VERSION "DNNBNNNYNNNNNNNNNNNNNNNNNNNNNNNNNNNNNNNNNN/4/%%%/4/'%**4NNN///"

NS_ :

BS_:

BU_: Vector__XXX xSolarWave xSolarSurveyor xSolarStorm xNova xMiata_SCP xMiata_AGS UI INV_CHG INV GATEWAY EMS DIAG CHG BMS BATTMON AGS

BO_ 2147573248 EmsCfg: 25 DIAG
 SG_ ShoreBreakerRatingMin : 40|16@1+ (0.01,0) [0|655.32] "A" DIAG,EMS,UI
 SG_ ShoreBreakerRatingMax : 56|16@1+ (0.01,0) [0|655.32] "A" DIAG,EMS,UI
 SG_ ShoreBreakerRating : 24|16@1+ (0.01,0) [0|655.32] "A" DIAG,EMS,UI
 SG_ ShoreBreakerMode : 16|2@1+ (1,0) [0|0] "" DIAG,EMS,UI
 SG_ RsvBits : 22|2@1+ (1,0) [0|0] "" DIAG,EMS,UI
 SG_ MsgCount : 2|6@1+ (1,0) [0|0] "" DIAG,EMS,UI
 SG_ GenWarmDelayMin : 160|16@1+ (0.01,0) [0|655.32] "seconds" DIAG,EMS,UI
 SG_ GenWarmDelayMax : 176|16@1+ (0.01,0) [0|655.32] "seconds" DIAG,EMS,UI
 SG_ GenWarmDelay : 144|16@1+ (0.01,0) [0|655.32] "seconds" DIAG,EMS,UI
 SG_ GenBreakerRatingMin : 88|16@1+ (0.01,0) [0|655.32] "A" DIAG,EMS,UI
 SG_ GenBreakerRatingMax : 104|16@1+ (0.01,0) [0|655.32] "A" DIAG,EMS,UI
 SG_ GenBreakerRating : 72|16@1+ (0.01,0) [0|655.32] "A" DIAG,EMS,UI
 SG_ GenBreakerMode : 18|2@1+ (1,0) [0|0] "" DIAG,EMS,UI
 SG_ ConSeqDelayMin : 128|8@1+ (1,0) [0|252] "seconds" DIAG,EMS,UI
 SG_ ConSeqDelayMax : 136|8@1+ (1,0) [0|252] "seconds" DIAG,EMS,UI
 SG_ ConSeqDelay : 120|8@1+ (1,0) [0|252] "seconds" DIAG,EMS,UI
 SG_ ConcurAccCtr : 8|8@1+ (1,0) [0|252] "" DIAG,EMS,UI
 SG_ CfgType : 0|2@1+ (1,0) [0|0] "" DIAG,EMS,UI
 SG_ BreakerDeratingEnDis : 20|2@1+ (1,0) [0|0] "" DIAG,EMS,UI
 SG_ AcDisqualifyPriority : 192|8@1+ (1,0) [0|252] "" DIAG,EMS,UI

BO_ 2147569664 DiagMfgCfg: 9 AGS
 SG_ RsvBits : 0|2@1+ (1,0) [0|0] "" AGS,BATTMON,CHG,DIAG,GATEWAY,INV,INV_CHG,UI,xMiata_AGS,xNova,xSolarSurveyor,xSolarWave
 SG_ MsgCount : 2|6@1+ (1,0) [0|0] "" AGS,BATTMON,CHG,DIAG,GATEWAY,INV,INV_CHG,UI,xMiata_AGS,xNova,xSolarSurveyor,xSolarWave
 SG_ MfgTime : 24|32@1+ (1,0) [0|4.29497E+09] "seconds" AGS,BATTMON,CHG,DIAG,GATEWAY,INV,INV_CHG,UI,xMiata_AGS,xNova,xSolarSurveyor,xSolarWave
 SG_ MfgStep : 16|8@1+ (1,0) [0|252] "" AGS,BATTMON,CHG,DIAG,GATEWAY,INV,INV_CHG,UI,xMiata_AGS,xNova,xSolarSurveyor,xSolarWave
 SG_ LocalOffsetMins : 56|16@1- (1,0) [-32768|32764] "minutes" AGS,BATTMON,CHG,DIAG,GATEWAY,INV,INV_CHG,UI,xMiata_AGS,xNova,xSolarSurveyor,xSolarWave
 SG_ ConcurAccCtr : 8|8@1+ (1,0) [0|252] "" AGS,BATTMON,CHG,DIAG,GATEWAY,INV,INV_CHG,UI,xMiata_AGS,xNova,xSolarSurveyor,xSolarWave

BO_ 2147568128 DiagIndicCmd: 223 DIAG
 SG_ IndicState : 6|2@1+ (1,0) [0|0] "" AGS,BATTMON,CHG,GATEWAY,INV,INV_CHG,UI,xMiata_AGS,xNova,xSolarWave
 SG_ IndicId : 0|6@1+ (1,0) [0|0] "" AGS,BATTMON,CHG,GATEWAY,INV,INV_CHG,UI,xMiata_AGS,xNova,xSolarWave

BO_ 2147568896 DiagFanCmd: 223 DIAG
 SG_ FanSpd : 8|8@1+ (1,0) [0|252] "%" AGS,BATTMON,CHG,DIAG,GATEWAY,INV,INV_CHG,UI,xSolarWave
 SG_ FanId : 0|8@1+ (1,0) [0|252] "" AGS,BATTMON,CHG,DIAG,GATEWAY,INV,INV_CHG,UI,xSolarWave

BO_ 2147568640 DiagCntctSts: 223 AGS
 SG_ RsvBits : 0|2@1+ (1,0) [0|0] "" DIAG
 SG_ MsgCount : 2|6@1+ (1,0) [0|0] "" DIAG
 SG_ CntctState : 14|2@1+ (1,0) [0|0] "" DIAG
 SG_ CntctId : 8|6@1+ (1,0) [0|0] "" DIAG

BO_ 2147568384 DiagCntctCmd: 223 DIAG
 SG_ CntctState : 6|2@1+ (1,0) [0|0] "" AGS,BATTMON,CHG,GATEWAY,INV,INV_CHG,UI,xMiata_AGS,xNova,xSolarWave
 SG_ CntctId : 0|6@1+ (1,0) [0|0] "" AGS,BATTMON,CHG,GATEWAY,INV,INV_CHG,UI,xMiata_AGS,xNova,xSolarWave

BO_ 2147561472 DevPokeAddr: 1785 DIAG
 SG_ StartMemAddr : 8|32@1+ (1,0) [0|4.29497E+09] "" AGS,BATTMON,CHG,GATEWAY,INV,INV_CHG,UI,xMiata_AGS,xSolarSurveyor
 SG_ RsvBits : 4|4@1+ (1,0) [0|0] "" AGS,BATTMON,CHG,GATEWAY,INV,INV_CHG,UI,xMiata_AGS,xSolarSurveyor
 SG_ ProcessorInst : 0|4@1+ (1,0) [0|0] "" AGS,BATTMON,CHG,GATEWAY,INV,INV_CHG,UI,xMiata_AGS,xSolarSurveyor
 SG_ NumBytesSet : 40|16@1+ (1,0) [0|65532] "" AGS,BATTMON,CHG,GATEWAY,INV,INV_CHG,UI,xMiata_AGS,xSolarSurveyor
 SG_ BytesSet : 56|8@1+ (1,0) [0|1785] "8-Bit Bytes" AGS,BATTMON,CHG,GATEWAY,INV,INV_CHG,UI,xMiata_AGS,xSolarSurveyor

BO_ 2147561216 DevPeekAddrRsp: 1785 AGS
 SG_ StartMemAddr : 8|32@1+ (1,0) [0|4.29497E+09] "" DIAG
 SG_ RsvBits : 4|4@1+ (1,0) [0|0] "" DIAG
 SG_ ProcessorInst : 0|4@1+ (1,0) [0|0] "" DIAG
 SG_ NumBytesGot : 40|16@1+ (1,0) [0|65532] "" DIAG
 SG_ BytesGot : 56|8@1+ (1,0) [0|1785] "8-Bit Bytes" DIAG

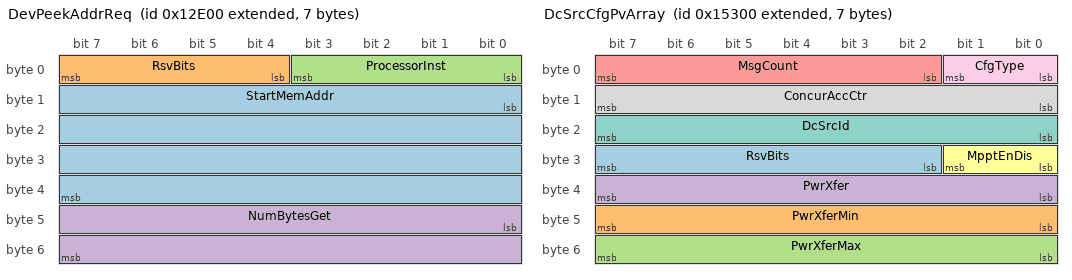
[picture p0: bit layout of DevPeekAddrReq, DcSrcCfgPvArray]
BO_ 2147560960 DevPeekAddrReq: 7 DIAG
 SG_ StartMemAddr : 8|32@1+ (1,0) [0|4.29497E+09] "" AGS,BATTMON,CHG,GATEWAY,INV,INV_CHG,UI,xMiata_AGS,xNova,xSolarSurveyor
 SG_ RsvBits : 4|4@1+ (1,0) [0|0] "" AGS,BATTMON,CHG,GATEWAY,INV,INV_CHG,UI,xMiata_AGS,xNova,xSolarSurveyor
 SG_ ProcessorInst : 0|4@1+ (1,0) [0|0] "" AGS,BATTMON,CHG,GATEWAY,INV,INV_CHG,UI,xMiata_AGS,xNova,xSolarSurveyor
 SG_ NumBytesGet : 40|16@1+ (1,0) [0|65532] "" AGS,BATTMON,CHG,GATEWAY,INV,INV_CHG,UI,xMiata_AGS,xNova,xSolarSurveyor

BO_ 2147563776 DebugFP: 223 AGS
 SG_ Data : 0|8@1+ (1,0) [0|1785] "8-Bit Bytes" AGS,BATTMON,CHG,DIAG,EMS,GATEWAY,INV,INV_CHG,UI,xSolarSurveyor,xSolarWave

BO_ 2147610821 DcSrcSts2: 21 BATTMON
 SG_ Voltage : 16|32@1- (0.001,0) [-2.14748E+06|2.14748E+06] "V" AGS,BATTMON,CHG,DIAG,EMS,GATEWAY,INV,INV_CHG,UI,xSolarSurveyor,xSolarWave
 SG_ RsvBits : 146|6@1+ (1,0) [0|0] "" AGS,BATTMON,CHG,DIAG,EMS,GATEWAY,INV,INV_CHG,UI,xSolarSurveyor,xSolarWave
 SG_ RsvBits : 0|2@1+ (1,0) [0|0] "" AGS,BATTMON,CHG,DIAG,EMS,GATEWAY,INV,INV_CHG,UI,xSolarSurveyor,xSolarWave
 SG_ RippleVoltage : 112|32@1+ (0.001,0) [0|4.29497E+06] "V" AGS,BATTMON,CHG,DIAG,EMS,GATEWAY,INV,INV_CHG,UI,xSolarSurveyor,xSolarWave
 SG_ Pwr : 80|32@1+ (1,0) [0|4.29497E+09] "W" AGS,BATTMON,CHG,DIAG,EMS,GATEWAY,INV,INV_CHG,UI,xSolarSurveyor,xSolarWave
 SG_ MsgCount : 2|6@1+ (1,0) [0|0] "" AGS,BATTMON,CHG,DIAG,EMS,GATEWAY,INV,INV_CHG,UI,xSolarSurveyor,xSolarWave
 SG_ DeratingSts : 144|2@1+ (1,0) [0|0] "" AGS,BATTMON,CHG,DIAG,EMS,GATEWAY,INV,INV_CHG,UI,xSolarSurveyor,xSolarWave
 SG_ DeratingReason : 152|16@1+ (1,0) [0|65532] "" AGS,BATTMON,CHG,DIAG,EMS,GATEWAY,INV,INV_CHG,UI,xSolarSurveyor,xSolarWave
 SG_ DcSrcId : 8|8@1+ (1,0) [0|252] "" AGS,BATTMON,CHG,DIAG,EMS,GATEWAY,INV,INV_CHG,UI,xSolarSurveyor,xSolarWave
 SG_ Current : 48|32@1- (0.001,0) [-2.14748E+06|2.14748E+06] "Amps" AGS,BATTMON,CHG,DIAG,EMS,GATEWAY,INV,INV_CHG,UI,xSolarSurveyor,xSolarWave

BO_ 2147610625 DcSrcSts: 24 BATTMON
 SG_ Voltage : 16|32@1- (0.001,0) [-2.14748E+06|2.14748E+06] "V" AGS,BATTMON,CHG,DIAG,GATEWAY,INV,INV_CHG,UI,xMiata_AGS
 SG_ TimeRemain : 112|16@1+ (1,0) [0|65532] "minutes" AGS,BATTMON,CHG,DIAG,GATEWAY,INV,INV_CHG,UI,xMiata_AGS
 SG_ TempSensId : 80|8@1+ (1,0) [0|252] "" AGS,BATTMON,CHG,DIAG,GATEWAY,INV,INV_CHG,UI,xMiata_AGS
 SG_ Temp : 88|16@1+ (0.01,0) [0|655.32] "°K" AGS,BATTMON,CHG,DIAG,GATEWAY,INV,INV_CHG,UI,xMiata_AGS
 SG_ Soh : 128|8@1+ (1,0) [0|252] "%" AGS,BATTMON,CHG,DIAG,GATEWAY,INV,INV_CHG,UI,xMiata_AGS
 SG_ Soc : 104|8@1+ (1,0) [0|252] "%" AGS,BATTMON,CHG,DIAG,GATEWAY,INV,INV_CHG,UI,xMiata_AGS
 SG_ RsvBits : 0|2@1+ (1,0) [0|0] "" AGS,BATTMON,CHG,DIAG,GATEWAY,INV,INV_CHG,UI,xMiata_AGS
 SG_ Pwr : 160|32@1+ (1,0) [0|4.29497E+09] "W" AGS,BATTMON,CHG,DIAG,GATEWAY,INV,INV_CHG,UI,xMiata_AGS
 SG_ MsgCount : 2|6@1+ (1,0) [0|0] "" AGS,BATTMON,CHG,DIAG,GATEWAY,INV,INV_CHG,UI,xMiata_AGS
 SG_ DcSrcId : 8|8@1+ (1,0) [0|252] "" AGS,BATTMON,CHG,DIAG,GATEWAY,INV,INV_CHG,UI,xMiata_AGS
 SG_ Current : 48|32@1- (0.001,0) [-2.14748E+06|2.14748E+06] "Amps" AGS,BATTMON,CHG,DIAG,GATEWAY,INV,INV_CHG,UI,xMiata_AGS
 SG_ BattCapRemain : 136|16@1+ (1,0) [0|65532] "Ah" AGS,BATTMON,CHG,DIAG,GATEWAY,INV,INV_CHG,UI,xMiata_AGS
 SG_ BattCapPer : 152|8@1+ (1,0) [0|252] "%" AGS,BATTMON,CHG,DIAG,GATEWAY,INV,INV_CHG,UI,xMiata_AGS

BO_ 2147549440 DcSrcCfgUv: 223 BMS
 SG_ UvLvlMin : 88|32@1- (0.001,0) [-2.14748E+06|2.14748E+06] "V" BMS,CHG,DIAG,INV,INV_CHG,UI,xNova,xSolarSurveyor,xSolarWave
 SG_ UvLvlMax : 120|32@1- (0.001,0) [-2.14748E+06|2.14748E+06] "V" BMS,CHG,DIAG,INV,INV_CHG,UI,xNova,xSolarSurveyor,xSolarWave
 SG_ UvLvl : 56|32@1- (0.001,0) [-2.14748E+06|2.14748E+06] "V" BMS,CHG,DIAG,INV,INV_CHG,UI,xNova,xSolarSurveyor,xSolarWave
 SG_ UvIntvlMin : 168|16@1+ (0.01,0) [0|655.32] "seconds" BMS,CHG,DIAG,INV,INV_CHG,UI,xNova,xSolarSurveyor,xSolarWave
 SG_ UvIntvlMax : 184|16@1+ (0.01,0) [0|655.32] "seconds" BMS,CHG,DIAG,INV,INV_CHG,UI,xNova,xSolarSurveyor,xSolarWave
 SG_ UvIntvl : 152|16@1+ (0.01,0) [0|655.32] "seconds" BMS,CHG,DIAG,INV,INV_CHG,UI,xNova,xSolarSurveyor,xSolarWave
 SG_ RefEvtId : 40|16@1+ (1,0) [0|65532] "" BMS,CHG,DIAG,INV,INV_CHG,UI,xNova,xSolarSurveyor,xSolarWave
 SG_ MsgCount : 2|6@1+ (1,0) [0|0] "" BMS,CHG,DIAG,INV,INV_CHG,UI,xNova,xSolarSurveyor,xSolarWave
 SG_ EvtId : 24|16@1+ (1,0) [0|65532] "" BMS,CHG,DIAG,INV,INV_CHG,UI,xNova,xSolarSurveyor,xSolarWave
 SG_ DcSrcId : 16|8@1+ (1,0) [0|252] "" BMS,CHG,DIAG,INV,INV_CHG,UI,xNova,xSolarSurveyor,xSolarWave
 SG_ ConcurAccCtr : 8|8@1+ (1,0) [0|252] "" BMS,CHG,DIAG,INV,INV_CHG,UI,xNova,xSolarSurveyor,xSolarWave
 SG_ CfgType : 0|2@1+ (1,0) [0|0] "" BMS,CHG,DIAG,INV,INV_CHG,UI,xNova,xSolarSurveyor,xSolarWave

BO_ 2147549952 DcSrcCfgUi: 223 CHG
 SG_ UiLvlMin : 88|32@1- (0.001,0) [-2.14748E+06|2.14748E+06] "Amps" CHG,DIAG,INV,INV_CHG,UI
 SG_ UiLvlMax : 120|32@1- (0.001,0) [-2.14748E+06|2.14748E+06] "Amps" CHG,DIAG,INV,INV_CHG,UI
 SG_ UiLvl : 56|32@1- (0.001,0) [-2.14748E+06|2.14748E+06] "Amps" CHG,DIAG,INV,INV_CHG,UI
 SG_ UiIntvlMin : 168|16@1+ (0.01,0) [0|655.32] "seconds" CHG,DIAG,INV,INV_CHG,UI
 SG_ UiIntvlMax : 184|16@1+ (0.01,0) [0|655.32] "seconds" CHG,DIAG,INV,INV_CHG,UI
 SG_ UiIntvl : 152|16@1+ (0.01,0) [0|655.32] "seconds" CHG,DIAG,INV,INV_CHG,UI
 SG_ RefEvtId : 40|16@1+ (1,0) [0|65532] "" CHG,DIAG,INV,INV_CHG,UI
 SG_ MsgCount : 2|6@1+ (1,0) [0|0] "" CHG,DIAG,INV,INV_CHG,UI
 SG_ EvtId : 24|16@1+ (1,0) [0|65532] "" CHG,DIAG,INV,INV_CHG,UI
 SG_ DcSrcId : 16|8@1+ (1,0) [0|252] "" CHG,DIAG,INV,INV_CHG,UI
 SG_ ConcurAccCtr : 8|8@1+ (1,0) [0|252] "" CHG,DIAG,INV,INV_CHG,UI
 SG_ CfgType : 0|2@1+ (1,0) [0|0] "" CHG,DIAG,INV,INV_CHG,UI

BO_ 2147550464 DcSrcCfgRipOvPeak: 223 CHG
 SG_ RefEvtId : 40|16@1+ (1,0) [0|65532] "" CHG,DIAG,INV,INV_CHG,UI
 SG_ PeakRipOvLvlMin : 88|32@1- (0.001,0) [-2.14748E+06|2.14748E+06] "V" CHG,DIAG,INV,INV_CHG,UI
 SG_ PeakRipOvLvlMax : 120|32@1- (0.001,0) [-2.14748E+06|2.14748E+06] "V" CHG,DIAG,INV,INV_CHG,UI
 SG_ PeakRipOvLvl : 56|32@1- (0.001,0) [-2.14748E+06|2.14748E+06] "V" CHG,DIAG,INV,INV_CHG,UI
 SG_ PeakRipOvIntvlMin : 168|16@1+ (0.01,0) [0|655.32] "seconds" CHG,DIAG,INV,INV_CHG,UI
 SG_ PeakRipOvIntvlMax : 184|16@1+ (0.01,0) [0|655.32] "seconds" CHG,DIAG,INV,INV_CHG,UI
 SG_ PeakRipOvIntvl : 152|16@1+ (0.01,0) [0|655.32] "seconds" CHG,DIAG,INV,INV_CHG,UI
 SG_ MsgCount : 2|6@1+ (1,0) [0|0] "" CHG,DIAG,INV,INV_CHG,UI
 SG_ EvtId : 24|16@1+ (1,0) [0|65532] "" CHG,DIAG,INV,INV_CHG,UI
 SG_ DcSrcId : 16|8@1+ (1,0) [0|252] "" CHG,DIAG,INV,INV_CHG,UI
 SG_ ConcurAccCtr : 8|8@1+ (1,0) [0|252] "" CHG,DIAG,INV,INV_CHG,UI
 SG_ CfgType : 0|2@1+ (1,0) [0|0] "" CHG,DIAG,INV,INV_CHG,UI

BO_ 2147599104 DcSrcCfgPvArray2: 19 CHG
 SG_ VMaxPwrMin : 88|32@1- (0.001,0) [-2.14748E+06|2.14748E+06] "V" CHG,DIAG,INV,INV_CHG,UI,xSolarSurveyor
 SG_ VMaxPwrMax : 120|32@1- (0.001,0) [-2.14748E+06|2.14748E+06] "V" CHG,DIAG,INV,INV_CHG,UI,xSolarSurveyor
 SG_ VMaxPwr : 56|32@1- (0.001,0) [-2.14748E+06|2.14748E+06] "V" CHG,DIAG,INV,INV_CHG,UI,xSolarSurveyor
 SG_ RsvBits : 26|6@1+ (1,0) [0|0] "" CHG,DIAG,INV,INV_CHG,UI,xSolarSurveyor
 SG_ PwrXferMin : 40|8@1+ (1,0) [0|252] "%" CHG,DIAG,INV,INV_CHG,UI,xSolarSurveyor
 SG_ PwrXferMax : 48|8@1+ (1,0) [0|252] "%" CHG,DIAG,INV,INV_CHG,UI,xSolarSurveyor
 SG_ PwrXfer : 32|8@1+ (1,0) [0|252] "%" CHG,DIAG,INV,INV_CHG,UI,xSolarSurveyor
 SG_ MsgCount : 2|6@1+ (1,0) [0|0] "" CHG,DIAG,INV,INV_CHG,UI,xSolarSurveyor
 SG_ MpptEnDis : 24|2@1+ (1,0) [0|0] "" CHG,DIAG,INV,INV_CHG,UI,xSolarSurveyor
 SG_ DcSrcId : 16|8@1+ (1,0) [0|252] "" CHG,DIAG,INV,INV_CHG,UI,xSolarSurveyor
 SG_ ConcurAccCtr : 8|8@1+ (1,0) [0|252] "" CHG,DIAG,INV,INV_CHG,UI,xSolarSurveyor
 SG_ CfgType : 0|2@1+ (1,0) [0|0] "" CHG,DIAG,INV,INV_CHG,UI,xSolarSurveyor

BO_ 2147570432 DcSrcCfgPvArray: 7 CHG
 SG_ RsvBits : 26|6@1+ (1,0) [0|0] "" CHG,DIAG,INV,INV_CHG,UI
 SG_ PwrXferMin : 40|8@1+ (1,0) [0|252] "%" CHG,DIAG,INV,INV_CHG,UI
 SG_ PwrXferMax : 48|8@1+ (1,0) [0|252] "%" CHG,DIAG,INV,INV_CHG,UI
 SG_ PwrXfer : 32|8@1+ (1,0) [0|252] "%" CHG,DIAG,INV,INV_CHG,UI
 SG_ MsgCount : 2|6@1+ (1,0) [0|0] "" CHG,DIAG,INV,INV_CHG,UI
 SG_ MpptEnDis : 24|2@1+ (1,0) [0|0] "" CHG,DIAG,INV,INV_CHG,UI
 SG_ DcSrcId : 16|8@1+ (1,0) [0|252] "" CHG,DIAG,INV,INV_CHG,UI
 SG_ ConcurAccCtr : 8|8@1+ (1,0) [0|252] "" CHG,DIAG,INV,INV_CHG,UI
 SG_ CfgType : 0|2@1+ (1,0) [0|0] "" CHG,DIAG,INV,INV_CHG,UI

BO_ 2147549696 DcSrcCfgOv: 223 BMS
 SG_ RefEvtId : 40|16@1+ (1,0) [0|65532] "" BMS,CHG,DIAG,INV,INV_CHG,UI,xNova,xSolarSurveyor,xSolarWave
 SG_ OvLvlMin : 88|32@1- (0.001,0) [-2.14748E+06|2.14748E+06] "V" BMS,CHG,DIAG,INV,INV_CHG,UI,xNova,xSolarSurveyor,xSolarWave
 SG_ OvLvlMax : 120|32@1- (0.001,0) [-2.14748E+06|2.14748E+06] "V" BMS,CHG,DIAG,INV,INV_CHG,UI,xNova,xSolarSurveyor,xSolarWave
 SG_ OvLvl : 56|32@1- (0.001,0) [-2.14748E+06|2.14748E+06] "V" BMS,CHG,DIAG,INV,INV_CHG,UI,xNova,xSolarSurveyor,xSolarWave
 SG_ OvIntvlMin : 168|16@1+ (0.01,0) [0|655.32] "seconds" BMS,CHG,DIAG,INV,INV_CHG,UI,xNova,xSolarSurveyor,xSolarWave
 SG_ OvIntvlMax : 184|16@1+ (0.01,0) [0|655.32] "seconds" BMS,CHG,DIAG,INV,INV_CHG,UI,xNova,xSolarSurveyor,xSolarWave
 SG_ OvIntvl : 152|16@1+ (0.01,0) [0|655.32] "seconds" BMS,CHG,DIAG,INV,INV_CHG,UI,xNova,xSolarSurveyor,xSolarWave
 SG_ MsgCount : 2|6@1+ (1,0) [0|0] "" BMS,CHG,DIAG,INV,INV_CHG,UI,xNova,xSolarSurveyor,xSolarWave
 SG_ EvtId : 24|16@1+ (1,0) [0|65532] "" BMS,CHG,DIAG,INV,INV_CHG,UI,xNova,xSolarSurveyor,xSolarWave
 SG_ DcSrcId : 16|8@1+ (1,0) [0|252] "" BMS,CHG,DIAG,INV,INV_CHG,UI,xNova,xSolarSurveyor,xSolarWave
 SG_ ConcurAccCtr : 8|8@1+ (1,0) [0|252] "" BMS,CHG,DIAG,INV,INV_CHG,UI,xNova,xSolarSurveyor,xSolarWave
 SG_ CfgType : 0|2@1+ (1,0) [0|0] "" BMS,CHG,DIAG,INV,INV_CHG,UI,xNova,xSolarSurveyor,xSolarWave

BO_ 2147550208 DcSrcCfgOi: 223 CHG
 SG_ RefEvtId : 40|16@1+ (1,0) [0|65532] "" CHG,DIAG,INV,INV_CHG,UI
 SG_ OiLvlMin : 88|32@1- (0.001,0) [-2.14748E+06|2.14748E+06] "Amps" CHG,DIAG,INV,INV_CHG,UI
 SG_ OiLvlMax : 120|32@1- (0.001,0) [-2.14748E+06|2.14748E+06] "Amps" CHG,DIAG,INV,INV_CHG,UI
 SG_ OiLvl : 56|32@1- (0.001,0) [-2.14748E+06|2.14748E+06] "Amps" CHG,DIAG,INV,INV_CHG,UI
 SG_ OiIntvlMin : 168|16@1+ (0.01,0) [0|655.32] "seconds" CHG,DIAG,INV,INV_CHG,UI
 SG_ OiIntvlMax : 184|16@1+ (0.01,0) [0|655.32] "seconds" CHG,DIAG,INV,INV_CHG,UI
 SG_ OiIntvl : 152|16@1+ (0.01,0) [0|655.32] "seconds" CHG,DIAG,INV,INV_CHG,UI
 SG_ MsgCount : 2|6@1+ (1,0) [0|0] "" CHG,DIAG,INV,INV_CHG,UI
 SG_ EvtId : 24|16@1+ (1,0) [0|65532] "" CHG,DIAG,INV,INV_CHG,UI
 SG_ DcSrcId : 16|8@1+ (1,0) [0|252] "" CHG,DIAG,INV,INV_CHG,UI
 SG_ ConcurAccCtr : 8|8@1+ (1,0) [0|252] "" CHG,DIAG,INV,INV_CHG,UI
 SG_ CfgType : 0|2@1+ (1,0) [0|0] "" CHG,DIAG,INV,INV_CHG,UI

BO_ 2147556608 DcSrcCfgBatt: 24 BATTMON
 SG_ PeukertExponentMin : 152|8@1+ (0.002,1) [1|1.5] "" BATTMON,BMS,CHG,DIAG,EMS,INV,INV_CHG,UI,xNova,xSolarSurveyor,xSolarWave
 SG_ PeukertExponentMax : 160|8@1+ (0.002,1) [1|1.5] "" BATTMON,BMS,CHG,DIAG,EMS,INV,INV_CHG,UI,xNova,xSolarSurveyor,xSolarWave
 SG_ PeukertExponent : 144|8@1+ (0.002,1) [1|1.5] "" BATTMON,BMS,CHG,DIAG,EMS,INV,INV_CHG,UI,xNova,xSolarSurveyor,xSolarWave
 SG_ NomV : 32|32@1- (0.001,0) [-2.14748E+06|2.14748E+06] "V" BATTMON,BMS,CHG,DIAG,EMS,INV,INV_CHG,UI,xNova,xSolarSurveyor,xSolarWave
 SG_ MsgCount : 2|6@1+ (1,0) [0|0] "" BATTMON,BMS,CHG,DIAG,EMS,INV,INV_CHG,UI,xNova,xSolarSurveyor,xSolarWave
 SG_ DcSrcId : 16|8@1+ (1,0) [0|252] "" BATTMON,BMS,CHG,DIAG,EMS,INV,INV_CHG,UI,xNova,xSolarSurveyor,xSolarWave
 SG_ ConcurAccCtr : 8|8@1+ (1,0) [0|252] "" BATTMON,BMS,CHG,DIAG,EMS,INV,INV_CHG,UI,xNova,xSolarSurveyor,xSolarWave
 SG_ ChgEfficFactorMin : 176|8@1- (1,0) [-124|124] "%" BATTMON,BMS,CHG,DIAG,EMS,INV,INV_CHG,UI,xNova,xSolarSurveyor,xSolarWave
 SG_ ChgEfficFactorMax : 184|8@1- (1,0) [-124|124] "%" BATTMON,BMS,CHG,DIAG,EMS,INV,INV_CHG,UI,xNova,xSolarSurveyor,xSolarWave
 SG_ ChgEfficFactor : 168|8@1- (1,0) [-124|124] "%" BATTMON,BMS,CHG,DIAG,EMS,INV,INV_CHG,UI,xNova,xSolarSurveyor,xSolarWave
 SG_ CfgType : 0|2@1+ (1,0) [0|0] "" BATTMON,BMS,CHG,DIAG,EMS,INV,INV_CHG,UI,xNova,xSolarSurveyor,xSolarWave
 SG_ BattType : 24|8@1+ (1,0) [0|252] "" BATTMON,BMS,CHG,DIAG,EMS,INV,INV_CHG,UI,xNova,xSolarSurveyor,xSolarWave
 SG_ BattTempCoeffMin : 120|8@1+ (0.001,0) [0|0.252] "V/K" BATTMON,BMS,CHG,DIAG,EMS,INV,INV_CHG,UI,xNova,xSolarSurveyor,xSolarWave
 SG_ BattTempCoeffMax : 128|8@1+ (0.001,0) [0|0.252] "V/K" BATTMON,BMS,CHG,DIAG,EMS,INV,INV_CHG,UI,xNova,xSolarSurveyor,xSolarWave
 SG_ BattTempCoeff : 112|8@1+ (0.001,0) [0|0.252] "V/K" BATTMON,BMS,CHG,DIAG,EMS,INV,INV_CHG,UI,xNova,xSolarSurveyor,xSolarWave
 SG_ BattChem : 136|8@1+ (1,0) [0|252] "" BATTMON,BMS,CHG,DIAG,EMS,INV,INV_CHG,UI,xNova,xSolarSurveyor,xSolarWave
 SG_ BattAmpHrRatingMin : 80|16@1+ (1,0) [0|65532] "Ah" BATTMON,BMS,CHG,DIAG,EMS,INV,INV_CHG,UI,xNova,xSolarSurveyor,xSolarWave
 SG_ BattAmpHrRatingMax : 96|16@1+ (1,0) [0|65532] "Ah" BATTMON,BMS,CHG,DIAG,EMS,INV,INV_CHG,UI,xNova,xSolarSurveyor,xSolarWave
 SG_ BattAmpHrRating : 64|16@1+ (1,0) [0|65532] "Ah" BATTMON,BMS,CHG,DIAG,EMS,INV,INV_CHG,UI,xNova,xSolarSurveyor,xSolarWave

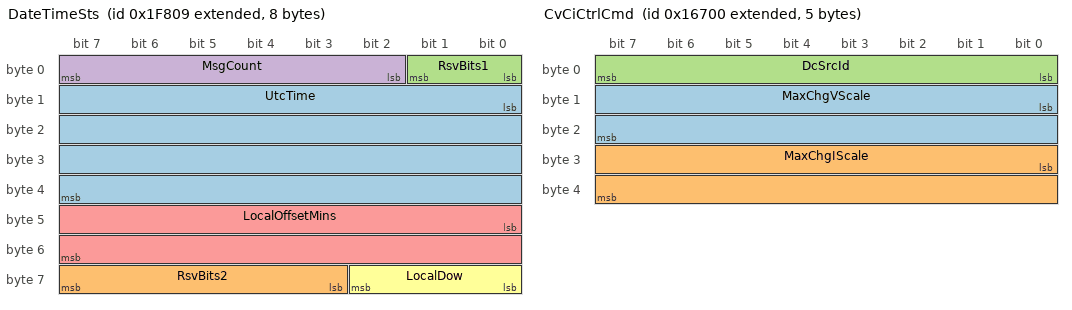
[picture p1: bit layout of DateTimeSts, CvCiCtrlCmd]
BO_ 2147612681 DateTimeSts: 8 DIAG
 SG_ UtcTime : 8|32@1+ (1,0) [0|4.29497E+09] "seconds" AGS,BATTMON,BMS,CHG,DIAG,EMS,GATEWAY,INV,INV_CHG,UI,xMiata_AGS,xNova,xSolarSurveyor,xSolarWave
 SG_ RsvBits2 : 59|5@1+ (1,0) [0|0] "" AGS,BATTMON,BMS,CHG,DIAG,EMS,GATEWAY,INV,INV_CHG,UI,xMiata_AGS,xNova,xSolarSurveyor,xSolarWave
 SG_ RsvBits1 : 0|2@1+ (1,0) [0|0] "" AGS,BATTMON,BMS,CHG,DIAG,EMS,GATEWAY,INV,INV_CHG,UI,xMiata_AGS,xNova,xSolarSurveyor,xSolarWave
 SG_ MsgCount : 2|6@1+ (1,0) [0|0] "" AGS,BATTMON,BMS,CHG,DIAG,EMS,GATEWAY,INV,INV_CHG,UI,xMiata_AGS,xNova,xSolarSurveyor,xSolarWave
 SG_ LocalOffsetMins : 40|16@1- (1,0) [-32768|32764] "minutes" AGS,BATTMON,BMS,CHG,DIAG,EMS,GATEWAY,INV,INV_CHG,UI,xMiata_AGS,xNova,xSolarSurveyor,xSolarWave
 SG_ LocalDow : 56|3@1+ (1,0) [0|0] "" AGS,BATTMON,BMS,CHG,DIAG,EMS,GATEWAY,INV,INV_CHG,UI,xMiata_AGS,xNova,xSolarSurveyor,xSolarWave

BO_ 2147567616 DateTimeCfg: 9 DIAG
 SG_ UtcTime : 16|32@1+ (1,0) [0|4.29497E+09] "seconds" DIAG,UI,xSolarWave
 SG_ RsvBits : 67|5@1+ (1,0) [0|0] "" DIAG,UI,xSolarWave
 SG_ MsgCount : 2|6@1+ (1,0) [0|0] "" DIAG,UI,xSolarWave
 SG_ LocalOffsetMins : 48|16@1- (1,0) [-32768|32764] "minutes" DIAG,UI,xSolarWave
 SG_ LocalDow : 64|3@1+ (1,0) [0|0] "" DIAG,UI,xSolarWave
 SG_ ConcurAccCtr : 8|8@1+ (1,0) [0|252] "" DIAG,UI,xSolarWave
 SG_ CfgType : 0|2@1+ (1,0) [0|0] "" DIAG,UI,xSolarWave

BO_ 2147575552 CvCiCtrlCmd: 5 DIAG
 SG_ MaxChgVScale : 8|16@1+ (0.01,0) [0|655.32] "%" CHG,INV_CHG,xSolarSurveyor,xSolarWave
 SG_ MaxChgIScale : 24|16@1+ (0.01,0) [0|655.32] "%" CHG,INV_CHG,xSolarSurveyor,xSolarWave
 SG_ DcSrcId : 0|8@1+ (1,0) [0|252] "" CHG,INV_CHG,xSolarSurveyor,xSolarWave

BO_ 2147565568 CtrlCmd: 1 BMS
 SG_ DesiredMode : 0|8@1+ (1,0) [0|252] "" AGS,BATTMON,BMS,CHG,EMS,GATEWAY,INV,INV_CHG,UI,xMiata_AGS,xNova,xSolarSurveyor,xSolarWave

BO_ 2147606016 ComplexReq: 1785 DIAG
 SG_ ParamGrpNum : 0|24@1+ (1,0) [0|0] "" AGS,BATTMON,CHG,DIAG,EMS,GATEWAY,INV,INV_CHG,UI,xSolarSurveyor,xSolarWave
 SG_ FieldValue : 32|32@1+ (1,0) [0|4.29497E+09] "" AGS,BATTMON,CHG,DIAG,EMS,GATEWAY,INV,INV_CHG,UI,xSolarSurveyor,xSolarWave
 SG_ Field : 24|8@1+ (1,0) [0|252] "" AGS,BATTMON,CHG,DIAG,EMS,GATEWAY,INV,INV_CHG,UI,xSolarSurveyor,xSolarWave

BO_ 2147610626 CommStats: 25 AGS
 SG_ TxFrameDropCnt : 136|16@1+ (1,0) [0|65532] "" DIAG,UI
 SG_ TxExtFrameCnt : 8|32@1+ (1,0) [0|4.29497E+09] "" DIAG,UI
 SG_ TxErrCnt : 88|16@1+ (1,0) [0|65532] "" DIAG,UI
 SG_ RxFrameDropCnt : 120|16@1+ (1,0) [0|65532] "" DIAG,UI
 SG_ RxExtFrameCnt : 40|32@1+ (1,0) [0|4.29497E+09] "" DIAG,UI
 SG_ RxErrCnt : 72|16@1+ (1,0) [0|65532] "" DIAG,UI
 SG_ RsvBits : 0|2@1+ (1,0) [0|0] "" DIAG,UI
 SG_ MsgCount : 2|6@1+ (1,0) [0|0] "" DIAG,UI
 SG_ MpToCnt : 168|8@1+ (1,0) [0|252] "" DIAG,UI
 SG_ MpLateFrameCnt : 176|8@1+ (1,0) [0|252] "" DIAG,UI
 SG_ MemAllocFailCnt : 152|16@1+ (1,0) [0|65532] "" DIAG,UI
 SG_ HeapFreeMin : 184|16@1+ (1,0) [0|65532] "" DIAG,UI
 SG_ BusOffCnt : 104|16@1+ (1,0) [0|65532] "" DIAG,UI

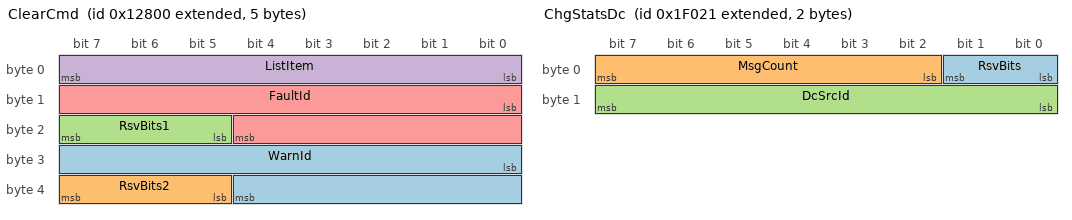
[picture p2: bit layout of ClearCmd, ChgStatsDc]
BO_ 2147559424 ClearCmd: 5 DIAG
 SG_ WarnId : 24|13@1+ (1,0) [0|0] "" AGS,BATTMON,BMS,CHG,DIAG,EMS,GATEWAY,INV,INV_CHG,UI,xMiata_AGS,xNova,xSolarSurveyor,xSolarWave
 SG_ RsvBits2 : 37|3@1+ (1,0) [0|0] "" AGS,BATTMON,BMS,CHG,DIAG,EMS,GATEWAY,INV,INV_CHG,UI,xMiata_AGS,xNova,xSolarSurveyor,xSolarWave
 SG_ RsvBits1 : 21|3@1+ (1,0) [0|0] "" AGS,BATTMON,BMS,CHG,DIAG,EMS,GATEWAY,INV,INV_CHG,UI,xMiata_AGS,xNova,xSolarSurveyor,xSolarWave
 SG_ ListItem : 0|8@1+ (1,0) [0|252] "" AGS,BATTMON,BMS,CHG,DIAG,EMS,GATEWAY,INV,INV_CHG,UI,xMiata_AGS,xNova,xSolarSurveyor,xSolarWave
 SG_ FaultId : 8|13@1+ (1,0) [0|0] "" AGS,BATTMON,BMS,CHG,DIAG,EMS,GATEWAY,INV,INV_CHG,UI,xMiata_AGS,xNova,xSolarSurveyor,xSolarWave

BO_ 2147610638 ChgSts: 17 CHG
 SG_ RsvBits2 : 126|2@1+ (1,0) [0|0] "" AGS,BATTMON,BMS,CHG,DIAG,GATEWAY,INV,INV_CHG,UI,xMiata_AGS,xSolarSurveyor,xSolarWave
 SG_ RsvBits1 : 0|2@1+ (1,0) [0|0] "" AGS,BATTMON,BMS,CHG,DIAG,GATEWAY,INV,INV_CHG,UI,xMiata_AGS,xSolarSurveyor,xSolarWave
 SG_ OpState : 96|16@1+ (1,0) [0|65532] "" AGS,BATTMON,BMS,CHG,DIAG,GATEWAY,INV,INV_CHG,UI,xMiata_AGS,xSolarSurveyor,xSolarWave
 SG_ MsgCount : 2|6@1+ (1,0) [0|0] "" AGS,BATTMON,BMS,CHG,DIAG,GATEWAY,INV,INV_CHG,UI,xMiata_AGS,xSolarSurveyor,xSolarWave
 SG_ EqlzTimeRemain : 128|8@1+ (1,0) [0|252] "minutes" AGS,BATTMON,BMS,CHG,DIAG,GATEWAY,INV,INV_CHG,UI,xMiata_AGS,xSolarSurveyor,xSolarWave
 SG_ EqlzPending : 124|2@1+ (1,0) [0|0] "" AGS,BATTMON,BMS,CHG,DIAG,GATEWAY,INV,INV_CHG,UI,xMiata_AGS,xSolarSurveyor,xSolarWave
 SG_ DcSrcId : 8|8@1+ (1,0) [0|252] "" AGS,BATTMON,BMS,CHG,DIAG,GATEWAY,INV,INV_CHG,UI,xMiata_AGS,xSolarSurveyor,xSolarWave
 SG_ CtrlV : 16|32@1- (0.001,0) [-2.14748E+06|2.14748E+06] "V" AGS,BATTMON,BMS,CHG,DIAG,GATEWAY,INV,INV_CHG,UI,xMiata_AGS,xSolarSurveyor,xSolarWave
 SG_ CtrlIPer : 80|8@1+ (1,0) [0|252] "%" AGS,BATTMON,BMS,CHG,DIAG,GATEWAY,INV,INV_CHG,UI,xMiata_AGS,xSolarSurveyor,xSolarWave
 SG_ CtrlI : 48|32@1- (0.001,0) [-2.14748E+06|2.14748E+06] "Amps" AGS,BATTMON,BMS,CHG,DIAG,GATEWAY,INV,INV_CHG,UI,xMiata_AGS,xSolarSurveyor,xSolarWave
 SG_ ChgMode : 112|8@1+ (1,0) [0|252] "" AGS,BATTMON,BMS,CHG,DIAG,GATEWAY,INV,INV_CHG,UI,xMiata_AGS,xSolarSurveyor,xSolarWave
 SG_ ChgEnDis : 120|2@1+ (1,0) [0|0] "" AGS,BATTMON,BMS,CHG,DIAG,GATEWAY,INV,INV_CHG,UI,xMiata_AGS,xSolarSurveyor,xSolarWave
 SG_ ChgAlgorithm : 88|8@1+ (1,0) [0|252] "" AGS,BATTMON,BMS,CHG,DIAG,GATEWAY,INV,INV_CHG,UI,xMiata_AGS,xSolarSurveyor,xSolarWave
 SG_ BattTempSensorPresent : 122|2@1+ (1,0) [0|0] "" AGS,BATTMON,BMS,CHG,DIAG,GATEWAY,INV,INV_CHG,UI,xMiata_AGS,xSolarSurveyor,xSolarWave

BO_ 2147610658 ChgStatsIntTemp: 223 CHG
 SG_ TempSensId : 8|8@1+ (1,0) [0|252] "" DIAG,UI
 SG_ TempMax : 16|16@1+ (0.01,0) [0|655.32] "°K" DIAG,UI
 SG_ RsvBits : 0|2@1+ (1,0) [0|0] "" DIAG,UI
 SG_ MsgCount : 2|6@1+ (1,0) [0|0] "" DIAG,UI

BO_ 2147610659 ChgStatsExtTemp: 223 CHG
 SG_ TempSensId : 8|8@1+ (1,0) [0|252] "" DIAG,UI
 SG_ TempMin : 16|16@1+ (0.01,0) [0|655.32] "°K" DIAG,UI
 SG_ TempMax : 32|16@1+ (0.01,0) [0|655.32] "°K" DIAG,UI
 SG_ RsvBits : 0|2@1+ (1,0) [0|0] "" DIAG,UI
 SG_ MsgCount : 2|6@1+ (1,0) [0|0] "" DIAG,UI

BO_ 2147610817 ChgStatsDc2: 223 CHG
 SG_ VoltageMin : 56|32@1- (0.001,0) [-2.14748E+06|2.14748E+06] "V" DIAG,UI
 SG_ VoltageMax : 88|32@1- (0.001,0) [-2.14748E+06|2.14748E+06] "V" DIAG,UI
 SG_ RsvBits : 0|2@1+ (1,0) [0|0] "" DIAG,UI
 SG_ PreviousPeriodCount : 19|5@1+ (1,0) [0|0] "" DIAG,UI
 SG_ PreviousPeriod : 16|3@1+ (1,0) [0|0] "" DIAG,UI
 SG_ PeakPower : 152|16@1+ (1,0) [0|65532] "W" DIAG,UI
 SG_ MsgCount : 2|6@1+ (1,0) [0|0] "" DIAG,UI
 SG_ Energy : 120|32@1+ (1,0) [0|4.29497E+09] "W h" DIAG,UI
 SG_ DcSrcId : 8|8@1+ (1,0) [0|252] "" DIAG,UI
 SG_ CurrentMax : 24|32@1- (0.001,0) [-2.14748E+06|2.14748E+06] "Amps" DIAG,UI

BO_ 2147610657 ChgStatsDc: 2 CHG
 SG_ RsvBits : 0|2@1+ (1,0) [0|0] "" DIAG,UI
 SG_ MsgCount : 2|6@1+ (1,0) [0|0] "" DIAG,UI
 SG_ DcSrcId : 8|8@1+ (1,0) [0|252] "" DIAG,UI

BO_ 2147610814 ChgStatsBatt2: 223 CHG
 SG_ VoltageMin : 88|32@1- (0.001,0) [-2.14748E+06|2.14748E+06] "V" DIAG,UI,xSolarSurveyor,xSolarWave
 SG_ VoltageMax : 120|32@1- (0.001,0) [-2.14748E+06|2.14748E+06] "V" DIAG,UI,xSolarSurveyor,xSolarWave
 SG_ RsvBits : 0|2@1+ (1,0) [0|0] "" DIAG,UI,xSolarSurveyor,xSolarWave
 SG_ PreviousPeriodCount : 51|5@1+ (1,0) [0|0] "" DIAG,UI,xSolarSurveyor,xSolarWave
 SG_ PreviousPeriod : 48|3@1+ (1,0) [0|0] "" DIAG,UI,xSolarSurveyor,xSolarWave
 SG_ PeakPower : 248|16@1+ (1,0) [0|65532] "W" DIAG,UI,xSolarSurveyor,xSolarWave
 SG_ MsgCount : 2|6@1+ (1,0) [0|0] "" DIAG,UI,xSolarSurveyor,xSolarWave
 SG_ LastEqualized : 16|32@1+ (1,0) [0|4.29497E+09] "seconds" DIAG,UI,xSolarSurveyor,xSolarWave
 SG_ FloatTime : 216|32@1+ (1,0) [0|4.29497E+09] "seconds" DIAG,UI,xSolarSurveyor,xSolarWave
 SG_ Energy : 184|32@1+ (1,0) [0|4.29497E+09] "W h" DIAG,UI,xSolarSurveyor,xSolarWave
 SG_ DcSrcId : 8|8@1+ (1,0) [0|252] "" DIAG,UI,xSolarSurveyor,xSolarWave
 SG_ CurrentMax : 56|32@1- (0.001,0) [-2.14748E+06|2.14748E+06] "Amps" DIAG,UI,xSolarSurveyor,xSolarWave
 SG_ CapacityReturned : 152|32@1- (1,0) [-2.14748E+09|2.14748E+09] "Ah" DIAG,UI,xSolarSurveyor,xSolarWave

BO_ 2147610816 ChgStatsAc2: 223 CHG
 SG_ VoltageMin : 96|32@1+ (0.001,0) [0|4.29497E+06] "V" DIAG,UI
 SG_ VoltageMax : 128|32@1+ (0.001,0) [0|4.29497E+06] "V" DIAG,UI
 SG_ RsvBits : 0|2@1+ (1,0) [0|0] "" DIAG,UI
 SG_ PreviousPeriodCount : 19|5@1+ (1,0) [0|0] "" DIAG,UI
 SG_ PreviousPeriod : 16|3@1+ (1,0) [0|0] "" DIAG,UI
 SG_ MsgCount : 2|6@1+ (1,0) [0|0] "" DIAG,UI
 SG_ Line : 24|8@1+ (1,0) [0|252] "" DIAG,UI
 SG_ FreqMin : 32|16@1+ (0.01,0) [0|655.32] "Hz" DIAG,UI
 SG_ FreqMax : 48|16@1+ (0.01,0) [0|655.32] "Hz" DIAG,UI
 SG_ CurrentMax : 64|32@1+ (0.001,0) [0|4.29497E+06] "Amps" DIAG,UI
 SG_ AcSrcId : 8|8@1+ (1,0) [0|252] "" DIAG,UI

BO_ 2147610650 ChgStatsAc: 223 CHG
 SG_ VoltageMin : 88|32@1+ (0.001,0) [0|4.29497E+06] "V" DIAG,UI
 SG_ VoltageMax : 120|32@1+ (0.001,0) [0|4.29497E+06] "V" DIAG,UI
 SG_ RsvBits : 0|2@1+ (1,0) [0|0] "" DIAG,UI
 SG_ MsgCount : 2|6@1+ (1,0) [0|0] "" DIAG,UI
 SG_ Line : 16|8@1+ (1,0) [0|252] "" DIAG,UI
 SG_ FreqMin : 24|16@1+ (0.01,0) [0|655.32] "Hz" DIAG,UI
 SG_ FreqMax : 40|16@1+ (0.01,0) [0|655.32] "Hz" DIAG,UI
 SG_ CurrentMax : 56|32@1+ (0.001,0) [0|4.29497E+06] "Amps" DIAG,UI
 SG_ AcSrcId : 8|8@1+ (1,0) [0|252] "" DIAG,UI

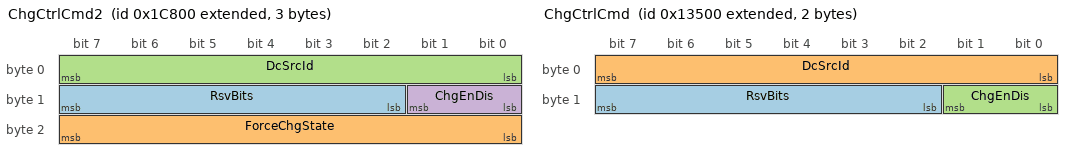
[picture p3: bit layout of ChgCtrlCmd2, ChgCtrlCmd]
BO_ 2147600384 ChgCtrlCmd2: 3 BMS
 SG_ RsvBits : 10|6@1+ (1,0) [0|0] "" CHG,INV_CHG,xNova,xSolarSurveyor,xSolarWave
 SG_ ForceChgState : 16|8@1+ (1,0) [0|252] "" CHG,INV_CHG,xNova,xSolarSurveyor,xSolarWave
 SG_ DcSrcId : 0|8@1+ (1,0) [0|252] "" CHG,INV_CHG,xNova,xSolarSurveyor,xSolarWave
 SG_ ChgEnDis : 8|2@1+ (1,0) [0|0] "" CHG,INV_CHG,xNova,xSolarSurveyor,xSolarWave

BO_ 2147562752 ChgCtrlCmd: 2 DIAG
 SG_ RsvBits : 10|6@1+ (1,0) [0|0] "" CHG,INV_CHG,xNova
 SG_ DcSrcId : 0|8@1+ (1,0) [0|252] "" CHG,INV_CHG,xNova
 SG_ ChgEnDis : 8|2@1+ (1,0) [0|0] "" CHG,INV_CHG,xNova

BO_ 2147555584 ChgCfgOvercharge: 34 CHG
 SG_ OChgPeriodToMin : 240|16@1+ (1,0) [0|65532] "seconds" CHG,DIAG,INV_CHG,UI
 SG_ OChgPeriodToMax : 256|16@1+ (1,0) [0|65532] "seconds" CHG,DIAG,INV_CHG,UI
 SG_ OChgPeriodTo : 224|16@1+ (1,0) [0|65532] "seconds" CHG,DIAG,INV_CHG,UI
 SG_ MsgCount : 2|6@1+ (1,0) [0|0] "" CHG,DIAG,INV_CHG,UI
 SG_ DesiredOChgVMin : 64|32@1- (0.001,0) [-2.14748E+06|2.14748E+06] "V" CHG,DIAG,INV_CHG,UI
 SG_ DesiredOChgVMax : 96|32@1- (0.001,0) [-2.14748E+06|2.14748E+06] "V" CHG,DIAG,INV_CHG,UI
 SG_ DesiredOChgV : 32|32@1- (0.001,0) [-2.14748E+06|2.14748E+06] "V" CHG,DIAG,INV_CHG,UI
 SG_ DesiredOChgIMin : 160|32@1- (0.001,0) [-2.14748E+06|2.14748E+06] "Amps" CHG,DIAG,INV_CHG,UI
 SG_ DesiredOChgIMax : 192|32@1- (0.001,0) [-2.14748E+06|2.14748E+06] "Amps" CHG,DIAG,INV_CHG,UI
 SG_ DesiredOChgI : 128|32@1- (0.001,0) [-2.14748E+06|2.14748E+06] "Amps" CHG,DIAG,INV_CHG,UI
 SG_ DcSrcId : 16|8@1+ (1,0) [0|252] "" CHG,DIAG,INV_CHG,UI
 SG_ ConcurAccCtr : 8|8@1+ (1,0) [0|252] "" CHG,DIAG,INV_CHG,UI
 SG_ CfgType : 0|2@1+ (1,0) [0|0] "" CHG,DIAG,INV_CHG,UI
 SG_ BattType : 24|8@1+ (1,0) [0|252] "" CHG,DIAG,INV_CHG,UI

BO_ 2147559168 ChgCfgMultipleNodes: 32 CHG
 SG_ NomDcVMin : 48|32@1- (0.001,0) [-2.14748E+06|2.14748E+06] "V" CHG,DIAG,INV_CHG,UI,xSolarWave
 SG_ NomDcVMax : 80|32@1- (0.001,0) [-2.14748E+06|2.14748E+06] "V" CHG,DIAG,INV_CHG,UI,xSolarWave
 SG_ NomDcV : 16|32@1- (0.001,0) [-2.14748E+06|2.14748E+06] "V" CHG,DIAG,INV_CHG,UI,xSolarWave
 SG_ MsgCount : 2|6@1+ (1,0) [0|0] "" CHG,DIAG,INV_CHG,UI,xSolarWave
 SG_ MaxDcIMin : 144|32@1- (0.001,0) [-2.14748E+06|2.14748E+06] "Amps" CHG,DIAG,INV_CHG,UI,xSolarWave
 SG_ MaxDcIMax : 176|32@1- (0.001,0) [-2.14748E+06|2.14748E+06] "Amps" CHG,DIAG,INV_CHG,UI,xSolarWave
 SG_ MaxDcI : 112|32@1- (0.001,0) [-2.14748E+06|2.14748E+06] "Amps" CHG,DIAG,INV_CHG,UI,xSolarWave
 SG_ ConcurAccCtr : 8|8@1+ (1,0) [0|252] "" CHG,DIAG,INV_CHG,UI,xSolarWave
 SG_ CfgType : 0|2@1+ (1,0) [0|0] "" CHG,DIAG,INV_CHG,UI,xSolarWave
 SG_ AcInBreakerSzMin : 224|16@1+ (0.01,0) [0|655.32] "A" CHG,DIAG,INV_CHG,UI,xSolarWave
 SG_ AcInBreakerSzMax : 240|16@1+ (0.01,0) [0|655.32] "A" CHG,DIAG,INV_CHG,UI,xSolarWave
 SG_ AcInBreakerSz : 208|16@1+ (0.01,0) [0|655.32] "A" CHG,DIAG,INV_CHG,UI,xSolarWave

BO_ 2147555840 ChgCfgFloat: 52 BMS
 SG_ MsgCount : 2|6@1+ (1,0) [0|0] "" BMS,CHG,DIAG,INV_CHG,UI,xNova,xSolarSurveyor,xSolarWave
 SG_ FloatTermVMin : 256|32@1- (0.001,0) [-2.14748E+06|2.14748E+06] "V" BMS,CHG,DIAG,INV_CHG,UI,xNova,xSolarSurveyor,xSolarWave
 SG_ FloatTermVMax : 288|32@1- (0.001,0) [-2.14748E+06|2.14748E+06] "V" BMS,CHG,DIAG,INV_CHG,UI,xNova,xSolarSurveyor,xSolarWave
 SG_ FloatTermV : 224|32@1- (0.001,0) [-2.14748E+06|2.14748E+06] "V" BMS,CHG,DIAG,INV_CHG,UI,xNova,xSolarSurveyor,xSolarWave
 SG_ FloatTermTimeMin : 336|16@1+ (1,0) [0|65532] "seconds" BMS,CHG,DIAG,INV_CHG,UI,xNova,xSolarSurveyor,xSolarWave
 SG_ FloatTermTimeMax : 352|16@1+ (1,0) [0|65532] "seconds" BMS,CHG,DIAG,INV_CHG,UI,xNova,xSolarSurveyor,xSolarWave
 SG_ FloatTermTime : 320|16@1+ (1,0) [0|65532] "seconds" BMS,CHG,DIAG,INV_CHG,UI,xNova,xSolarSurveyor,xSolarWave
 SG_ FloatPeriodToMin : 384|16@1+ (0.1,0) [0|6553.2] "hours" BMS,CHG,DIAG,INV_CHG,UI,xNova,xSolarSurveyor,xSolarWave
 SG_ FloatPeriodToMax : 400|16@1+ (0.1,0) [0|6553.2] "hours" BMS,CHG,DIAG,INV_CHG,UI,xNova,xSolarSurveyor,xSolarWave
 SG_ FloatPeriodTo : 368|16@1+ (0.1,0) [0|6553.2] "hours" BMS,CHG,DIAG,INV_CHG,UI,xNova,xSolarSurveyor,xSolarWave
 SG_ DesiredFloatVMin : 64|32@1- (0.001,0) [-2.14748E+06|2.14748E+06] "V" BMS,CHG,DIAG,INV_CHG,UI,xNova,xSolarSurveyor,xSolarWave
 SG_ DesiredFloatVMax : 96|32@1- (0.001,0) [-2.14748E+06|2.14748E+06] "V" BMS,CHG,DIAG,INV_CHG,UI,xNova,xSolarSurveyor,xSolarWave
 SG_ DesiredFloatV : 32|32@1- (0.001,0) [-2.14748E+06|2.14748E+06] "V" BMS,CHG,DIAG,INV_CHG,UI,xNova,xSolarSurveyor,xSolarWave
 SG_ DesiredFloatIMin : 160|32@1- (0.001,0) [-2.14748E+06|2.14748E+06] "Amps" BMS,CHG,DIAG,INV_CHG,UI,xNova,xSolarSurveyor,xSolarWave
 SG_ DesiredFloatIMax : 192|32@1- (0.001,0) [-2.14748E+06|2.14748E+06] "Amps" BMS,CHG,DIAG,INV_CHG,UI,xNova,xSolarSurveyor,xSolarWave
 SG_ DesiredFloatI : 128|32@1- (0.001,0) [-2.14748E+06|2.14748E+06] "Amps" BMS,CHG,DIAG,INV_CHG,UI,xNova,xSolarSurveyor,xSolarWave
 SG_ DcSrcId : 16|8@1+ (1,0) [0|252] "" BMS,CHG,DIAG,INV_CHG,UI,xNova,xSolarSurveyor,xSolarWave
 SG_ ConcurAccCtr : 8|8@1+ (1,0) [0|252] "" BMS,CHG,DIAG,INV_CHG,UI,xNova,xSolarSurveyor,xSolarWave
 SG_ CfgType : 0|2@1+ (1,0) [0|0] "" BMS,CHG,DIAG,INV_CHG,UI,xNova,xSolarSurveyor,xSolarWave
 SG_ BattType : 24|8@1+ (1,0) [0|252] "" BMS,CHG,DIAG,INV_CHG,UI,xNova,xSolarSurveyor,xSolarWave

BO_ 2147556096 ChgCfgEqualize: 53 BMS
 SG_ RsvBits : 418|6@1+ (1,0) [0|0] "" BMS,CHG,DIAG,INV_CHG,UI,xNova,xSolarSurveyor,xSolarWave
 SG_ MsgCount : 2|6@1+ (1,0) [0|0] "" BMS,CHG,DIAG,INV_CHG,UI,xNova,xSolarSurveyor,xSolarWave
 SG_ EqlzTermVDeltaMin : 256|32@1- (0.001,0) [-2.14748E+06|2.14748E+06] "V" BMS,CHG,DIAG,INV_CHG,UI,xNova,xSolarSurveyor,xSolarWave
 SG_ EqlzTermVDeltaMax : 288|32@1- (0.001,0) [-2.14748E+06|2.14748E+06] "V" BMS,CHG,DIAG,INV_CHG,UI,xNova,xSolarSurveyor,xSolarWave
 SG_ EqlzTermVDelta : 224|32@1- (0.001,0) [-2.14748E+06|2.14748E+06] "V" BMS,CHG,DIAG,INV_CHG,UI,xNova,xSolarSurveyor,xSolarWave
 SG_ EqlzTermTimeMin : 336|16@1+ (1,0) [0|65532] "seconds" BMS,CHG,DIAG,INV_CHG,UI,xNova,xSolarSurveyor,xSolarWave
 SG_ EqlzTermTimeMax : 352|16@1+ (1,0) [0|65532] "seconds" BMS,CHG,DIAG,INV_CHG,UI,xNova,xSolarSurveyor,xSolarWave
 SG_ EqlzTermTime : 320|16@1+ (1,0) [0|65532] "seconds" BMS,CHG,DIAG,INV_CHG,UI,xNova,xSolarSurveyor,xSolarWave
 SG_ EqlzSuppEnDis : 416|2@1+ (1,0) [0|0] "" BMS,CHG,DIAG,INV_CHG,UI,xNova,xSolarSurveyor,xSolarWave
 SG_ EqlzPeriodToMin : 384|16@1+ (1,0) [0|65532] "minutes" BMS,CHG,DIAG,INV_CHG,UI,xNova,xSolarSurveyor,xSolarWave
 SG_ EqlzPeriodToMax : 400|16@1+ (1,0) [0|65532] "minutes" BMS,CHG,DIAG,INV_CHG,UI,xNova,xSolarSurveyor,xSolarWave
 SG_ EqlzPeriodTo : 368|16@1+ (1,0) [0|65532] "minutes" BMS,CHG,DIAG,INV_CHG,UI,xNova,xSolarSurveyor,xSolarWave
 SG_ DesiredEqlzVMin : 64|32@1- (0.001,0) [-2.14748E+06|2.14748E+06] "V" BMS,CHG,DIAG,INV_CHG,UI,xNova,xSolarSurveyor,xSolarWave
 SG_ DesiredEqlzVMax : 96|32@1- (0.001,0) [-2.14748E+06|2.14748E+06] "V" BMS,CHG,DIAG,INV_CHG,UI,xNova,xSolarSurveyor,xSolarWave
 SG_ DesiredEqlzV : 32|32@1- (0.001,0) [-2.14748E+06|2.14748E+06] "V" BMS,CHG,DIAG,INV_CHG,UI,xNova,xSolarSurveyor,xSolarWave
 SG_ DesiredEqlzIMin : 160|32@1- (0.001,0) [-2.14748E+06|2.14748E+06] "Amps" BMS,CHG,DIAG,INV_CHG,UI,xNova,xSolarSurveyor,xSolarWave
 SG_ DesiredEqlzIMax : 192|32@1- (0.001,0) [-2.14748E+06|2.14748E+06] "Amps" BMS,CHG,DIAG,INV_CHG,UI,xNova,xSolarSurveyor,xSolarWave
 SG_ DesiredEqlzI : 128|32@1- (0.001,0) [-2.14748E+06|2.14748E+06] "Amps" BMS,CHG,DIAG,INV_CHG,UI,xNova,xSolarSurveyor,xSolarWave
 SG_ DcSrcId : 16|8@1+ (1,0) [0|252] "" BMS,CHG,DIAG,INV_CHG,UI,xNova,xSolarSurveyor,xSolarWave
 SG_ ConcurAccCtr : 8|8@1+ (1,0) [0|252] "" BMS,CHG,DIAG,INV_CHG,UI,xNova,xSolarSurveyor,xSolarWave
 SG_ CfgType : 0|2@1+ (1,0) [0|0] "" BMS,CHG,DIAG,INV_CHG,UI,xNova,xSolarSurveyor,xSolarWave
 SG_ BattType : 24|8@1+ (1,0) [0|252] "" BMS,CHG,DIAG,INV_CHG,UI,xNova,xSolarSurveyor,xSolarWave

BO_ 2147556352 ChgCfgCvCi: 28 BMS
 SG_ MsgCount : 2|6@1+ (1,0) [0|0] "" BMS,CHG,DIAG,INV_CHG,UI,xNova,xSolarWave
 SG_ DesiredOutVMin : 64|32@1- (0.001,0) [-2.14748E+06|2.14748E+06] "V" BMS,CHG,DIAG,INV_CHG,UI,xNova,xSolarWave
 SG_ DesiredOutVMax : 96|32@1- (0.001,0) [-2.14748E+06|2.14748E+06] "V" BMS,CHG,DIAG,INV_CHG,UI,xNova,xSolarWave
 SG_ DesiredOutV : 32|32@1- (0.001,0) [-2.14748E+06|2.14748E+06] "V" BMS,CHG,DIAG,INV_CHG,UI,xNova,xSolarWave
 SG_ DesiredOutIMin : 160|32@1- (0.001,0) [-2.14748E+06|2.14748E+06] "Amps" BMS,CHG,DIAG,INV_CHG,UI,xNova,xSolarWave
 SG_ DesiredOutIMax : 192|32@1- (0.001,0) [-2.14748E+06|2.14748E+06] "Amps" BMS,CHG,DIAG,INV_CHG,UI,xNova,xSolarWave
 SG_ DesiredOutI : 128|32@1- (0.001,0) [-2.14748E+06|2.14748E+06] "Amps" BMS,CHG,DIAG,INV_CHG,UI,xNova,xSolarWave
 SG_ DcSrcId : 16|8@1+ (1,0) [0|252] "" BMS,CHG,DIAG,INV_CHG,UI,xNova,xSolarWave
 SG_ ConcurAccCtr : 8|8@1+ (1,0) [0|252] "" BMS,CHG,DIAG,INV_CHG,UI,xNova,xSolarWave
 SG_ CfgType : 0|2@1+ (1,0) [0|0] "" BMS,CHG,DIAG,INV_CHG,UI,xNova,xSolarWave
 SG_ BattType : 24|8@1+ (1,0) [0|252] "" BMS,CHG,DIAG,INV_CHG,UI,xNova,xSolarWave

BO_ 2147555072 ChgCfgBulk: 52 BMS
 SG_ MsgCount : 2|6@1+ (1,0) [0|0] "" BMS,CHG,DIAG,INV_CHG,UI,xNova,xSolarSurveyor,xSolarWave
 SG_ DesiredBulkVMin : 64|32@1- (0.001,0) [-2.14748E+06|2.14748E+06] "V" BMS,CHG,DIAG,INV_CHG,UI,xNova,xSolarSurveyor,xSolarWave
 SG_ DesiredBulkVMax : 96|32@1- (0.001,0) [-2.14748E+06|2.14748E+06] "V" BMS,CHG,DIAG,INV_CHG,UI,xNova,xSolarSurveyor,xSolarWave
 SG_ DesiredBulkV : 32|32@1- (0.001,0) [-2.14748E+06|2.14748E+06] "V" BMS,CHG,DIAG,INV_CHG,UI,xNova,xSolarSurveyor,xSolarWave
 SG_ DesiredBulkIMin : 160|32@1- (0.001,0) [-2.14748E+06|2.14748E+06] "Amps" BMS,CHG,DIAG,INV_CHG,UI,xNova,xSolarSurveyor,xSolarWave
 SG_ DesiredBulkIMax : 192|32@1- (0.001,0) [-2.14748E+06|2.14748E+06] "Amps" BMS,CHG,DIAG,INV_CHG,UI,xNova,xSolarSurveyor,xSolarWave
 SG_ DesiredBulkI : 128|32@1- (0.001,0) [-2.14748E+06|2.14748E+06] "Amps" BMS,CHG,DIAG,INV_CHG,UI,xNova,xSolarSurveyor,xSolarWave
 SG_ DcSrcId : 16|8@1+ (1,0) [0|252] "" BMS,CHG,DIAG,INV_CHG,UI,xNova,xSolarSurveyor,xSolarWave
 SG_ ConcurAccCtr : 8|8@1+ (1,0) [0|252] "" BMS,CHG,DIAG,INV_CHG,UI,xNova,xSolarSurveyor,xSolarWave
 SG_ CfgType : 0|2@1+ (1,0) [0|0] "" BMS,CHG,DIAG,INV_CHG,UI,xNova,xSolarSurveyor,xSolarWave
 SG_ BulkTermVMin : 256|32@1- (0.001,0) [-2.14748E+06|2.14748E+06] "V" BMS,CHG,DIAG,INV_CHG,UI,xNova,xSolarSurveyor,xSolarWave
 SG_ BulkTermVMax : 288|32@1- (0.001,0) [-2.14748E+06|2.14748E+06] "V" BMS,CHG,DIAG,INV_CHG,UI,xNova,xSolarSurveyor,xSolarWave
 SG_ BulkTermV : 224|32@1- (0.001,0) [-2.14748E+06|2.14748E+06] "V" BMS,CHG,DIAG,INV_CHG,UI,xNova,xSolarSurveyor,xSolarWave
 SG_ BulkTermTimeMin : 336|16@1+ (1,0) [0|65532] "seconds" BMS,CHG,DIAG,INV_CHG,UI,xNova,xSolarSurveyor,xSolarWave
 SG_ BulkTermTimeMax : 352|16@1+ (1,0) [0|65532] "seconds" BMS,CHG,DIAG,INV_CHG,UI,xNova,xSolarSurveyor,xSolarWave
 SG_ BulkTermTime : 320|16@1+ (1,0) [0|65532] "seconds" BMS,CHG,DIAG,INV_CHG,UI,xNova,xSolarSurveyor,xSolarWave
 SG_ BulkPeriodToMin : 384|16@1+ (1,0) [0|65532] "minutes" BMS,CHG,DIAG,INV_CHG,UI,xNova,xSolarSurveyor,xSolarWave
 SG_ BulkPeriodToMax : 400|16@1+ (1,0) [0|65532] "minutes" BMS,CHG,DIAG,INV_CHG,UI,xNova,xSolarSurveyor,xSolarWave
 SG_ BulkPeriodTo : 368|16@1+ (1,0) [0|65532] "minutes" BMS,CHG,DIAG,INV_CHG,UI,xNova,xSolarSurveyor,xSolarWave
 SG_ BattType : 24|8@1+ (1,0) [0|252] "" BMS,CHG,DIAG,INV_CHG,UI,xNova,xSolarSurveyor,xSolarWave

BO_ 2147555328 ChgCfgAbsorp: 58 BMS
 SG_ MsgCount : 2|6@1+ (1,0) [0|0] "" BMS,CHG,DIAG,INV_CHG,UI,xNova,xSolarSurveyor,xSolarWave
 SG_ DesiredAbsVMin : 64|32@1- (0.001,0) [-2.14748E+06|2.14748E+06] "V" BMS,CHG,DIAG,INV_CHG,UI,xNova,xSolarSurveyor,xSolarWave
 SG_ DesiredAbsVMax : 96|32@1- (0.001,0) [-2.14748E+06|2.14748E+06] "V" BMS,CHG,DIAG,INV_CHG,UI,xNova,xSolarSurveyor,xSolarWave
 SG_ DesiredAbsV : 32|32@1- (0.001,0) [-2.14748E+06|2.14748E+06] "V" BMS,CHG,DIAG,INV_CHG,UI,xNova,xSolarSurveyor,xSolarWave
 SG_ DesiredAbsIMin : 160|32@1- (0.001,0) [-2.14748E+06|2.14748E+06] "Amps" BMS,CHG,DIAG,INV_CHG,UI,xNova,xSolarSurveyor,xSolarWave
 SG_ DesiredAbsIMax : 192|32@1- (0.001,0) [-2.14748E+06|2.14748E+06] "Amps" BMS,CHG,DIAG,INV_CHG,UI,xNova,xSolarSurveyor,xSolarWave
 SG_ DesiredAbsI : 128|32@1- (0.001,0) [-2.14748E+06|2.14748E+06] "Amps" BMS,CHG,DIAG,INV_CHG,UI,xNova,xSolarSurveyor,xSolarWave
 SG_ DcSrcId : 16|8@1+ (1,0) [0|252] "" BMS,CHG,DIAG,INV_CHG,UI,xNova,xSolarSurveyor,xSolarWave
 SG_ ConcurAccCtr : 8|8@1+ (1,0) [0|252] "" BMS,CHG,DIAG,INV_CHG,UI,xNova,xSolarSurveyor,xSolarWave
 SG_ CfgType : 0|2@1+ (1,0) [0|0] "" BMS,CHG,DIAG,INV_CHG,UI,xNova,xSolarSurveyor,xSolarWave
 SG_ BattType : 24|8@1+ (1,0) [0|252] "" BMS,CHG,DIAG,INV_CHG,UI,xNova,xSolarSurveyor,xSolarWave
 SG_ AbsTermTimeIMin : 336|16@1+ (1,0) [0|65532] "seconds" BMS,CHG,DIAG,INV_CHG,UI,xNova,xSolarSurveyor,xSolarWave
 SG_ AbsTermTimeIMax : 352|16@1+ (1,0) [0|65532] "seconds" BMS,CHG,DIAG,INV_CHG,UI,xNova,xSolarSurveyor,xSolarWave
 SG_ AbsTermTimeI : 320|16@1+ (1,0) [0|65532] "seconds" BMS,CHG,DIAG,INV_CHG,UI,xNova,xSolarSurveyor,xSolarWave
 SG_ AbsTermTimeConstVMin : 384|16@1+ (1,0) [0|65532] "seconds" BMS,CHG,DIAG,INV_CHG,UI,xNova,xSolarSurveyor,xSolarWave
 SG_ AbsTermTimeConstVMax : 400|16@1+ (1,0) [0|65532] "seconds" BMS,CHG,DIAG,INV_CHG,UI,xNova,xSolarSurveyor,xSolarWave
 SG_ AbsTermTimeConstV : 368|16@1+ (1,0) [0|65532] "seconds" BMS,CHG,DIAG,INV_CHG,UI,xNova,xSolarSurveyor,xSolarWave
 SG_ AbsTermIMin : 256|32@1- (0.001,0) [-2.14748E+06|2.14748E+06] "Amps" BMS,CHG,DIAG,INV_CHG,UI,xNova,xSolarSurveyor,xSolarWave
 SG_ AbsTermIMax : 288|32@1- (0.001,0) [-2.14748E+06|2.14748E+06] "Amps" BMS,CHG,DIAG,INV_CHG,UI,xNova,xSolarSurveyor,xSolarWave
 SG_ AbsTermI : 224|32@1- (0.001,0) [-2.14748E+06|2.14748E+06] "Amps" BMS,CHG,DIAG,INV_CHG,UI,xNova,xSolarSurveyor,xSolarWave
 SG_ AbsPeriodToMin : 432|16@1+ (1,0) [0|65532] "minutes" BMS,CHG,DIAG,INV_CHG,UI,xNova,xSolarSurveyor,xSolarWave
 SG_ AbsPeriodToMax : 448|16@1+ (1,0) [0|65532] "minutes" BMS,CHG,DIAG,INV_CHG,UI,xNova,xSolarSurveyor,xSolarWave
 SG_ AbsPeriodTo : 416|16@1+ (1,0) [0|65532] "minutes" BMS,CHG,DIAG,INV_CHG,UI,xNova,xSolarSurveyor,xSolarWave

BO_TX_BU_ 2147573248 : UI,DIAG,EMS;
BO_TX_BU_ 2147569664 : xMiata_AGS,xSolarWave,BATTMON,AGS,INV,CHG,UI,INV_CHG,DIAG,GATEWAY,xNova,xSolarSurveyor;
BO_TX_BU_ 2147568640 : xMiata_AGS,xSolarWave,BATTMON,AGS,INV,CHG,UI,INV_CHG,GATEWAY,xNova;
BO_TX_BU_ 2147561216 : xMiata_AGS,BATTMON,AGS,INV,CHG,UI,INV_CHG,DIAG,GATEWAY,xNova,xSolarSurveyor;
BO_TX_BU_ 2147563776 : xSolarWave,BATTMON,AGS,INV,CHG,UI,INV_CHG,DIAG,GATEWAY,xSolarSurveyor,EMS;
BO_TX_BU_ 2147610821 : xSolarWave,BATTMON,INV,CHG,INV_CHG,DIAG,xSolarSurveyor,EMS;
BO_TX_BU_ 2147610625 : BATTMON,INV,CHG,INV_CHG,DIAG,xNova;
BO_TX_BU_ 2147549440 : xSolarWave,INV,CHG,UI,INV_CHG,DIAG,xNova,xSolarSurveyor,BMS;
BO_TX_BU_ 2147549952 : INV,CHG,UI,INV_CHG,DIAG;
BO_TX_BU_ 2147550464 : INV,CHG,UI,INV_CHG,DIAG;
BO_TX_BU_ 2147599104 : INV,CHG,UI,INV_CHG,DIAG,xSolarSurveyor;
BO_TX_BU_ 2147570432 : INV,CHG,UI,INV_CHG,DIAG;
BO_TX_BU_ 2147549696 : xSolarWave,INV,CHG,UI,INV_CHG,DIAG,xNova,xSolarSurveyor,BMS;
BO_TX_BU_ 2147550208 : INV,CHG,UI,INV_CHG,DIAG;
BO_TX_BU_ 2147556608 : xSolarWave,BATTMON,INV,CHG,UI,INV_CHG,DIAG,xNova,xSolarSurveyor,EMS,BMS;
BO_TX_BU_ 2147612681 : xSolarWave,UI,DIAG,GATEWAY;
BO_TX_BU_ 2147567616 : xSolarWave,UI,DIAG;
BO_TX_BU_ 2147575552 : UI,DIAG,GATEWAY;
BO_TX_BU_ 2147565568 : UI,DIAG,BMS;
BO_TX_BU_ 2147606016 : UI,DIAG;
BO_TX_BU_ 2147610626 : xMiata_AGS,xSolarWave,BATTMON,AGS,INV,CHG,UI,INV_CHG,DIAG,GATEWAY,xNova,xSolarSurveyor,EMS,BMS;
BO_TX_BU_ 2147559424 : UI,DIAG;
BO_TX_BU_ 2147610638 : xSolarWave,CHG,INV_CHG,xNova,xSolarSurveyor;
BO_TX_BU_ 2147610658 : xSolarWave,CHG,INV_CHG;
BO_TX_BU_ 2147610659 : xSolarWave,CHG,INV_CHG,xNova;
BO_TX_BU_ 2147610817 : CHG,INV_CHG;
BO_TX_BU_ 2147610657 : CHG,INV_CHG,xNova;
BO_TX_BU_ 2147610814 : xSolarWave,CHG,INV_CHG,xSolarSurveyor;
BO_TX_BU_ 2147610816 : xSolarWave,CHG,INV_CHG;
BO_TX_BU_ 2147610650 : CHG,INV_CHG,xNova;
BO_TX_BU_ 2147600384 : UI,DIAG,GATEWAY,BMS;
BO_TX_BU_ 2147562752 : UI,DIAG,GATEWAY;
BO_TX_BU_ 2147555584 : CHG,UI,INV_CHG,DIAG;
BO_TX_BU_ 2147559168 : xSolarWave,CHG,UI,INV_CHG,DIAG;
BO_TX_BU_ 2147555840 : xSolarWave,CHG,UI,INV_CHG,DIAG,xNova,xSolarSurveyor,BMS;
BO_TX_BU_ 2147556096 : xSolarWave,CHG,UI,INV_CHG,DIAG,xNova,xSolarSurveyor,BMS;
BO_TX_BU_ 2147556352 : xSolarWave,CHG,UI,INV_CHG,DIAG,xNova,BMS;
BO_TX_BU_ 2147555072 : xSolarWave,CHG,UI,INV_CHG,DIAG,xNova,xSolarSurveyor,BMS;
BO_TX_BU_ 2147555328 : xSolarWave,CHG,UI,INV_CHG,DIAG,xNova,xSolarSurveyor,BMS;
CM_ BO_ 2147573248 "EMS Configuration";
CM_ SG_ 2147573248 ShoreBreakerRatingMin "Shore Breaker Rating - Minimum";
CM_ SG_ 2147573248 ShoreBreakerRatingMax "Shore Breaker Rating - Maximum";
CM_ SG_ 2147573248 ShoreBreakerRating "Shore Breaker Rating";
CM_ SG_ 2147573248 ShoreBreakerMode "Shore Breaker Mode";
CM_ SG_ 2147573248 RsvBits "Reserved Bits";
CM_ SG_ 2147573248 MsgCount "Message Count";
CM_ SG_ 2147573248 GenWarmDelayMin "Generator Warm Up Delay - Minimum";
CM_ SG_ 2147573248 GenWarmDelayMax "Generator Warm Up Delay - Maximum";
CM_ SG_ 2147573248 GenWarmDelay "Generator Warm Up Delay";
CM_ SG_ 2147573248 GenBreakerRatingMin "Generator Breaker Rating - Minimum";
CM_ SG_ 2147573248 GenBreakerRatingMax "Generator Breaker Rating - Maximum";
CM_ SG_ 2147573248 GenBreakerRating "Generator Breaker Rating";
CM_ SG_ 2147573248 GenBreakerMode "Generator Breaker Mode";
CM_ SG_ 2147573248 ConSeqDelayMin "Connect Sequence Delay - Minimum";
CM_ SG_ 2147573248 ConSeqDelayMax "Connect Sequence Delay - Maximum";
CM_ SG_ 2147573248 ConSeqDelay "Connect Sequence Delay";
CM_ SG_ 2147573248 ConcurAccCtr "Concurrent Access Counter";
CM_ SG_ 2147573248 CfgType "Configuration Type";
CM_ SG_ 2147573248 BreakerDeratingEnDis "Breaker Derating Enable/Disable";
CM_ SG_ 2147573248 AcDisqualifyPriority "AC Disqualify Priority";
CM_ BO_ 2147569664 "Diagnostic - Manufacturing Configuration";
CM_ SG_ 2147569664 RsvBits "Reserved Bits";
CM_ SG_ 2147569664 MsgCount "Message Count";
CM_ SG_ 2147569664 MfgTime "Manufacturing Time";
CM_ SG_ 2147569664 MfgStep "Manufacturing Step";
CM_ SG_ 2147569664 LocalOffsetMins "Local Offset, Minutes";
CM_ SG_ 2147569664 ConcurAccCtr "Concurrent Access Counter";
CM_ BO_ 2147568128 "Diagnostic - Indicator Command";
CM_ SG_ 2147568128 IndicState "Indicator State";
CM_ SG_ 2147568128 IndicId "Indicator Identifier";
CM_ BO_ 2147568896 "Diagnostic - Fan Command";
CM_ SG_ 2147568896 FanSpd "Fan Speed";
CM_ SG_ 2147568896 FanId "Fan Identifier";
CM_ BO_ 2147568640 "Diagnostic - Contact Status";
CM_ SG_ 2147568640 RsvBits "Reserved Bits";
CM_ SG_ 2147568640 MsgCount "Message Count";
CM_ SG_ 2147568640 CntctState "Contact State";
CM_ SG_ 2147568640 CntctId "Contact Identifier";
CM_ BO_ 2147568384 "Diagnostic - Contact Command";
CM_ SG_ 2147568384 CntctState "Contact State";
CM_ SG_ 2147568384 CntctId "Contact Identifier";
CM_ BO_ 2147561472 "Development - Poke at Address";
CM_ SG_ 2147561472 StartMemAddr "Start Memory Address";
CM_ SG_ 2147561472 RsvBits "Reserved Bits";
CM_ SG_ 2147561472 ProcessorInst "Controller Instance";
CM_ SG_ 2147561472 NumBytesSet "Number of Bytes to Set";
CM_ SG_ 2147561472 BytesSet "Bytes to Set";
CM_ BO_ 2147561216 "Development - Peek at Address Response";
CM_ SG_ 2147561216 StartMemAddr "Start memory Address";
CM_ SG_ 2147561216 RsvBits "Reserved Bits";
CM_ SG_ 2147561216 ProcessorInst "Controller Instance";
CM_ SG_ 2147561216 NumBytesGot "Number of Bytes Retrieved";
CM_ SG_ 2147561216 BytesGot "Bytes Retrieved";
CM_ BO_ 2147560960 "Development - Peek at Address Request";
CM_ SG_ 2147560960 StartMemAddr "Start Memory Address";
CM_ SG_ 2147560960 RsvBits "Reserved Bits";
CM_ SG_ 2147560960 ProcessorInst "Controller Instance";
CM_ SG_ 2147560960 NumBytesGet "Number of Bytes to Retrieve";
CM_ BO_ 2147563776 "Debug Fast-Packet";
CM_ SG_ 2147563776 Data "Byte";
CM_ BO_ 2147610821 "DC Source Status (Deux)";
CM_ SG_ 2147610821 Voltage "Voltage";
CM_ SG_ 2147610821 RsvBits "Reserved Bits";
CM_ SG_ 2147610821 RsvBits "Reserved Bits";
CM_ SG_ 2147610821 RippleVoltage "RippleVoltage";
CM_ SG_ 2147610821 Pwr "Power";
CM_ SG_ 2147610821 MsgCount "Message Count";
CM_ SG_ 2147610821 DeratingSts "Derating Status";
CM_ SG_ 2147610821 DeratingReason "Derating Reason";
CM_ SG_ 2147610821 DcSrcId "DC Source Identifier";
CM_ SG_ 2147610821 Current "Current";
CM_ BO_ 2147610625 "DC Source Status";
CM_ SG_ 2147610625 Voltage "Voltage";
CM_ SG_ 2147610625 TimeRemain "Time Remaining";
CM_ SG_ 2147610625 TempSensId "Temperature Sensor Identifier";
CM_ SG_ 2147610625 Temp "Temperature";
CM_ SG_ 2147610625 Soh "State of Health";
CM_ SG_ 2147610625 Soc "State of Charge";
CM_ SG_ 2147610625 RsvBits "Reserved Bits";
CM_ SG_ 2147610625 Pwr "Power";
CM_ SG_ 2147610625 MsgCount "Message Count";
CM_ SG_ 2147610625 DcSrcId "DC Source Identifier";
CM_ SG_ 2147610625 Current "Current";
CM_ SG_ 2147610625 BattCapRemain "Battery Capacity Remaining";
CM_ SG_ 2147610625 BattCapPer "Battery Capacity Percent of Maximum";
CM_ BO_ 2147549440 "DC Source Configuration - Under Voltage";
CM_ SG_ 2147549440 UvLvlMin "Under Voltage Level - Minimum";
CM_ SG_ 2147549440 UvLvlMax "Under Voltage Level - Maximum";
CM_ SG_ 2147549440 UvLvl "Under Voltage Level";
CM_ SG_ 2147549440 UvIntvlMin "Under Voltage Interval - Minimum";
CM_ SG_ 2147549440 UvIntvlMax "Under Voltage Interval - Maximum";
CM_ SG_ 2147549440 UvIntvl "Under Voltage Interval";
CM_ SG_ 2147549440 RefEvtId "Reference Event Identifier";
CM_ SG_ 2147549440 MsgCount "Message Count";
CM_ SG_ 2147549440 EvtId "Event Identifier";
CM_ SG_ 2147549440 DcSrcId "DC Source Identifier";
CM_ SG_ 2147549440 ConcurAccCtr "Concurrent Access Counter";
CM_ SG_ 2147549440 CfgType "Configuration Type";
CM_ BO_ 2147549952 "DC Source Configuration - Under Current";
CM_ SG_ 2147549952 UiLvlMin "Under Current Level - Minimum";
CM_ SG_ 2147549952 UiLvlMax "Under Current Level - Maximum";
CM_ SG_ 2147549952 UiLvl "Under Current Level";
CM_ SG_ 2147549952 UiIntvlMin "Under Current Interval - Minimum";
CM_ SG_ 2147549952 UiIntvlMax "Under Current Interval - Maximum";
CM_ SG_ 2147549952 UiIntvl "Under Current Interval";
CM_ SG_ 2147549952 RefEvtId "Reference Event Identifier";
CM_ SG_ 2147549952 MsgCount "Message Count";
CM_ SG_ 2147549952 EvtId "Event Identifier";
CM_ SG_ 2147549952 DcSrcId "DC Source Identifier";
CM_ SG_ 2147549952 ConcurAccCtr "Concurrent Access Counter";
CM_ SG_ 2147549952 CfgType "Configuration Type";
CM_ BO_ 2147550464 "DC Source Configuration - Over Ripple Voltage - Pe";
CM_ SG_ 2147550464 RefEvtId "Reference Event Identifier";
CM_ SG_ 2147550464 PeakRipOvLvlMin "Peak Ripple Over Voltage Level - Minimum";
CM_ SG_ 2147550464 PeakRipOvLvlMax "Peak Ripple Over Voltage Level - Maximum";
CM_ SG_ 2147550464 PeakRipOvLvl "Peak Ripple Over Voltage Level";
CM_ SG_ 2147550464 PeakRipOvIntvlMin "Peak Ripple Over Voltage Interval - Minimum";
CM_ SG_ 2147550464 PeakRipOvIntvlMax "Peak Ripple Over Voltage Interval - Maximum";
CM_ SG_ 2147550464 PeakRipOvIntvl "Peak Ripple Over Voltage Interval";
CM_ SG_ 2147550464 MsgCount "Message Count";
CM_ SG_ 2147550464 EvtId "Event Identifier";
CM_ SG_ 2147550464 DcSrcId "DC Source Identifier";
CM_ SG_ 2147550464 ConcurAccCtr "Concurrent Access Counter";
CM_ SG_ 2147550464 CfgType "Configuration Type";
CM_ BO_ 2147599104 "DC Source Configuration - Photovoltaic Array (Deux";
CM_ SG_ 2147599104 VMaxPwrMin "Voltage Where Maximum Power - Min";
CM_ SG_ 2147599104 VMaxPwrMax "Voltage Where Maximum Power - Max";
CM_ SG_ 2147599104 VMaxPwr "Voltage Where Maximum Power";
CM_ SG_ 2147599104 RsvBits "Reserved Bits";
CM_ SG_ 2147599104 PwrXferMin "Power Transfer - Minimum";
CM_ SG_ 2147599104 PwrXferMax "Power Transfer - Maximum";
CM_ SG_ 2147599104 PwrXfer "Power Transfer";
CM_ SG_ 2147599104 MsgCount "Message Count";
CM_ SG_ 2147599104 MpptEnDis "MPPT Enable/Disable";
CM_ SG_ 2147599104 DcSrcId "DC Source Identifier";
CM_ SG_ 2147599104 ConcurAccCtr "Concurrent Access Counter";
CM_ SG_ 2147599104 CfgType "Configuration Type";
CM_ BO_ 2147570432 "DC Source Configuration - Photovoltaic Array";
CM_ SG_ 2147570432 RsvBits "Reserved Bits";
CM_ SG_ 2147570432 PwrXferMin "Power Transfer - Minimum";
CM_ SG_ 2147570432 PwrXferMax "Power Transfer - Maximum";
CM_ SG_ 2147570432 PwrXfer "Power Transfer";
CM_ SG_ 2147570432 MsgCount "Message Count";
CM_ SG_ 2147570432 MpptEnDis "MPPT Enable/Disable";
CM_ SG_ 2147570432 DcSrcId "DC Source Identifier";
CM_ SG_ 2147570432 ConcurAccCtr "Concurrent Access Counter";
CM_ SG_ 2147570432 CfgType "Configuration Type";
CM_ BO_ 2147549696 "DC Source Configuration - Over Voltage";
CM_ SG_ 2147549696 RefEvtId "Reference Event Identifier";
CM_ SG_ 2147549696 OvLvlMin "Over Voltage Level - Minimum";
CM_ SG_ 2147549696 OvLvlMax "Over Voltage Level - Maximum";
CM_ SG_ 2147549696 OvLvl "Over Voltage Level";
CM_ SG_ 2147549696 OvIntvlMin "Over Voltage Interval - Minimum";
CM_ SG_ 2147549696 OvIntvlMax "Over Voltage Interval - Maximum";
CM_ SG_ 2147549696 OvIntvl "Over Voltage Interval";
CM_ SG_ 2147549696 MsgCount "Message Count";
CM_ SG_ 2147549696 EvtId "Event Identifier";
CM_ SG_ 2147549696 DcSrcId "DC Source Identifier";
CM_ SG_ 2147549696 ConcurAccCtr "Concurrent Access Counter";
CM_ SG_ 2147549696 CfgType "Configuration Type";
CM_ BO_ 2147550208 "DC Source Configuration - Over Current";
CM_ SG_ 2147550208 RefEvtId "Reference Event Identifier";
CM_ SG_ 2147550208 OiLvlMin "Over Current Level - Minimum";
CM_ SG_ 2147550208 OiLvlMax "Over Current Level - Maximum";
CM_ SG_ 2147550208 OiLvl "Over Current Level";
CM_ SG_ 2147550208 OiIntvlMin "Over Current Interval - Minimum";
CM_ SG_ 2147550208 OiIntvlMax "Over Current Interval - Maximum";
CM_ SG_ 2147550208 OiIntvl "Over Current Interval";
CM_ SG_ 2147550208 MsgCount "Message Count";
CM_ SG_ 2147550208 EvtId "Event Identifier";
CM_ SG_ 2147550208 DcSrcId "DC Source Identifier";
CM_ SG_ 2147550208 ConcurAccCtr "Concurrent Access Counter";
CM_ SG_ 2147550208 CfgType "Configuration Type";
CM_ BO_ 2147556608 "DC Source Configuration - Battery";
CM_ SG_ 2147556608 PeukertExponentMin "Peukert Exponent - Minimum";
CM_ SG_ 2147556608 PeukertExponentMax "Peukert Exponent - Maximum";
CM_ SG_ 2147556608 PeukertExponent "Peukert Exponent";
CM_ SG_ 2147556608 NomV "Nominal Voltage";
CM_ SG_ 2147556608 MsgCount "Message Count";
CM_ SG_ 2147556608 DcSrcId "DC Source Identifier";
CM_ SG_ 2147556608 ConcurAccCtr "Concurrent Access Counter";
CM_ SG_ 2147556608 ChgEfficFactorMin "Charge Efficiency Factor - Minimum";
CM_ SG_ 2147556608 ChgEfficFactorMax "Charge Efficiency Factor - Maximum";
CM_ SG_ 2147556608 ChgEfficFactor "Charge Efficiency Factor";
CM_ SG_ 2147556608 CfgType "Configuration Type";
CM_ SG_ 2147556608 BattType "Battery Type";
CM_ SG_ 2147556608 BattTempCoeffMin "Battery Temperature Coefficient - Minimum";
CM_ SG_ 2147556608 BattTempCoeffMax "Battery Temperature Coefficient - Maximum";
CM_ SG_ 2147556608 BattTempCoeff "Battery Temperature Coefficient";
CM_ SG_ 2147556608 BattChem "Battery Chemistry";
CM_ SG_ 2147556608 BattAmpHrRatingMin "Battery Amp Hour Rating - Minimum";
CM_ SG_ 2147556608 BattAmpHrRatingMax "Battery Amp Hour Rating - Maximum";
CM_ SG_ 2147556608 BattAmpHrRating "Battery Amp Hour Rating";
CM_ BO_ 2147612681 "Date and Time Status";
CM_ SG_ 2147612681 UtcTime "UTC Time";
CM_ SG_ 2147612681 RsvBits2 "Reserved Bits 2";
CM_ SG_ 2147612681 RsvBits1 "Reserved Bits 1";
CM_ SG_ 2147612681 MsgCount "Message Count";
CM_ SG_ 2147612681 LocalOffsetMins "Local Offset, Minutes";
CM_ SG_ 2147612681 LocalDow "Local Day of the Week";
CM_ BO_ 2147567616 "Date and Time Configuration";
CM_ SG_ 2147567616 UtcTime "UTC Time";
CM_ SG_ 2147567616 RsvBits "Reserved Bits";
CM_ SG_ 2147567616 MsgCount "Message Count";
CM_ SG_ 2147567616 LocalOffsetMins "Local Offset, Minutes";
CM_ SG_ 2147567616 LocalDow "Local Day of the Week";
CM_ SG_ 2147567616 ConcurAccCtr "Concurrent Access Counter";
CM_ SG_ 2147567616 CfgType "Configuration Type";
CM_ BO_ 2147575552 "Constant Voltage Constant Current Control Command";
CM_ SG_ 2147575552 MaxChgVScale "Maximum Charge Voltage Scale";
CM_ SG_ 2147575552 MaxChgIScale "Maximum Charge Current Scale";
CM_ SG_ 2147575552 DcSrcId "DC Source Identifier";
CM_ BO_ 2147565568 "Control Command";
CM_ SG_ 2147565568 DesiredMode "Desired Mode";
CM_ BO_ 2147606016 "Complex Request";
CM_ SG_ 2147606016 ParamGrpNum "Parameter Group Number";
CM_ SG_ 2147606016 FieldValue "FieldValue";
CM_ SG_ 2147606016 Field "Field";
CM_ BO_ 2147610626 "Communication Statistics";
CM_ SG_ 2147610626 TxFrameDropCnt "Transmit Frames Dropped Count";
CM_ SG_ 2147610626 TxExtFrameCnt "Transmitted Extended Frames Count";
CM_ SG_ 2147610626 TxErrCnt "Transmit Error Count";
CM_ SG_ 2147610626 RxFrameDropCnt "Receive Frames Dropped Count";
CM_ SG_ 2147610626 RxExtFrameCnt "Received Extended Frames Count";
CM_ SG_ 2147610626 RxErrCnt "Receive Error Count";
CM_ SG_ 2147610626 RsvBits "Reserved Bits";
CM_ SG_ 2147610626 MsgCount "Message Count";
CM_ SG_ 2147610626 MpToCnt "Multi-Packet Timeout Count";
CM_ SG_ 2147610626 MpLateFrameCnt "Multi-Packet Late Frame Count";
CM_ SG_ 2147610626 MemAllocFailCnt "Memory Allocation Failure Count";
CM_ SG_ 2147610626 HeapFreeMin "Minimum Heap Free";
CM_ SG_ 2147610626 BusOffCnt "Bus-Off Error Count";
CM_ BO_ 2147559424 "Clear Command";
CM_ SG_ 2147559424 WarnId "Warning Identifier";
CM_ SG_ 2147559424 RsvBits2 "Reserved Bits 2";
CM_ SG_ 2147559424 RsvBits1 "Reserved Bits 1";
CM_ SG_ 2147559424 ListItem "List Item";
CM_ SG_ 2147559424 FaultId "Fault Identifier";
CM_ BO_ 2147610638 "Charger Status";
CM_ SG_ 2147610638 RsvBits2 "Reserved Bits 2";
CM_ SG_ 2147610638 RsvBits1 "Reserved Bits 1";
CM_ SG_ 2147610638 OpState "Operating State";
CM_ SG_ 2147610638 MsgCount "Message Count";
CM_ SG_ 2147610638 EqlzTimeRemain "Equalization Time Remaining";
CM_ SG_ 2147610638 EqlzPending "Equalization Pending";
CM_ SG_ 2147610638 DcSrcId "DC Source Identifier";
CM_ SG_ 2147610638 CtrlV "Control Votlage";
CM_ SG_ 2147610638 CtrlIPer "Control Current Percent of Maximum";
CM_ SG_ 2147610638 CtrlI "Control Current";
CM_ SG_ 2147610638 ChgMode "Charger Mode";
CM_ SG_ 2147610638 ChgEnDis "Charger Enable/Disable";
CM_ SG_ 2147610638 ChgAlgorithm "Charging Algorithm";
CM_ SG_ 2147610638 BattTempSensorPresent "Battery Temperature Sensor Present";
CM_ BO_ 2147610658 "Charger Statistics - Internal Temperature";
CM_ SG_ 2147610658 TempSensId "Temperature Sensor Identifier";
CM_ SG_ 2147610658 TempMax "Highest Recorded Temperature";
CM_ SG_ 2147610658 RsvBits "Reserved Bits";
CM_ SG_ 2147610658 MsgCount "Message Count";
CM_ BO_ 2147610659 "Charger Statistics - External Temperature";
CM_ SG_ 2147610659 TempSensId "Temperature Sensor Identifier";
CM_ SG_ 2147610659 TempMin "Lowest Recorded Temperature";
CM_ SG_ 2147610659 TempMax "Highest Recorded Temperature";
CM_ SG_ 2147610659 RsvBits "Reserved Bits";
CM_ SG_ 2147610659 MsgCount "Message Count";
CM_ BO_ 2147610817 "Charger Statistics - DC (Deux)";
CM_ SG_ 2147610817 VoltageMin "Voltage Min";
CM_ SG_ 2147610817 VoltageMax "VoltageMax";
CM_ SG_ 2147610817 RsvBits "Reserved Bits";
CM_ SG_ 2147610817 PreviousPeriodCount "Previous Period Count";
CM_ SG_ 2147610817 PreviousPeriod "Previous Period";
CM_ SG_ 2147610817 PeakPower "Peak Power";
CM_ SG_ 2147610817 MsgCount "Message Count";
CM_ SG_ 2147610817 Energy "Energy";
CM_ SG_ 2147610817 DcSrcId "DC Source Identifier";
CM_ SG_ 2147610817 CurrentMax "Current Max";
CM_ BO_ 2147610657 "Charger Statistics - DC";
CM_ SG_ 2147610657 RsvBits "Reserved Bits";
CM_ SG_ 2147610657 MsgCount "Message Count";
CM_ SG_ 2147610657 DcSrcId "DC Source Identifier";
CM_ BO_ 2147610814 "Charger Statistics - Battery (Deux)";
CM_ SG_ 2147610814 VoltageMin "Voltage Min";
CM_ SG_ 2147610814 VoltageMax "Voltage Max";
CM_ SG_ 2147610814 RsvBits "Reserved Bits";
CM_ SG_ 2147610814 PreviousPeriodCount "Previos Period Count";
CM_ SG_ 2147610814 PreviousPeriod "Previous Period";
CM_ SG_ 2147610814 PeakPower "Peak Power";
CM_ SG_ 2147610814 MsgCount "Message Count";
CM_ SG_ 2147610814 LastEqualized "Last Equalized";
CM_ SG_ 2147610814 FloatTime "FloatTime";
CM_ SG_ 2147610814 Energy "Energy";
CM_ SG_ 2147610814 DcSrcId "DC Source Identifier";
CM_ SG_ 2147610814 CurrentMax "Current Max";
CM_ SG_ 2147610814 CapacityReturned "Capacity Returned To Battery";
CM_ BO_ 2147610816 "Charger Statistics - AC (Deux)";
CM_ SG_ 2147610816 VoltageMin "Lowest AC Input Voltage";
CM_ SG_ 2147610816 VoltageMax "Highest AC Input Voltage";
CM_ SG_ 2147610816 RsvBits "Reserved Bits";
CM_ SG_ 2147610816 PreviousPeriodCount "Previous Period Count";
CM_ SG_ 2147610816 PreviousPeriod "Previous Period";
CM_ SG_ 2147610816 MsgCount "Message Count";
CM_ SG_ 2147610816 Line "Line";
CM_ SG_ 2147610816 FreqMin "Lowest AC Input Frequency";
CM_ SG_ 2147610816 FreqMax "Highest AC Input Frequency";
CM_ SG_ 2147610816 CurrentMax "Highest AC Input Current";
CM_ SG_ 2147610816 AcSrcId "AC Source Identifier";
CM_ BO_ 2147610650 "Charger Statistics - AC";
CM_ SG_ 2147610650 VoltageMin "Lowest AC Input Voltage";
CM_ SG_ 2147610650 VoltageMax "Highest AC Input Voltage";
CM_ SG_ 2147610650 RsvBits "Reserved Bits";
CM_ SG_ 2147610650 MsgCount "Message Count";
CM_ SG_ 2147610650 Line "Line";
CM_ SG_ 2147610650 FreqMin "Lowest AC Input Frequency";
CM_ SG_ 2147610650 FreqMax "Highest AC Input Frequency";
CM_ SG_ 2147610650 CurrentMax "Highest AC Input Current";
CM_ SG_ 2147610650 AcSrcId "AC Source Identifier";
CM_ BO_ 2147600384 "Charger Control Command(Deux)";
CM_ SG_ 2147600384 RsvBits "Reserved Bits";
CM_ SG_ 2147600384 ForceChgState "Force Charger State";
CM_ SG_ 2147600384 DcSrcId "DC Source Identifier";
CM_ SG_ 2147600384 ChgEnDis "Charger Enable/Disable";
CM_ BO_ 2147562752 "Charger Control Command";
CM_ SG_ 2147562752 RsvBits "Reserved Bits";
CM_ SG_ 2147562752 DcSrcId "DC Source Identifier";
CM_ SG_ 2147562752 ChgEnDis "Charger Enable/Disable";
CM_ BO_ 2147555584 "Charger Configuration - Overcharge";
CM_ SG_ 2147555584 OChgPeriodToMin "Over Charge Period Timeout - Minimum";
CM_ SG_ 2147555584 OChgPeriodToMax "Over Charge Period Timeout - Maximum";
CM_ SG_ 2147555584 OChgPeriodTo "Over Charge Period Timeout";
CM_ SG_ 2147555584 MsgCount "Message Count";
CM_ SG_ 2147555584 DesiredOChgVMin "Desired Over Charge Voltage - Minimum";
CM_ SG_ 2147555584 DesiredOChgVMax "Desired Over Charge Voltage - Maximum";
CM_ SG_ 2147555584 DesiredOChgV "Desired Over Charge Voltage";
CM_ SG_ 2147555584 DesiredOChgIMin "Desired Over Charge Current - Minimum";
CM_ SG_ 2147555584 DesiredOChgIMax "Desired Over Charge Current - Maximum";
CM_ SG_ 2147555584 DesiredOChgI "Desired Over Charge Current";
CM_ SG_ 2147555584 DcSrcId "DC Source Identifier";
CM_ SG_ 2147555584 ConcurAccCtr "Concurrent Access Counter";
CM_ SG_ 2147555584 CfgType "Configuration Type";
CM_ SG_ 2147555584 BattType "Battery Type";
CM_ BO_ 2147559168 "Charger Configuration - Multiple Nodes";
CM_ SG_ 2147559168 NomDcVMin "Nominal DC Voltage - Minimum";
CM_ SG_ 2147559168 NomDcVMax "Nominal DC Voltage - Maximum";
CM_ SG_ 2147559168 NomDcV "Nominal DC Voltage";
CM_ SG_ 2147559168 MsgCount "Message Count";
CM_ SG_ 2147559168 MaxDcIMin "Maximum DC Current - Minimum";
CM_ SG_ 2147559168 MaxDcIMax "Maximum DC Current - Maximum";
CM_ SG_ 2147559168 MaxDcI "Maximum DC Current";
CM_ SG_ 2147559168 ConcurAccCtr "Concurrent Access Counter";
CM_ SG_ 2147559168 CfgType "Configuration Type";
CM_ SG_ 2147559168 AcInBreakerSzMin "AC Input Breaker Size - Minimum";
CM_ SG_ 2147559168 AcInBreakerSzMax "AC Input Breaker Size - Maximum";
CM_ SG_ 2147559168 AcInBreakerSz "AC Input Breaker Size";
CM_ BO_ 2147555840 "Charger Configuration - Float";
CM_ SG_ 2147555840 MsgCount "Message Count";
CM_ SG_ 2147555840 FloatTermVMin "Float Termination Voltage - Minimum";
CM_ SG_ 2147555840 FloatTermVMax "Float Termination Voltage - Maximum";
CM_ SG_ 2147555840 FloatTermV "Float Termination Voltage";
CM_ SG_ 2147555840 FloatTermTimeMin "Float Termination Time - Minimum";
CM_ SG_ 2147555840 FloatTermTimeMax "Float Termination Time - Maximum";
CM_ SG_ 2147555840 FloatTermTime "Float Termination Time";
CM_ SG_ 2147555840 FloatPeriodToMin "Float Period Timeout - Minimum";
CM_ SG_ 2147555840 FloatPeriodToMax "Float Period Timeout - Maximum";
CM_ SG_ 2147555840 FloatPeriodTo "Float Period Timeout";
CM_ SG_ 2147555840 DesiredFloatVMin "Desired Float Voltage - Minimum";
CM_ SG_ 2147555840 DesiredFloatVMax "Desired Float Voltage - Maximum";
CM_ SG_ 2147555840 DesiredFloatV "Desired Float Voltage";
CM_ SG_ 2147555840 DesiredFloatIMin "Desired Float Current - Minimum";
CM_ SG_ 2147555840 DesiredFloatIMax "Desired Float Current - Maximum";
CM_ SG_ 2147555840 DesiredFloatI "Desired Float Current";
CM_ SG_ 2147555840 DcSrcId "DC Source Identifier";
CM_ SG_ 2147555840 ConcurAccCtr "Concurrent Access Counter";
CM_ SG_ 2147555840 CfgType "Configuration Type";
CM_ SG_ 2147555840 BattType "Battery Type";
CM_ BO_ 2147556096 "Charger Configuration - Equalize";
CM_ SG_ 2147556096 RsvBits "Reserved Bits";
CM_ SG_ 2147556096 MsgCount "Message Count";
CM_ SG_ 2147556096 EqlzTermVDeltaMin "Equalization Termination Voltage Delta - Minimum";
CM_ SG_ 2147556096 EqlzTermVDeltaMax "Equalization Termination Voltage Delta - Maximum";
CM_ SG_ 2147556096 EqlzTermVDelta "Equalization Termination Voltage Delta";
CM_ SG_ 2147556096 EqlzTermTimeMin "Equalization Termination Time - Minimum";
CM_ SG_ 2147556096 EqlzTermTimeMax "Equalization Termination Time - Maximum";
CM_ SG_ 2147556096 EqlzTermTime "Equalization Termination Time";
CM_ SG_ 2147556096 EqlzSuppEnDis "Equalization Supported Enable/Disable";
CM_ SG_ 2147556096 EqlzPeriodToMin "Equalization Period Timeout - Minimum";
CM_ SG_ 2147556096 EqlzPeriodToMax "Equalization Period Timeout - Maximum";
CM_ SG_ 2147556096 EqlzPeriodTo "Equalization Period Timeout";
CM_ SG_ 2147556096 DesiredEqlzVMin "Desired Equalization Voltage - Minimum";
CM_ SG_ 2147556096 DesiredEqlzVMax "Desired Equalization Voltage - Maximum";
CM_ SG_ 2147556096 DesiredEqlzV "Desired Equalization Voltage";
CM_ SG_ 2147556096 DesiredEqlzIMin "Desired Equalization Current - Minimum";
CM_ SG_ 2147556096 DesiredEqlzIMax "Desired Equalization Current - Maximum";
CM_ SG_ 2147556096 DesiredEqlzI "Desired Equalization Current";
CM_ SG_ 2147556096 DcSrcId "DC Source Identifier";
CM_ SG_ 2147556096 ConcurAccCtr "Concurrent Access Counter";
CM_ SG_ 2147556096 CfgType "Configuration Type";
CM_ SG_ 2147556096 BattType "Battery Type";
CM_ BO_ 2147556352 "Charger Configuration - Constant Voltage Constant ";
CM_ SG_ 2147556352 MsgCount "Message Count";
CM_ SG_ 2147556352 DesiredOutVMin "Desired Output Voltage - Minimum";
CM_ SG_ 2147556352 DesiredOutVMax "Desired Output Voltage - Maximum";
CM_ SG_ 2147556352 DesiredOutV "Desired Output Voltage";
CM_ SG_ 2147556352 DesiredOutIMin "Desired Output Current - Minimum";
CM_ SG_ 2147556352 DesiredOutIMax "Desired Output Current - Maximum";
CM_ SG_ 2147556352 DesiredOutI "Desired Output Current";
CM_ SG_ 2147556352 DcSrcId "DC Source Identifier";
CM_ SG_ 2147556352 ConcurAccCtr "Concurrent Access Counter";
CM_ SG_ 2147556352 CfgType "Configuration Type";
CM_ SG_ 2147556352 BattType "Battery Type";
CM_ BO_ 2147555072 "Charger Configuration - Bulk";
CM_ SG_ 2147555072 MsgCount "Message Count";
CM_ SG_ 2147555072 DesiredBulkVMin "Desired Bulk Voltage - Minimum";
CM_ SG_ 2147555072 DesiredBulkVMax "Desired Bulk Voltage - Maximum";
CM_ SG_ 2147555072 DesiredBulkV "Desired Bulk Voltage";
CM_ SG_ 2147555072 DesiredBulkIMin "Desired Bulk Current - Minimum";
CM_ SG_ 2147555072 DesiredBulkIMax "Desired Bulk Current - Maximum";
CM_ SG_ 2147555072 DesiredBulkI "Desired Bulk Current";
CM_ SG_ 2147555072 DcSrcId "DC Source Identifier";
CM_ SG_ 2147555072 ConcurAccCtr "Concurrent Access Counter";
CM_ SG_ 2147555072 CfgType "Configuration Type";
CM_ SG_ 2147555072 BulkTermVMin "Bulk Termination Voltage - Minimum";
CM_ SG_ 2147555072 BulkTermVMax "Bulk Termination Voltage - Maximum";
CM_ SG_ 2147555072 BulkTermV "Bulk Termination Voltage";
CM_ SG_ 2147555072 BulkTermTimeMin "Bulk Termination Time - Minimum";
CM_ SG_ 2147555072 BulkTermTimeMax "Bulk Termination Time - Maximum";
CM_ SG_ 2147555072 BulkTermTime "Bulk Termination Time";
CM_ SG_ 2147555072 BulkPeriodToMin "Bulk Period Timeout - Minimum";
CM_ SG_ 2147555072 BulkPeriodToMax "Bulk Period Timeout - Maximum";
CM_ SG_ 2147555072 BulkPeriodTo "Bulk Period Timeout";
CM_ SG_ 2147555072 BattType "Battery Type";
CM_ BO_ 2147555328 "Charger Configuration - Absorption";
CM_ SG_ 2147555328 MsgCount "Message Count";
CM_ SG_ 2147555328 DesiredAbsVMin "Desired Absorption Voltage - Minimum";
CM_ SG_ 2147555328 DesiredAbsVMax "Desired Absorption Voltage - Maximum";
CM_ SG_ 2147555328 DesiredAbsV "Desired Absorption Voltage";
CM_ SG_ 2147555328 DesiredAbsIMin "Desired Absorption Current - Minimum";
CM_ SG_ 2147555328 DesiredAbsIMax "Desired Absorption Current - Maximum";
CM_ SG_ 2147555328 DesiredAbsI "Desired Absorption Current";
CM_ SG_ 2147555328 DcSrcId "DC Source Identifier";
CM_ SG_ 2147555328 ConcurAccCtr "Concurrent Access Counter";
CM_ SG_ 2147555328 CfgType "Configuration Type";
CM_ SG_ 2147555328 BattType "Battery Type";
CM_ SG_ 2147555328 AbsTermTimeIMin "Absorption Termination Time - Current - Minimum";
CM_ SG_ 2147555328 AbsTermTimeIMax "Absorption Termination Time - Current - Maximum";
CM_ SG_ 2147555328 AbsTermTimeI "Absorption Termination Time - Current";
CM_ SG_ 2147555328 AbsTermTimeConstVMin "Absorption Termination Time - Constant Voltage - Minimum";
CM_ SG_ 2147555328 AbsTermTimeConstVMax "Absorption Termination Time - Constant Voltage - Maximum";
CM_ SG_ 2147555328 AbsTermTimeConstV "Absorption Termination Time - Constant Voltage";
CM_ SG_ 2147555328 AbsTermIMin "Absorption Termination Current - Minimum";
CM_ SG_ 2147555328 AbsTermIMax "Absorption Termination Current - Maximum";
CM_ SG_ 2147555328 AbsTermI "Absorption Termination Current";
CM_ SG_ 2147555328 AbsPeriodToMin "Absorption Period Timeout - Minimum";
CM_ SG_ 2147555328 AbsPeriodToMax "Absorption Period Timeout - Maximum";
CM_ SG_ 2147555328 AbsPeriodTo "Absorption Period Timeout";
BA_DEF_ BO_  "J1939PGPrio" INT 0 7;
BA_DEF_ BO_  "J1939PGR1" INT 0 1;
BA_DEF_ BO_  "J1939PGDest" INT 0 255;
BA_DEF_ BO_  "J1939PGSrc" INT 0 255;
BA_DEF_ BO_  "CycleTime" INT 5 1000;
BA_DEF_ BO_  "SingleFrame" INT 0 1;
BA_DEF_DEF_  "J1939PGPrio" 0;
BA_DEF_DEF_  "J1939PGR1" 0;
BA_DEF_DEF_  "J1939PGDest" 0;
BA_DEF_DEF_  "J1939PGSrc" 0;
BA_DEF_DEF_  "CycleTime" 100;
BA_DEF_DEF_  "SingleFrame" 0;
BA_ "J1939PGPrio" BO_ 2147573248 6;
BA_ "J1939PGDest" BO_ 2147573248 255;
BA_ "J1939PGPrio" BO_ 2147569664 6;
BA_ "J1939PGDest" BO_ 2147569664 255;
BA_ "J1939PGPrio" BO_ 2147568128 6;
BA_ "J1939PGDest" BO_ 2147568128 255;
BA_ "J1939PGPrio" BO_ 2147568896 6;
BA_ "J1939PGDest" BO_ 2147568896 255;
BA_ "J1939PGPrio" BO_ 2147568640 6;
BA_ "J1939PGDest" BO_ 2147568640 255;
BA_ "J1939PGPrio" BO_ 2147568384 6;
BA_ "J1939PGDest" BO_ 2147568384 255;
BA_ "J1939PGPrio" BO_ 2147561472 6;
BA_ "J1939PGDest" BO_ 2147561472 255;
BA_ "SingleFrame" BO_ 2147561472 1;
BA_ "J1939PGPrio" BO_ 2147561216 6;
BA_ "J1939PGDest" BO_ 2147561216 255;
BA_ "SingleFrame" BO_ 2147561216 1;
BA_ "J1939PGPrio" BO_ 2147560960 6;
BA_ "J1939PGDest" BO_ 2147560960 255;
BA_ "SingleFrame" BO_ 2147560960 1;
BA_ "J1939PGPrio" BO_ 2147563776 7;
BA_ "J1939PGDest" BO_ 2147563776 255;
BA_ "J1939PGPrio" BO_ 2147610821 6;
BA_ "J1939PGDest" BO_ 2147610821 255;
BA_ "CycleTime" BO_ 2147610821 500;
BA_ "J1939PGPrio" BO_ 2147610625 6;
BA_ "J1939PGDest" BO_ 2147610625 255;
BA_ "CycleTime" BO_ 2147610625 500;
BA_ "J1939PGPrio" BO_ 2147549440 6;
BA_ "J1939PGDest" BO_ 2147549440 255;
BA_ "J1939PGPrio" BO_ 2147549952 6;
BA_ "J1939PGDest" BO_ 2147549952 255;
BA_ "J1939PGPrio" BO_ 2147550464 6;
BA_ "J1939PGDest" BO_ 2147550464 255;
BA_ "J1939PGPrio" BO_ 2147599104 6;
BA_ "J1939PGDest" BO_ 2147599104 255;
BA_ "J1939PGPrio" BO_ 2147570432 6;
BA_ "J1939PGDest" BO_ 2147570432 255;
BA_ "SingleFrame" BO_ 2147570432 1;
BA_ "J1939PGPrio" BO_ 2147549696 6;
BA_ "J1939PGDest" BO_ 2147549696 255;
BA_ "J1939PGPrio" BO_ 2147550208 6;
BA_ "J1939PGDest" BO_ 2147550208 255;
BA_ "J1939PGPrio" BO_ 2147556608 6;
BA_ "J1939PGDest" BO_ 2147556608 255;
BA_ "J1939PGPrio" BO_ 2147612681 3;
BA_ "J1939PGDest" BO_ 2147612681 255;
BA_ "CycleTime" BO_ 2147612681 500;
BA_ "SingleFrame" BO_ 2147612681 1;
BA_ "J1939PGPrio" BO_ 2147567616 6;
BA_ "J1939PGDest" BO_ 2147567616 255;
BA_ "J1939PGPrio" BO_ 2147575552 6;
BA_ "J1939PGDest" BO_ 2147575552 255;
BA_ "CycleTime" BO_ 2147575552 5;
BA_ "J1939PGPrio" BO_ 2147565568 6;
BA_ "J1939PGDest" BO_ 2147565568 255;
BA_ "SingleFrame" BO_ 2147565568 1;
BA_ "J1939PGPrio" BO_ 2147606016 6;
BA_ "J1939PGDest" BO_ 2147606016 255;
BA_ "SingleFrame" BO_ 2147606016 1;
BA_ "J1939PGPrio" BO_ 2147610626 6;
BA_ "J1939PGDest" BO_ 2147610626 255;
BA_ "J1939PGPrio" BO_ 2147559424 6;
BA_ "J1939PGDest" BO_ 2147559424 255;
BA_ "SingleFrame" BO_ 2147559424 1;
BA_ "J1939PGPrio" BO_ 2147610638 6;
BA_ "J1939PGDest" BO_ 2147610638 255;
BA_ "CycleTime" BO_ 2147610638 500;
BA_ "J1939PGPrio" BO_ 2147610658 6;
BA_ "J1939PGDest" BO_ 2147610658 255;
BA_ "J1939PGPrio" BO_ 2147610659 6;
BA_ "J1939PGDest" BO_ 2147610659 255;
BA_ "J1939PGPrio" BO_ 2147610817 6;
BA_ "J1939PGDest" BO_ 2147610817 255;
BA_ "J1939PGPrio" BO_ 2147610657 6;
BA_ "J1939PGDest" BO_ 2147610657 255;
BA_ "J1939PGPrio" BO_ 2147610814 6;
BA_ "J1939PGDest" BO_ 2147610814 255;
BA_ "J1939PGPrio" BO_ 2147610816 6;
BA_ "J1939PGDest" BO_ 2147610816 255;
BA_ "J1939PGPrio" BO_ 2147610650 6;
BA_ "J1939PGDest" BO_ 2147610650 255;
BA_ "J1939PGPrio" BO_ 2147600384 6;
BA_ "J1939PGDest" BO_ 2147600384 255;
BA_ "CycleTime" BO_ 2147600384 5;
BA_ "SingleFrame" BO_ 2147600384 1;
BA_ "J1939PGPrio" BO_ 2147562752 6;
BA_ "J1939PGDest" BO_ 2147562752 255;
BA_ "SingleFrame" BO_ 2147562752 1;
BA_ "J1939PGPrio" BO_ 2147555584 6;
BA_ "J1939PGDest" BO_ 2147555584 255;
BA_ "J1939PGPrio" BO_ 2147559168 6;
BA_ "J1939PGDest" BO_ 2147559168 255;
BA_ "J1939PGPrio" BO_ 2147555840 6;
BA_ "J1939PGDest" BO_ 2147555840 255;
BA_ "J1939PGPrio" BO_ 2147556096 6;
BA_ "J1939PGDest" BO_ 2147556096 255;
BA_ "J1939PGPrio" BO_ 2147556352 6;
BA_ "J1939PGDest" BO_ 2147556352 255;
BA_ "J1939PGPrio" BO_ 2147555072 6;
BA_ "J1939PGDest" BO_ 2147555072 255;
BA_ "J1939PGPrio" BO_ 2147555328 6;
BA_ "J1939PGDest" BO_ 2147555328 255;
VAL_ 2147573248 ShoreBreakerMode 0 "Manual" 1 "Auto" 2 "Reserved" 3 "No Change" ;
VAL_ 2147573248 GenBreakerMode 0 "Manual" 1 "Auto" 2 "Reserved" 3 "No Change" ;
VAL_ 2147573248 CfgType 0 "User" 1 "OEM" 2 "Factory" 3 "Reserved" ;
VAL_ 2147573248 BreakerDeratingEnDis 0 "Off" 1 "On" 2 "Reserved" 3 "No Change" ;
VAL_ 2147569664 MfgStep 0 "Board Test" 1 "Soak Test" 2 "Final Test" 253 "Reserved" 254 "Out Of Range" 255 "Data Not Available Do Not Change" ;
VAL_ 2147568128 IndicState 0 "Off" 1 "On" 2 "Reserved" 3 "No Change" ;
VAL_ 2147568128 IndicId 0 "Fault" 1 "Network Activity" 2 "Generator On" 3 "Power On" 4 "External Action" 5 "Charging" 6 "Inverting" 7 "Ac In" 8 "Buzzer" 9 "AGS External On" 10 "Backlight" 11 "Low Battery" 12 "Charge Enable" 13 "Invert Enable" 14 "Bulk" 15 "Absorption" 16 "Float" 17 "Equalize" 18 "Network Red XanBus" 19 "Network Green XanBus" 20 "Network Red Other" 21 "Network Green Other" 22 "Current Level 1" 23 "Current Level 2" 24 "Current Level 3" 25 "Current Level 4" 26 "Current Level 5" 27 "Voltage Level 1" 28 "Voltage Level 2" 29 "Voltage Level 3" 30 "Voltage Level 4" 31 "Voltage Level 5" ;
VAL_ 2147568896 FanId 0 "Main" 1 "Auxiliary" ;
VAL_ 2147568640 CntctState 0 "Off" 1 "On" 2 "Error" 3 "Unknown" ;
VAL_ 2147568640 CntctId 0 "Cooldown Relay" 1 "Preheat Relay" 2 "Start Relay" 3 "Run Stop Relay" 4 "Escape Button" 5 "Enter Button" 6 "Scroll Button" 7 "Menu Button" 8 "System On Button" 9 "External Off" 10 "External On" 11 "Thermostat 1" 12 "Thermostat 2" 13 "B Plus Sense" 14 "Up Arrow Button" 15 "Down Arrow Button" 16 "Exit Button" 17 "AGS External Shutdown" 18 "Reset Button" 19 "Invert Enable Button" 20 "Charge Enable Button" 21 "Transfer Relay" 22 "Triac Relay" 23 "DC Under Voltage Relay" 24 "Network Power Supply Enable" 25 "Auxiliary Power Supply Enable" 26 "Triac" 27 "DC DC Stage Enable" 28 "Invert Stage Enable" 29 "Output Relay Enable" 30 "AC1 Relay" 31 "AC2 Relay" 32 "Neutral Relay" 33 "Equalize Button" ;
VAL_ 2147568384 CntctState 0 "Off" 1 "On" 2 "Reserved" 3 "No Change" ;
VAL_ 2147568384 CntctId 0 "Cooldown Relay" 1 "Preheat Relay" 2 "Start Relay" 3 "Run Stop Relay" 4 "Escape Button" 5 "Enter Button" 6 "Scroll Button" 7 "Menu Button" 8 "System On Button" 9 "External Off" 10 "External On" 11 "Thermostat 1" 12 "Thermostat 2" 13 "B Plus Sense" 14 "Up Arrow Button" 15 "Down Arrow Button" 16 "Exit Button" 17 "AGS External Shutdown" 18 "Reset Button" 19 "Invert Enable Button" 20 "Charge Enable Button" 21 "Transfer Relay" 22 "Triac Relay" 23 "DC Under Voltage Relay" 24 "Network Power Supply Enable" 25 "Auxiliary Power Supply Enable" 26 "Triac" 27 "DC DC Stage Enable" 28 "Invert Stage Enable" 29 "Output Relay Enable" 30 "AC1 Relay" 31 "AC2 Relay" 32 "Neutral Relay" 33 "Equalize Button" ;
VAL_ 2147610821 DeratingSts 0 "Off" 1 "On" 2 "Error" 3 "Unknown" ;
VAL_ 2147610821 DeratingReason 0 "Not On" 1 "Hi Internal Temperature" 2 "Hi DC Input Voltage" 4 "Battery Voltage" 8 "AC Input Voltage" 16 "AC Input Current" 32 "Breaker" ;
VAL_ 2147610821 DcSrcId 0 "Invalid" 1 "None" 2 "Anonymous" 3 "HouseBatBank1" 4 "HouseBatBank2" 5 "HouseBatBank3" 6 "HouseBatBank4" 7 "HouseBatBank5" 8 "HouseBatBank6" 9 "StartBatBank1" 10 "StartBatBank2" 11 "StartBatBank3" 12 "StartBatBank4" 13 "StartBatBank5" 14 "StartBatBank6" 21 "SolarArray1" 22 "SolarArray2" 23 "SolarArray3" 24 "SolarArray4" 25 "SolarArray5" 26 "SolarArray6" 27 "SolarArray7" 28 "SolarArray8" 29 "SolarArray9" 30 "SolarArray10" 31 "SolarArray11" 32 "SolarArray12" 33 "SolarArray13" 34 "SolarArray14" 35 "SolarArray15" 36 "SolarArray16" 252 "All" 253 "Reserved" 254 "Out of Range" 255 "Data Not Available Do Not Change" ;
VAL_ 2147610625 TempSensId 0 "Battery 1" 1 "Battery 2" 2 "Battery 3" 3 "Battery 4" 4 "Battery 5" 5 "Battery 6" 10 "Ambient 1" 11 "Ambient 2" 12 "Ambient 3" 13 "Ambient 4" 14 "Shunt 1" 15 "Shunt 2" 16 "Shunt 3" 17 "Shunt 4" 253 "Reserved" 254 "Out of Range" 255 "Data Not Available Do Not Change" ;
VAL_ 2147610625 DcSrcId 0 "Invalid" 1 "None" 2 "Anonymous" 3 "HouseBatBank1" 4 "HouseBatBank2" 5 "HouseBatBank3" 6 "HouseBatBank4" 7 "HouseBatBank5" 8 "HouseBatBank6" 9 "StartBatBank1" 10 "StartBatBank2" 11 "StartBatBank3" 12 "StartBatBank4" 13 "StartBatBank5" 14 "StartBatBank6" 21 "SolarArray1" 22 "SolarArray2" 23 "SolarArray3" 24 "SolarArray4" 25 "SolarArray5" 26 "SolarArray6" 27 "SolarArray7" 28 "SolarArray8" 29 "SolarArray9" 30 "SolarArray10" 31 "SolarArray11" 32 "SolarArray12" 33 "SolarArray13" 34 "SolarArray14" 35 "SolarArray15" 36 "SolarArray16" 252 "All" 253 "Reserved" 254 "Out of Range" 255 "Data Not Available Do Not Change" ;
VAL_ 2147549440 RefEvtId 436 "SPS Auto Off Array V Low" 437 "SPS Auto On Array V Low" 438 "SPS Auto Off Ground Flt" 439 "SPS Auto On Ground Flt" 440 "SPS Auto Off External Shutdown Flt" 0 "None" 10 "Control Command Hibernate" 11 "Control Command Safe" 12 "Control Command Power Save" 13 "Control Command Operating" 14 "Control Command Diagnostic" 15 "Control Command Last Mode" 20 "Reset Command Reboot" 21 "Reset Command Download" 22 "Reset Command Oem" 23 "Reset Command Factory" 24 "Reset Command Reboot Clear Nv" 25 "Powered Up" 30 "Clear Command Active Faults" 31 "Clear Command Fault Log" 32 "Clear Command Active Warns" 33 "Clear Command Warn Log" 34 "Clear Command State Event Log" 35 "Clear Command Comm Stats" 36 "Clear Command Stats" 37 "Clear Command All" 40 "Date Time Configured" 50 "Warn Cleared" 51 "Fault Cleared" 52 "Fault Set" 60 "User Cfg Changed" 61 "Oem Cfg Changed" 70 "Triggered Fault" 250 "Shutdown Threshold" 251 "Shutdown Hysteresis" 252 "Warning Threshold" 253 "Warning Hysteresis" 254 "Transfer Threshold" 255 "Fan 0 Threshold" 256 "Fan 10 Threshold" 257 "Fan 20 Threshold" 258 "Fan 30 Threshold" 259 "Fan 40 Threshold" 260 "Fan 50 Threshold" 261 "Fan 60 Threshold" 262 "Fan 70 Threshold" 263 "Fan 80 Threshold" 264 "Fan 90 Threshold" 265 "Fan 100 Threshold" 266 "Relay Open Threshold" 267 "Relay Close Threshold" 268 "Charger Derating Ac In V" 269 "Charger Derating Ac In I" 270 "Charger Derating Ext Temp" 271 "Charger Derating Int Temp" 272 "Charger Derating Ripple V" 273 "Lost Ac Threshold" 274 "Lost Ac Hysteresis" 275 "Imm Shutdown Threshold" 276 "Imm Shutdown Hysteresis" 277 "Charger Shutdown Threshold" 278 "Charger Shutdown Hysteresis" 279 "Charger Warning Threshold" 280 "Charger Warning Hysteresis" 281 "Inverter Shutdown Threshold" 282 "Inverter Shutdown Hysteresis" 283 "Inverter Warning Threshold" 284 "Inverter Warning Hysteresis" 285 "Charger Derating Temp Start Point" 286 "Charger Derating Temp End Point" 287 "Charger Recharge Threshold" 300 "Ags Exercise Start" 301 "Ags Exercise Stop" 302 "Ags Quiet Time Begin" 303 "Ags Quiet Time End" 304 "Ags Battery Soc Start" 305 "Ags Battery Soc Stop" 306 "Ags Dc V Start" 307 "Ags Dc V Stop" 308 "Ags Ac I Start" 309 "Ags Ac I Stop" 310 "Ags Contact Start" 311 "Ags Contact Stop" 312 "Ags Float Stop" 313 "Ags Absorp Stop" 314 "Ags Manual On" 315 "Ags Manual Off" 316 "Ags Auto" 317 "Ags External On" 318 "Ags External Off" 319 "Gen External On" 320 "Gen External Off" 321 "Ags External Shutdown" 322 "Ags Auto Off" 323 "Ags Dc I Start" 324 "Ags Dc I Stop" 325 "Ags Ac Power Start" 326 "Ags Ac Power Stop" 400 "Sps Manual Off" 401 "Sps Manual On" 410 "Sps Auto Off" 411 "Sps Auto On" 420 "Sps Auto Off Batt V Low" 421 "Sps Auto On Batt V Low" 422 "Sps Auto Off Batt V High" 423 "Sps Auto On Batt V High" 424 "Sps Auto Off Array V High" 425 "Sps Auto On Array V High" 426 "Sps Auto Off Batt Temp Low" 427 "Sps Auto On Batt Temp Low" 428 "Sps Auto Off Batt Temp High" 429 "Sps Auto On Batt Temp High" 430 "Sps Auto Off Heat Sink Temp High" 431 "Sps Auto On Heat Sink Temp High" 432 "Sps Auto Off Fault" 433 "Sps Auto On Fault" 434 "Aps Check Timeout" 435 "Aps Qualify Timeout" 512 "Resume From Safe" 513 "AC Fault Set" 514 "Invert Fault Set" 515 "Charge Fault Set" 516 "Charger Enable" 517 "Charger Disable" 518 "Inverter Enable" 519 "Inverter Disable" 520 "Charge Suspend On" 521 "Charge Suspend Off" 522 "AC Good" 523 "AC Bad" 524 "Load Sense Enable" 525 "Load Sense Active" 526 "Invert Active" 527 "Bulk Exit" 528 "Absorption Exit" 529 "Float Exit" 530 "Float 3-Stage Set" 531 "Float 2-Stage Set" 532 "Equalize Enable" 533 "Equalize Disable" 534 "Equalize Exit" 535 "Load Sense Disable" 536 "Sell To Grid Enabled" 537 "Sell To Grid Disabled" 538 "Grid Support Enable" 539 "Grid Support Disable" 540 "Gen Support Enable" 541 "Gen Support Disable" 542 "Peak Load Shaving Enable" 543 "Peak Load Shaving Disable" 544 "Peak Load Shaving Tod Start" 545 "Peak Load Shaving Tod Stop" 546 "Unit Off" 547 "System Absorption Exit" 548 "System Inverter Enable" 549 "System AC Good" 550 "Anti Islanding Condition" 551 "Hibernate Timeout" 552 "External Sync Error" 553 "External Suspend Request" 554 "Engaging Charger" 555 "Engaging Gen Support" 556 "Grid Tie Engage Timeout" 557 "Gen Support Engage Timeout" 558 "Charge Engage Timeout" 559 "Inverter Engage Timeout" 560 "Charge Exit Timeout" 561 "Grid Support Entry Amps" 562 "Grid Support Exit Amps" 563 "Gen Support Entry Amps" 564 "Gen Support Exit Amps" 565 "Grid Support Entry Vdc" 566 "Grid Support Exit Vdc" 567 "Low Batt Cut Off Entry Vdc" 568 "Low Batt Recharge Vdc" 569 "Low Batt Cut Off Exit Vdc" 570 "Invert To Bypass Timeout" 571 "Force Charge" 572 "System Engage Bulk Charge" 441 "SPS Auto On External Shutdown Flt" 442 "SPS Auto Off Input Over Volt Flt" 443 "SPS Auto On Input Over Volt Flt" 444 "SPS Auto Off Input Over Volt Err" 445 "SPS Auto On Input Over Volt Err" 446 "SPS Auto Off Input Over Volt Wrn" 447 "SPS Auto On Input Over Volt Wrn" 448 "SPS Auto Off Output Over Volt Err" 449 "SPS Auto On Output Over Volt Err" 450 "SPS Auto Off Output Over Volt Wrn" 451 "SPS Auto On Output Over Volt Wrn" 452 "SPS Auto Off Output Under Volt Err" 453 "SPS Auto On Output Under Volt Err" 454 "SPS Auto Off Output Under Volt Wrn" 455 "SPS Auto On Output Under Volt Wrn" 456 "SPS Auto Off Output Over Curr Err" 457 "SPS Auto On Output Over Curr Err" 458 "SPS Auto Off Batt Over Temp Err" 459 "SPS Auto On Batt Over Temp Err" 460 "SPS Auto Off Batt Over Temp Wrn" 461 "SPS Auto On Batt Over Temp Wrn" 462 "SPS Auto Off Batt Under Temp Wrn" 463 "SPS Auto On Batt Under Temp Wrn" 464 "SPS Auto Off Heatsink Over Temp Err" 465 "SPS Auto On Heatsink Over Temp Err" 466 "SPS Auto Off Heatsink Over Temp Wrn" 467 "SPS Auto On Heatsink Over Temp Wrn" 468 "SPS Auto Off Ambient Over Temp Err" 469 "SPS Auto On Ambient Over Temp Err" 470 "SPS Auto Off Ambient Over Temp Wrn" 471 "SPS Auto On Ambient Over Temp Wrn" 472 "SPS Auto Off Capacitor Over Temp Err" 473 "SPS Auto On Capacitor Over Temp Err" 474 "SPS Auto Off Fan Flt" 475 "SPS Auto On Fan Flt" 476 "SPS Auto Off Fan Err" 477 "SPS Auto On Fan Err" 478 "SPS Auto Off Input Over Curr Err" 479 "SPS Auto On Input Over Curr Err" 480 "SPS Auto Off Output Over Curr Flt" 481 "SPS Auto On Output Over Curr Flt" 482 "SPS Auto Off Network PS Flt" 483 "SPS Auto On Network PS Flt" 484 "SPS Auto Off Setup Flt" 485 "SPS Auto On Setup Flt" 38 "Clear Command User Stats" 573 "AC Good Pending" 574 "Grid Safe" 585 "PLS Time In Float Ready" 575 "Power Conversion Fault" 576 "Low Battery Support Exit" 577 "Grid Support Exit" 578 "GFS Enable" 579 "GFS Disable" 580 "Force Sell" 486 "SPS Auto On Bulk Exit" 487 "SPS Auto Off Bulk Exit" 488 "SPS Auto On Absorption Exit" 489 "SPS Auto Off Absorption Exit" 490 "SPS Auto On State Of Charge Low" 491 "SPS Auto Off State Of Charge Low" 492 "SPS Auto On Time Of Day" 493 "SPS Auto Off Time Of Day" 581 "Sell Time Of Day Start" 582 "Sell Time Of Day Stop" 583 "Aux Port Time Of Day Start" 584 "Aux Port Time Of Day Stop" ;
VAL_ 2147549440 EvtId 436 "SPS Auto Off Array V Low" 437 "SPS Auto On Array V Low" 438 "SPS Auto Off Ground Flt" 439 "SPS Auto On Ground Flt" 440 "SPS Auto Off External Shutdown Flt" 0 "None" 10 "Control Command Hibernate" 11 "Control Command Safe" 12 "Control Command Power Save" 13 "Control Command Operating" 14 "Control Command Diagnostic" 15 "Control Command Last Mode" 20 "Reset Command Reboot" 21 "Reset Command Download" 22 "Reset Command Oem" 23 "Reset Command Factory" 24 "Reset Command Reboot Clear Nv" 25 "Powered Up" 30 "Clear Command Active Faults" 31 "Clear Command Fault Log" 32 "Clear Command Active Warns" 33 "Clear Command Warn Log" 34 "Clear Command State Event Log" 35 "Clear Command Comm Stats" 36 "Clear Command Stats" 37 "Clear Command All" 40 "Date Time Configured" 50 "Warn Cleared" 51 "Fault Cleared" 52 "Fault Set" 60 "User Cfg Changed" 61 "Oem Cfg Changed" 70 "Triggered Fault" 250 "Shutdown Threshold" 251 "Shutdown Hysteresis" 252 "Warning Threshold" 253 "Warning Hysteresis" 254 "Transfer Threshold" 255 "Fan 0 Threshold" 256 "Fan 10 Threshold" 257 "Fan 20 Threshold" 258 "Fan 30 Threshold" 259 "Fan 40 Threshold" 260 "Fan 50 Threshold" 261 "Fan 60 Threshold" 262 "Fan 70 Threshold" 263 "Fan 80 Threshold" 264 "Fan 90 Threshold" 265 "Fan 100 Threshold" 266 "Relay Open Threshold" 267 "Relay Close Threshold" 268 "Charger Derating Ac In V" 269 "Charger Derating Ac In I" 270 "Charger Derating Ext Temp" 271 "Charger Derating Int Temp" 272 "Charger Derating Ripple V" 273 "Lost Ac Threshold" 274 "Lost Ac Hysteresis" 275 "Imm Shutdown Threshold" 276 "Imm Shutdown Hysteresis" 277 "Charger Shutdown Threshold" 278 "Charger Shutdown Hysteresis" 279 "Charger Warning Threshold" 280 "Charger Warning Hysteresis" 281 "Inverter Shutdown Threshold" 282 "Inverter Shutdown Hysteresis" 283 "Inverter Warning Threshold" 284 "Inverter Warning Hysteresis" 285 "Charger Derating Temp Start Point" 286 "Charger Derating Temp End Point" 287 "Charger Recharge Threshold" 300 "Ags Exercise Start" 301 "Ags Exercise Stop" 302 "Ags Quiet Time Begin" 303 "Ags Quiet Time End" 304 "Ags Battery Soc Start" 305 "Ags Battery Soc Stop" 306 "Ags Dc V Start" 307 "Ags Dc V Stop" 308 "Ags Ac I Start" 309 "Ags Ac I Stop" 310 "Ags Contact Start" 311 "Ags Contact Stop" 312 "Ags Float Stop" 313 "Ags Absorp Stop" 314 "Ags Manual On" 315 "Ags Manual Off" 316 "Ags Auto" 317 "Ags External On" 318 "Ags External Off" 319 "Gen External On" 320 "Gen External Off" 321 "Ags External Shutdown" 322 "Ags Auto Off" 323 "Ags Dc I Start" 324 "Ags Dc I Stop" 325 "Ags Ac Power Start" 326 "Ags Ac Power Stop" 400 "Sps Manual Off" 401 "Sps Manual On" 410 "Sps Auto Off" 411 "Sps Auto On" 420 "Sps Auto Off Batt V Low" 421 "Sps Auto On Batt V Low" 422 "Sps Auto Off Batt V High" 423 "Sps Auto On Batt V High" 424 "Sps Auto Off Array V High" 425 "Sps Auto On Array V High" 426 "Sps Auto Off Batt Temp Low" 427 "Sps Auto On Batt Temp Low" 428 "Sps Auto Off Batt Temp High" 429 "Sps Auto On Batt Temp High" 430 "Sps Auto Off Heat Sink Temp High" 431 "Sps Auto On Heat Sink Temp High" 432 "Sps Auto Off Fault" 433 "Sps Auto On Fault" 434 "Aps Check Timeout" 435 "Aps Qualify Timeout" 512 "Resume From Safe" 513 "AC Fault Set" 514 "Invert Fault Set" 515 "Charge Fault Set" 516 "Charger Enable" 517 "Charger Disable" 518 "Inverter Enable" 519 "Inverter Disable" 520 "Charge Suspend On" 521 "Charge Suspend Off" 522 "AC Good" 523 "AC Bad" 524 "Load Sense Enable" 525 "Load Sense Active" 526 "Invert Active" 527 "Bulk Exit" 528 "Absorption Exit" 529 "Float Exit" 530 "Float 3-Stage Set" 531 "Float 2-Stage Set" 532 "Equalize Enable" 533 "Equalize Disable" 534 "Equalize Exit" 535 "Load Sense Disable" 536 "Sell To Grid Enabled" 537 "Sell To Grid Disabled" 538 "Grid Support Enable" 539 "Grid Support Disable" 540 "Gen Support Enable" 541 "Gen Support Disable" 542 "Peak Load Shaving Enable" 543 "Peak Load Shaving Disable" 544 "Peak Load Shaving Tod Start" 545 "Peak Load Shaving Tod Stop" 546 "Unit Off" 547 "System Absorption Exit" 548 "System Inverter Enable" 549 "System AC Good" 550 "Anti Islanding Condition" 551 "Hibernate Timeout" 552 "External Sync Error" 553 "External Suspend Request" 554 "Engaging Charger" 555 "Engaging Gen Support" 556 "Grid Tie Engage Timeout" 557 "Gen Support Engage Timeout" 558 "Charge Engage Timeout" 559 "Inverter Engage Timeout" 560 "Charge Exit Timeout" 561 "Grid Support Entry Amps" 562 "Grid Support Exit Amps" 563 "Gen Support Entry Amps" 564 "Gen Support Exit Amps" 565 "Grid Support Entry Vdc" 566 "Grid Support Exit Vdc" 567 "Low Batt Cut Off Entry Vdc" 568 "Low Batt Recharge Vdc" 569 "Low Batt Cut Off Exit Vdc" 570 "Invert To Bypass Timeout" 571 "Force Charge" 572 "System Engage Bulk Charge" 441 "SPS Auto On External Shutdown Flt" 442 "SPS Auto Off Input Over Volt Flt" 443 "SPS Auto On Input Over Volt Flt" 444 "SPS Auto Off Input Over Volt Err" 445 "SPS Auto On Input Over Volt Err" 446 "SPS Auto Off Input Over Volt Wrn" 447 "SPS Auto On Input Over Volt Wrn" 448 "SPS Auto Off Output Over Volt Err" 449 "SPS Auto On Output Over Volt Err" 450 "SPS Auto Off Output Over Volt Wrn" 451 "SPS Auto On Output Over Volt Wrn" 452 "SPS Auto Off Output Under Volt Err" 453 "SPS Auto On Output Under Volt Err" 454 "SPS Auto Off Output Under Volt Wrn" 455 "SPS Auto On Output Under Volt Wrn" 456 "SPS Auto Off Output Over Curr Err" 457 "SPS Auto On Output Over Curr Err" 458 "SPS Auto Off Batt Over Temp Err" 459 "SPS Auto On Batt Over Temp Err" 460 "SPS Auto Off Batt Over Temp Wrn" 461 "SPS Auto On Batt Over Temp Wrn" 462 "SPS Auto Off Batt Under Temp Wrn" 463 "SPS Auto On Batt Under Temp Wrn" 464 "SPS Auto Off Heatsink Over Temp Err" 465 "SPS Auto On Heatsink Over Temp Err" 466 "SPS Auto Off Heatsink Over Temp Wrn" 467 "SPS Auto On Heatsink Over Temp Wrn" 468 "SPS Auto Off Ambient Over Temp Err" 469 "SPS Auto On Ambient Over Temp Err" 470 "SPS Auto Off Ambient Over Temp Wrn" 471 "SPS Auto On Ambient Over Temp Wrn" 472 "SPS Auto Off Capacitor Over Temp Err" 473 "SPS Auto On Capacitor Over Temp Err" 474 "SPS Auto Off Fan Flt" 475 "SPS Auto On Fan Flt" 476 "SPS Auto Off Fan Err" 477 "SPS Auto On Fan Err" 478 "SPS Auto Off Input Over Curr Err" 479 "SPS Auto On Input Over Curr Err" 480 "SPS Auto Off Output Over Curr Flt" 481 "SPS Auto On Output Over Curr Flt" 482 "SPS Auto Off Network PS Flt" 483 "SPS Auto On Network PS Flt" 484 "SPS Auto Off Setup Flt" 485 "SPS Auto On Setup Flt" 38 "Clear Command User Stats" 573 "AC Good Pending" 574 "Grid Safe" 585 "PLS Time In Float Ready" 575 "Power Conversion Fault" 576 "Low Battery Support Exit" 577 "Grid Support Exit" 578 "GFS Enable" 579 "GFS Disable" 580 "Force Sell" 486 "SPS Auto On Bulk Exit" 487 "SPS Auto Off Bulk Exit" 488 "SPS Auto On Absorption Exit" 489 "SPS Auto Off Absorption Exit" 490 "SPS Auto On State Of Charge Low" 491 "SPS Auto Off State Of Charge Low" 492 "SPS Auto On Time Of Day" 493 "SPS Auto Off Time Of Day" 581 "Sell Time Of Day Start" 582 "Sell Time Of Day Stop" 583 "Aux Port Time Of Day Start" 584 "Aux Port Time Of Day Stop" ;
VAL_ 2147549440 DcSrcId 0 "Invalid" 1 "None" 2 "Anonymous" 3 "HouseBatBank1" 4 "HouseBatBank2" 5 "HouseBatBank3" 6 "HouseBatBank4" 7 "HouseBatBank5" 8 "HouseBatBank6" 9 "StartBatBank1" 10 "StartBatBank2" 11 "StartBatBank3" 12 "StartBatBank4" 13 "StartBatBank5" 14 "StartBatBank6" 21 "SolarArray1" 22 "SolarArray2" 23 "SolarArray3" 24 "SolarArray4" 25 "SolarArray5" 26 "SolarArray6" 27 "SolarArray7" 28 "SolarArray8" 29 "SolarArray9" 30 "SolarArray10" 31 "SolarArray11" 32 "SolarArray12" 33 "SolarArray13" 34 "SolarArray14" 35 "SolarArray15" 36 "SolarArray16" 252 "All" 253 "Reserved" 254 "Out of Range" 255 "Data Not Available Do Not Change" ;
VAL_ 2147549440 CfgType 0 "User" 1 "OEM" 2 "Factory" 3 "Reserved" ;
VAL_ 2147549952 RefEvtId 436 "SPS Auto Off Array V Low" 437 "SPS Auto On Array V Low" 438 "SPS Auto Off Ground Flt" 439 "SPS Auto On Ground Flt" 440 "SPS Auto Off External Shutdown Flt" 0 "None" 10 "Control Command Hibernate" 11 "Control Command Safe" 12 "Control Command Power Save" 13 "Control Command Operating" 14 "Control Command Diagnostic" 15 "Control Command Last Mode" 20 "Reset Command Reboot" 21 "Reset Command Download" 22 "Reset Command Oem" 23 "Reset Command Factory" 24 "Reset Command Reboot Clear Nv" 25 "Powered Up" 30 "Clear Command Active Faults" 31 "Clear Command Fault Log" 32 "Clear Command Active Warns" 33 "Clear Command Warn Log" 34 "Clear Command State Event Log" 35 "Clear Command Comm Stats" 36 "Clear Command Stats" 37 "Clear Command All" 40 "Date Time Configured" 50 "Warn Cleared" 51 "Fault Cleared" 52 "Fault Set" 60 "User Cfg Changed" 61 "Oem Cfg Changed" 70 "Triggered Fault" 250 "Shutdown Threshold" 251 "Shutdown Hysteresis" 252 "Warning Threshold" 253 "Warning Hysteresis" 254 "Transfer Threshold" 255 "Fan 0 Threshold" 256 "Fan 10 Threshold" 257 "Fan 20 Threshold" 258 "Fan 30 Threshold" 259 "Fan 40 Threshold" 260 "Fan 50 Threshold" 261 "Fan 60 Threshold" 262 "Fan 70 Threshold" 263 "Fan 80 Threshold" 264 "Fan 90 Threshold" 265 "Fan 100 Threshold" 266 "Relay Open Threshold" 267 "Relay Close Threshold" 268 "Charger Derating Ac In V" 269 "Charger Derating Ac In I" 270 "Charger Derating Ext Temp" 271 "Charger Derating Int Temp" 272 "Charger Derating Ripple V" 273 "Lost Ac Threshold" 274 "Lost Ac Hysteresis" 275 "Imm Shutdown Threshold" 276 "Imm Shutdown Hysteresis" 277 "Charger Shutdown Threshold" 278 "Charger Shutdown Hysteresis" 279 "Charger Warning Threshold" 280 "Charger Warning Hysteresis" 281 "Inverter Shutdown Threshold" 282 "Inverter Shutdown Hysteresis" 283 "Inverter Warning Threshold" 284 "Inverter Warning Hysteresis" 285 "Charger Derating Temp Start Point" 286 "Charger Derating Temp End Point" 287 "Charger Recharge Threshold" 300 "Ags Exercise Start" 301 "Ags Exercise Stop" 302 "Ags Quiet Time Begin" 303 "Ags Quiet Time End" 304 "Ags Battery Soc Start" 305 "Ags Battery Soc Stop" 306 "Ags Dc V Start" 307 "Ags Dc V Stop" 308 "Ags Ac I Start" 309 "Ags Ac I Stop" 310 "Ags Contact Start" 311 "Ags Contact Stop" 312 "Ags Float Stop" 313 "Ags Absorp Stop" 314 "Ags Manual On" 315 "Ags Manual Off" 316 "Ags Auto" 317 "Ags External On" 318 "Ags External Off" 319 "Gen External On" 320 "Gen External Off" 321 "Ags External Shutdown" 322 "Ags Auto Off" 323 "Ags Dc I Start" 324 "Ags Dc I Stop" 325 "Ags Ac Power Start" 326 "Ags Ac Power Stop" 400 "Sps Manual Off" 401 "Sps Manual On" 410 "Sps Auto Off" 411 "Sps Auto On" 420 "Sps Auto Off Batt V Low" 421 "Sps Auto On Batt V Low" 422 "Sps Auto Off Batt V High" 423 "Sps Auto On Batt V High" 424 "Sps Auto Off Array V High" 425 "Sps Auto On Array V High" 426 "Sps Auto Off Batt Temp Low" 427 "Sps Auto On Batt Temp Low" 428 "Sps Auto Off Batt Temp High" 429 "Sps Auto On Batt Temp High" 430 "Sps Auto Off Heat Sink Temp High" 431 "Sps Auto On Heat Sink Temp High" 432 "Sps Auto Off Fault" 433 "Sps Auto On Fault" 434 "Aps Check Timeout" 435 "Aps Qualify Timeout" 512 "Resume From Safe" 513 "AC Fault Set" 514 "Invert Fault Set" 515 "Charge Fault Set" 516 "Charger Enable" 517 "Charger Disable" 518 "Inverter Enable" 519 "Inverter Disable" 520 "Charge Suspend On" 521 "Charge Suspend Off" 522 "AC Good" 523 "AC Bad" 524 "Load Sense Enable" 525 "Load Sense Active" 526 "Invert Active" 527 "Bulk Exit" 528 "Absorption Exit" 529 "Float Exit" 530 "Float 3-Stage Set" 531 "Float 2-Stage Set" 532 "Equalize Enable" 533 "Equalize Disable" 534 "Equalize Exit" 535 "Load Sense Disable" 536 "Sell To Grid Enabled" 537 "Sell To Grid Disabled" 538 "Grid Support Enable" 539 "Grid Support Disable" 540 "Gen Support Enable" 541 "Gen Support Disable" 542 "Peak Load Shaving Enable" 543 "Peak Load Shaving Disable" 544 "Peak Load Shaving Tod Start" 545 "Peak Load Shaving Tod Stop" 546 "Unit Off" 547 "System Absorption Exit" 548 "System Inverter Enable" 549 "System AC Good" 550 "Anti Islanding Condition" 551 "Hibernate Timeout" 552 "External Sync Error" 553 "External Suspend Request" 554 "Engaging Charger" 555 "Engaging Gen Support" 556 "Grid Tie Engage Timeout" 557 "Gen Support Engage Timeout" 558 "Charge Engage Timeout" 559 "Inverter Engage Timeout" 560 "Charge Exit Timeout" 561 "Grid Support Entry Amps" 562 "Grid Support Exit Amps" 563 "Gen Support Entry Amps" 564 "Gen Support Exit Amps" 565 "Grid Support Entry Vdc" 566 "Grid Support Exit Vdc" 567 "Low Batt Cut Off Entry Vdc" 568 "Low Batt Recharge Vdc" 569 "Low Batt Cut Off Exit Vdc" 570 "Invert To Bypass Timeout" 571 "Force Charge" 572 "System Engage Bulk Charge" 441 "SPS Auto On External Shutdown Flt" 442 "SPS Auto Off Input Over Volt Flt" 443 "SPS Auto On Input Over Volt Flt" 444 "SPS Auto Off Input Over Volt Err" 445 "SPS Auto On Input Over Volt Err" 446 "SPS Auto Off Input Over Volt Wrn" 447 "SPS Auto On Input Over Volt Wrn" 448 "SPS Auto Off Output Over Volt Err" 449 "SPS Auto On Output Over Volt Err" 450 "SPS Auto Off Output Over Volt Wrn" 451 "SPS Auto On Output Over Volt Wrn" 452 "SPS Auto Off Output Under Volt Err" 453 "SPS Auto On Output Under Volt Err" 454 "SPS Auto Off Output Under Volt Wrn" 455 "SPS Auto On Output Under Volt Wrn" 456 "SPS Auto Off Output Over Curr Err" 457 "SPS Auto On Output Over Curr Err" 458 "SPS Auto Off Batt Over Temp Err" 459 "SPS Auto On Batt Over Temp Err" 460 "SPS Auto Off Batt Over Temp Wrn" 461 "SPS Auto On Batt Over Temp Wrn" 462 "SPS Auto Off Batt Under Temp Wrn" 463 "SPS Auto On Batt Under Temp Wrn" 464 "SPS Auto Off Heatsink Over Temp Err" 465 "SPS Auto On Heatsink Over Temp Err" 466 "SPS Auto Off Heatsink Over Temp Wrn" 467 "SPS Auto On Heatsink Over Temp Wrn" 468 "SPS Auto Off Ambient Over Temp Err" 469 "SPS Auto On Ambient Over Temp Err" 470 "SPS Auto Off Ambient Over Temp Wrn" 471 "SPS Auto On Ambient Over Temp Wrn" 472 "SPS Auto Off Capacitor Over Temp Err" 473 "SPS Auto On Capacitor Over Temp Err" 474 "SPS Auto Off Fan Flt" 475 "SPS Auto On Fan Flt" 476 "SPS Auto Off Fan Err" 477 "SPS Auto On Fan Err" 478 "SPS Auto Off Input Over Curr Err" 479 "SPS Auto On Input Over Curr Err" 480 "SPS Auto Off Output Over Curr Flt" 481 "SPS Auto On Output Over Curr Flt" 482 "SPS Auto Off Network PS Flt" 483 "SPS Auto On Network PS Flt" 484 "SPS Auto Off Setup Flt" 485 "SPS Auto On Setup Flt" 38 "Clear Command User Stats" 573 "AC Good Pending" 574 "Grid Safe" 585 "PLS Time In Float Ready" 575 "Power Conversion Fault" 576 "Low Battery Support Exit" 577 "Grid Support Exit" 578 "GFS Enable" 579 "GFS Disable" 580 "Force Sell" 486 "SPS Auto On Bulk Exit" 487 "SPS Auto Off Bulk Exit" 488 "SPS Auto On Absorption Exit" 489 "SPS Auto Off Absorption Exit" 490 "SPS Auto On State Of Charge Low" 491 "SPS Auto Off State Of Charge Low" 492 "SPS Auto On Time Of Day" 493 "SPS Auto Off Time Of Day" 581 "Sell Time Of Day Start" 582 "Sell Time Of Day Stop" 583 "Aux Port Time Of Day Start" 584 "Aux Port Time Of Day Stop" ;
VAL_ 2147549952 EvtId 436 "SPS Auto Off Array V Low" 437 "SPS Auto On Array V Low" 438 "SPS Auto Off Ground Flt" 439 "SPS Auto On Ground Flt" 440 "SPS Auto Off External Shutdown Flt" 0 "None" 10 "Control Command Hibernate" 11 "Control Command Safe" 12 "Control Command Power Save" 13 "Control Command Operating" 14 "Control Command Diagnostic" 15 "Control Command Last Mode" 20 "Reset Command Reboot" 21 "Reset Command Download" 22 "Reset Command Oem" 23 "Reset Command Factory" 24 "Reset Command Reboot Clear Nv" 25 "Powered Up" 30 "Clear Command Active Faults" 31 "Clear Command Fault Log" 32 "Clear Command Active Warns" 33 "Clear Command Warn Log" 34 "Clear Command State Event Log" 35 "Clear Command Comm Stats" 36 "Clear Command Stats" 37 "Clear Command All" 40 "Date Time Configured" 50 "Warn Cleared" 51 "Fault Cleared" 52 "Fault Set" 60 "User Cfg Changed" 61 "Oem Cfg Changed" 70 "Triggered Fault" 250 "Shutdown Threshold" 251 "Shutdown Hysteresis" 252 "Warning Threshold" 253 "Warning Hysteresis" 254 "Transfer Threshold" 255 "Fan 0 Threshold" 256 "Fan 10 Threshold" 257 "Fan 20 Threshold" 258 "Fan 30 Threshold" 259 "Fan 40 Threshold" 260 "Fan 50 Threshold" 261 "Fan 60 Threshold" 262 "Fan 70 Threshold" 263 "Fan 80 Threshold" 264 "Fan 90 Threshold" 265 "Fan 100 Threshold" 266 "Relay Open Threshold" 267 "Relay Close Threshold" 268 "Charger Derating Ac In V" 269 "Charger Derating Ac In I" 270 "Charger Derating Ext Temp" 271 "Charger Derating Int Temp" 272 "Charger Derating Ripple V" 273 "Lost Ac Threshold" 274 "Lost Ac Hysteresis" 275 "Imm Shutdown Threshold" 276 "Imm Shutdown Hysteresis" 277 "Charger Shutdown Threshold" 278 "Charger Shutdown Hysteresis" 279 "Charger Warning Threshold" 280 "Charger Warning Hysteresis" 281 "Inverter Shutdown Threshold" 282 "Inverter Shutdown Hysteresis" 283 "Inverter Warning Threshold" 284 "Inverter Warning Hysteresis" 285 "Charger Derating Temp Start Point" 286 "Charger Derating Temp End Point" 287 "Charger Recharge Threshold" 300 "Ags Exercise Start" 301 "Ags Exercise Stop" 302 "Ags Quiet Time Begin" 303 "Ags Quiet Time End" 304 "Ags Battery Soc Start" 305 "Ags Battery Soc Stop" 306 "Ags Dc V Start" 307 "Ags Dc V Stop" 308 "Ags Ac I Start" 309 "Ags Ac I Stop" 310 "Ags Contact Start" 311 "Ags Contact Stop" 312 "Ags Float Stop" 313 "Ags Absorp Stop" 314 "Ags Manual On" 315 "Ags Manual Off" 316 "Ags Auto" 317 "Ags External On" 318 "Ags External Off" 319 "Gen External On" 320 "Gen External Off" 321 "Ags External Shutdown" 322 "Ags Auto Off" 323 "Ags Dc I Start" 324 "Ags Dc I Stop" 325 "Ags Ac Power Start" 326 "Ags Ac Power Stop" 400 "Sps Manual Off" 401 "Sps Manual On" 410 "Sps Auto Off" 411 "Sps Auto On" 420 "Sps Auto Off Batt V Low" 421 "Sps Auto On Batt V Low" 422 "Sps Auto Off Batt V High" 423 "Sps Auto On Batt V High" 424 "Sps Auto Off Array V High" 425 "Sps Auto On Array V High" 426 "Sps Auto Off Batt Temp Low" 427 "Sps Auto On Batt Temp Low" 428 "Sps Auto Off Batt Temp High" 429 "Sps Auto On Batt Temp High" 430 "Sps Auto Off Heat Sink Temp High" 431 "Sps Auto On Heat Sink Temp High" 432 "Sps Auto Off Fault" 433 "Sps Auto On Fault" 434 "Aps Check Timeout" 435 "Aps Qualify Timeout" 512 "Resume From Safe" 513 "AC Fault Set" 514 "Invert Fault Set" 515 "Charge Fault Set" 516 "Charger Enable" 517 "Charger Disable" 518 "Inverter Enable" 519 "Inverter Disable" 520 "Charge Suspend On" 521 "Charge Suspend Off" 522 "AC Good" 523 "AC Bad" 524 "Load Sense Enable" 525 "Load Sense Active" 526 "Invert Active" 527 "Bulk Exit" 528 "Absorption Exit" 529 "Float Exit" 530 "Float 3-Stage Set" 531 "Float 2-Stage Set" 532 "Equalize Enable" 533 "Equalize Disable" 534 "Equalize Exit" 535 "Load Sense Disable" 536 "Sell To Grid Enabled" 537 "Sell To Grid Disabled" 538 "Grid Support Enable" 539 "Grid Support Disable" 540 "Gen Support Enable" 541 "Gen Support Disable" 542 "Peak Load Shaving Enable" 543 "Peak Load Shaving Disable" 544 "Peak Load Shaving Tod Start" 545 "Peak Load Shaving Tod Stop" 546 "Unit Off" 547 "System Absorption Exit" 548 "System Inverter Enable" 549 "System AC Good" 550 "Anti Islanding Condition" 551 "Hibernate Timeout" 552 "External Sync Error" 553 "External Suspend Request" 554 "Engaging Charger" 555 "Engaging Gen Support" 556 "Grid Tie Engage Timeout" 557 "Gen Support Engage Timeout" 558 "Charge Engage Timeout" 559 "Inverter Engage Timeout" 560 "Charge Exit Timeout" 561 "Grid Support Entry Amps" 562 "Grid Support Exit Amps" 563 "Gen Support Entry Amps" 564 "Gen Support Exit Amps" 565 "Grid Support Entry Vdc" 566 "Grid Support Exit Vdc" 567 "Low Batt Cut Off Entry Vdc" 568 "Low Batt Recharge Vdc" 569 "Low Batt Cut Off Exit Vdc" 570 "Invert To Bypass Timeout" 571 "Force Charge" 572 "System Engage Bulk Charge" 441 "SPS Auto On External Shutdown Flt" 442 "SPS Auto Off Input Over Volt Flt" 443 "SPS Auto On Input Over Volt Flt" 444 "SPS Auto Off Input Over Volt Err" 445 "SPS Auto On Input Over Volt Err" 446 "SPS Auto Off Input Over Volt Wrn" 447 "SPS Auto On Input Over Volt Wrn" 448 "SPS Auto Off Output Over Volt Err" 449 "SPS Auto On Output Over Volt Err" 450 "SPS Auto Off Output Over Volt Wrn" 451 "SPS Auto On Output Over Volt Wrn" 452 "SPS Auto Off Output Under Volt Err" 453 "SPS Auto On Output Under Volt Err" 454 "SPS Auto Off Output Under Volt Wrn" 455 "SPS Auto On Output Under Volt Wrn" 456 "SPS Auto Off Output Over Curr Err" 457 "SPS Auto On Output Over Curr Err" 458 "SPS Auto Off Batt Over Temp Err" 459 "SPS Auto On Batt Over Temp Err" 460 "SPS Auto Off Batt Over Temp Wrn" 461 "SPS Auto On Batt Over Temp Wrn" 462 "SPS Auto Off Batt Under Temp Wrn" 463 "SPS Auto On Batt Under Temp Wrn" 464 "SPS Auto Off Heatsink Over Temp Err" 465 "SPS Auto On Heatsink Over Temp Err" 466 "SPS Auto Off Heatsink Over Temp Wrn" 467 "SPS Auto On Heatsink Over Temp Wrn" 468 "SPS Auto Off Ambient Over Temp Err" 469 "SPS Auto On Ambient Over Temp Err" 470 "SPS Auto Off Ambient Over Temp Wrn" 471 "SPS Auto On Ambient Over Temp Wrn" 472 "SPS Auto Off Capacitor Over Temp Err" 473 "SPS Auto On Capacitor Over Temp Err" 474 "SPS Auto Off Fan Flt" 475 "SPS Auto On Fan Flt" 476 "SPS Auto Off Fan Err" 477 "SPS Auto On Fan Err" 478 "SPS Auto Off Input Over Curr Err" 479 "SPS Auto On Input Over Curr Err" 480 "SPS Auto Off Output Over Curr Flt" 481 "SPS Auto On Output Over Curr Flt" 482 "SPS Auto Off Network PS Flt" 483 "SPS Auto On Network PS Flt" 484 "SPS Auto Off Setup Flt" 485 "SPS Auto On Setup Flt" 38 "Clear Command User Stats" 573 "AC Good Pending" 574 "Grid Safe" 585 "PLS Time In Float Ready" 575 "Power Conversion Fault" 576 "Low Battery Support Exit" 577 "Grid Support Exit" 578 "GFS Enable" 579 "GFS Disable" 580 "Force Sell" 486 "SPS Auto On Bulk Exit" 487 "SPS Auto Off Bulk Exit" 488 "SPS Auto On Absorption Exit" 489 "SPS Auto Off Absorption Exit" 490 "SPS Auto On State Of Charge Low" 491 "SPS Auto Off State Of Charge Low" 492 "SPS Auto On Time Of Day" 493 "SPS Auto Off Time Of Day" 581 "Sell Time Of Day Start" 582 "Sell Time Of Day Stop" 583 "Aux Port Time Of Day Start" 584 "Aux Port Time Of Day Stop" ;
VAL_ 2147549952 DcSrcId 0 "Invalid" 1 "None" 2 "Anonymous" 3 "HouseBatBank1" 4 "HouseBatBank2" 5 "HouseBatBank3" 6 "HouseBatBank4" 7 "HouseBatBank5" 8 "HouseBatBank6" 9 "StartBatBank1" 10 "StartBatBank2" 11 "StartBatBank3" 12 "StartBatBank4" 13 "StartBatBank5" 14 "StartBatBank6" 21 "SolarArray1" 22 "SolarArray2" 23 "SolarArray3" 24 "SolarArray4" 25 "SolarArray5" 26 "SolarArray6" 27 "SolarArray7" 28 "SolarArray8" 29 "SolarArray9" 30 "SolarArray10" 31 "SolarArray11" 32 "SolarArray12" 33 "SolarArray13" 34 "SolarArray14" 35 "SolarArray15" 36 "SolarArray16" 252 "All" 253 "Reserved" 254 "Out of Range" 255 "Data Not Available Do Not Change" ;
VAL_ 2147549952 CfgType 0 "User" 1 "OEM" 2 "Factory" 3 "Reserved" ;
VAL_ 2147550464 RefEvtId 436 "SPS Auto Off Array V Low" 437 "SPS Auto On Array V Low" 438 "SPS Auto Off Ground Flt" 439 "SPS Auto On Ground Flt" 440 "SPS Auto Off External Shutdown Flt" 0 "None" 10 "Control Command Hibernate" 11 "Control Command Safe" 12 "Control Command Power Save" 13 "Control Command Operating" 14 "Control Command Diagnostic" 15 "Control Command Last Mode" 20 "Reset Command Reboot" 21 "Reset Command Download" 22 "Reset Command Oem" 23 "Reset Command Factory" 24 "Reset Command Reboot Clear Nv" 25 "Powered Up" 30 "Clear Command Active Faults" 31 "Clear Command Fault Log" 32 "Clear Command Active Warns" 33 "Clear Command Warn Log" 34 "Clear Command State Event Log" 35 "Clear Command Comm Stats" 36 "Clear Command Stats" 37 "Clear Command All" 40 "Date Time Configured" 50 "Warn Cleared" 51 "Fault Cleared" 52 "Fault Set" 60 "User Cfg Changed" 61 "Oem Cfg Changed" 70 "Triggered Fault" 250 "Shutdown Threshold" 251 "Shutdown Hysteresis" 252 "Warning Threshold" 253 "Warning Hysteresis" 254 "Transfer Threshold" 255 "Fan 0 Threshold" 256 "Fan 10 Threshold" 257 "Fan 20 Threshold" 258 "Fan 30 Threshold" 259 "Fan 40 Threshold" 260 "Fan 50 Threshold" 261 "Fan 60 Threshold" 262 "Fan 70 Threshold" 263 "Fan 80 Threshold" 264 "Fan 90 Threshold" 265 "Fan 100 Threshold" 266 "Relay Open Threshold" 267 "Relay Close Threshold" 268 "Charger Derating Ac In V" 269 "Charger Derating Ac In I" 270 "Charger Derating Ext Temp" 271 "Charger Derating Int Temp" 272 "Charger Derating Ripple V" 273 "Lost Ac Threshold" 274 "Lost Ac Hysteresis" 275 "Imm Shutdown Threshold" 276 "Imm Shutdown Hysteresis" 277 "Charger Shutdown Threshold" 278 "Charger Shutdown Hysteresis" 279 "Charger Warning Threshold" 280 "Charger Warning Hysteresis" 281 "Inverter Shutdown Threshold" 282 "Inverter Shutdown Hysteresis" 283 "Inverter Warning Threshold" 284 "Inverter Warning Hysteresis" 285 "Charger Derating Temp Start Point" 286 "Charger Derating Temp End Point" 287 "Charger Recharge Threshold" 300 "Ags Exercise Start" 301 "Ags Exercise Stop" 302 "Ags Quiet Time Begin" 303 "Ags Quiet Time End" 304 "Ags Battery Soc Start" 305 "Ags Battery Soc Stop" 306 "Ags Dc V Start" 307 "Ags Dc V Stop" 308 "Ags Ac I Start" 309 "Ags Ac I Stop" 310 "Ags Contact Start" 311 "Ags Contact Stop" 312 "Ags Float Stop" 313 "Ags Absorp Stop" 314 "Ags Manual On" 315 "Ags Manual Off" 316 "Ags Auto" 317 "Ags External On" 318 "Ags External Off" 319 "Gen External On" 320 "Gen External Off" 321 "Ags External Shutdown" 322 "Ags Auto Off" 323 "Ags Dc I Start" 324 "Ags Dc I Stop" 325 "Ags Ac Power Start" 326 "Ags Ac Power Stop" 400 "Sps Manual Off" 401 "Sps Manual On" 410 "Sps Auto Off" 411 "Sps Auto On" 420 "Sps Auto Off Batt V Low" 421 "Sps Auto On Batt V Low" 422 "Sps Auto Off Batt V High" 423 "Sps Auto On Batt V High" 424 "Sps Auto Off Array V High" 425 "Sps Auto On Array V High" 426 "Sps Auto Off Batt Temp Low" 427 "Sps Auto On Batt Temp Low" 428 "Sps Auto Off Batt Temp High" 429 "Sps Auto On Batt Temp High" 430 "Sps Auto Off Heat Sink Temp High" 431 "Sps Auto On Heat Sink Temp High" 432 "Sps Auto Off Fault" 433 "Sps Auto On Fault" 434 "Aps Check Timeout" 435 "Aps Qualify Timeout" 512 "Resume From Safe" 513 "AC Fault Set" 514 "Invert Fault Set" 515 "Charge Fault Set" 516 "Charger Enable" 517 "Charger Disable" 518 "Inverter Enable" 519 "Inverter Disable" 520 "Charge Suspend On" 521 "Charge Suspend Off" 522 "AC Good" 523 "AC Bad" 524 "Load Sense Enable" 525 "Load Sense Active" 526 "Invert Active" 527 "Bulk Exit" 528 "Absorption Exit" 529 "Float Exit" 530 "Float 3-Stage Set" 531 "Float 2-Stage Set" 532 "Equalize Enable" 533 "Equalize Disable" 534 "Equalize Exit" 535 "Load Sense Disable" 536 "Sell To Grid Enabled" 537 "Sell To Grid Disabled" 538 "Grid Support Enable" 539 "Grid Support Disable" 540 "Gen Support Enable" 541 "Gen Support Disable" 542 "Peak Load Shaving Enable" 543 "Peak Load Shaving Disable" 544 "Peak Load Shaving Tod Start" 545 "Peak Load Shaving Tod Stop" 546 "Unit Off" 547 "System Absorption Exit" 548 "System Inverter Enable" 549 "System AC Good" 550 "Anti Islanding Condition" 551 "Hibernate Timeout" 552 "External Sync Error" 553 "External Suspend Request" 554 "Engaging Charger" 555 "Engaging Gen Support" 556 "Grid Tie Engage Timeout" 557 "Gen Support Engage Timeout" 558 "Charge Engage Timeout" 559 "Inverter Engage Timeout" 560 "Charge Exit Timeout" 561 "Grid Support Entry Amps" 562 "Grid Support Exit Amps" 563 "Gen Support Entry Amps" 564 "Gen Support Exit Amps" 565 "Grid Support Entry Vdc" 566 "Grid Support Exit Vdc" 567 "Low Batt Cut Off Entry Vdc" 568 "Low Batt Recharge Vdc" 569 "Low Batt Cut Off Exit Vdc" 570 "Invert To Bypass Timeout" 571 "Force Charge" 572 "System Engage Bulk Charge" 441 "SPS Auto On External Shutdown Flt" 442 "SPS Auto Off Input Over Volt Flt" 443 "SPS Auto On Input Over Volt Flt" 444 "SPS Auto Off Input Over Volt Err" 445 "SPS Auto On Input Over Volt Err" 446 "SPS Auto Off Input Over Volt Wrn" 447 "SPS Auto On Input Over Volt Wrn" 448 "SPS Auto Off Output Over Volt Err" 449 "SPS Auto On Output Over Volt Err" 450 "SPS Auto Off Output Over Volt Wrn" 451 "SPS Auto On Output Over Volt Wrn" 452 "SPS Auto Off Output Under Volt Err" 453 "SPS Auto On Output Under Volt Err" 454 "SPS Auto Off Output Under Volt Wrn" 455 "SPS Auto On Output Under Volt Wrn" 456 "SPS Auto Off Output Over Curr Err" 457 "SPS Auto On Output Over Curr Err" 458 "SPS Auto Off Batt Over Temp Err" 459 "SPS Auto On Batt Over Temp Err" 460 "SPS Auto Off Batt Over Temp Wrn" 461 "SPS Auto On Batt Over Temp Wrn" 462 "SPS Auto Off Batt Under Temp Wrn" 463 "SPS Auto On Batt Under Temp Wrn" 464 "SPS Auto Off Heatsink Over Temp Err" 465 "SPS Auto On Heatsink Over Temp Err" 466 "SPS Auto Off Heatsink Over Temp Wrn" 467 "SPS Auto On Heatsink Over Temp Wrn" 468 "SPS Auto Off Ambient Over Temp Err" 469 "SPS Auto On Ambient Over Temp Err" 470 "SPS Auto Off Ambient Over Temp Wrn" 471 "SPS Auto On Ambient Over Temp Wrn" 472 "SPS Auto Off Capacitor Over Temp Err" 473 "SPS Auto On Capacitor Over Temp Err" 474 "SPS Auto Off Fan Flt" 475 "SPS Auto On Fan Flt" 476 "SPS Auto Off Fan Err" 477 "SPS Auto On Fan Err" 478 "SPS Auto Off Input Over Curr Err" 479 "SPS Auto On Input Over Curr Err" 480 "SPS Auto Off Output Over Curr Flt" 481 "SPS Auto On Output Over Curr Flt" 482 "SPS Auto Off Network PS Flt" 483 "SPS Auto On Network PS Flt" 484 "SPS Auto Off Setup Flt" 485 "SPS Auto On Setup Flt" 38 "Clear Command User Stats" 573 "AC Good Pending" 574 "Grid Safe" 585 "PLS Time In Float Ready" 575 "Power Conversion Fault" 576 "Low Battery Support Exit" 577 "Grid Support Exit" 578 "GFS Enable" 579 "GFS Disable" 580 "Force Sell" 486 "SPS Auto On Bulk Exit" 487 "SPS Auto Off Bulk Exit" 488 "SPS Auto On Absorption Exit" 489 "SPS Auto Off Absorption Exit" 490 "SPS Auto On State Of Charge Low" 491 "SPS Auto Off State Of Charge Low" 492 "SPS Auto On Time Of Day" 493 "SPS Auto Off Time Of Day" 581 "Sell Time Of Day Start" 582 "Sell Time Of Day Stop" 583 "Aux Port Time Of Day Start" 584 "Aux Port Time Of Day Stop" ;
VAL_ 2147550464 EvtId 436 "SPS Auto Off Array V Low" 437 "SPS Auto On Array V Low" 438 "SPS Auto Off Ground Flt" 439 "SPS Auto On Ground Flt" 440 "SPS Auto Off External Shutdown Flt" 0 "None" 10 "Control Command Hibernate" 11 "Control Command Safe" 12 "Control Command Power Save" 13 "Control Command Operating" 14 "Control Command Diagnostic" 15 "Control Command Last Mode" 20 "Reset Command Reboot" 21 "Reset Command Download" 22 "Reset Command Oem" 23 "Reset Command Factory" 24 "Reset Command Reboot Clear Nv" 25 "Powered Up" 30 "Clear Command Active Faults" 31 "Clear Command Fault Log" 32 "Clear Command Active Warns" 33 "Clear Command Warn Log" 34 "Clear Command State Event Log" 35 "Clear Command Comm Stats" 36 "Clear Command Stats" 37 "Clear Command All" 40 "Date Time Configured" 50 "Warn Cleared" 51 "Fault Cleared" 52 "Fault Set" 60 "User Cfg Changed" 61 "Oem Cfg Changed" 70 "Triggered Fault" 250 "Shutdown Threshold" 251 "Shutdown Hysteresis" 252 "Warning Threshold" 253 "Warning Hysteresis" 254 "Transfer Threshold" 255 "Fan 0 Threshold" 256 "Fan 10 Threshold" 257 "Fan 20 Threshold" 258 "Fan 30 Threshold" 259 "Fan 40 Threshold" 260 "Fan 50 Threshold" 261 "Fan 60 Threshold" 262 "Fan 70 Threshold" 263 "Fan 80 Threshold" 264 "Fan 90 Threshold" 265 "Fan 100 Threshold" 266 "Relay Open Threshold" 267 "Relay Close Threshold" 268 "Charger Derating Ac In V" 269 "Charger Derating Ac In I" 270 "Charger Derating Ext Temp" 271 "Charger Derating Int Temp" 272 "Charger Derating Ripple V" 273 "Lost Ac Threshold" 274 "Lost Ac Hysteresis" 275 "Imm Shutdown Threshold" 276 "Imm Shutdown Hysteresis" 277 "Charger Shutdown Threshold" 278 "Charger Shutdown Hysteresis" 279 "Charger Warning Threshold" 280 "Charger Warning Hysteresis" 281 "Inverter Shutdown Threshold" 282 "Inverter Shutdown Hysteresis" 283 "Inverter Warning Threshold" 284 "Inverter Warning Hysteresis" 285 "Charger Derating Temp Start Point" 286 "Charger Derating Temp End Point" 287 "Charger Recharge Threshold" 300 "Ags Exercise Start" 301 "Ags Exercise Stop" 302 "Ags Quiet Time Begin" 303 "Ags Quiet Time End" 304 "Ags Battery Soc Start" 305 "Ags Battery Soc Stop" 306 "Ags Dc V Start" 307 "Ags Dc V Stop" 308 "Ags Ac I Start" 309 "Ags Ac I Stop" 310 "Ags Contact Start" 311 "Ags Contact Stop" 312 "Ags Float Stop" 313 "Ags Absorp Stop" 314 "Ags Manual On" 315 "Ags Manual Off" 316 "Ags Auto" 317 "Ags External On" 318 "Ags External Off" 319 "Gen External On" 320 "Gen External Off" 321 "Ags External Shutdown" 322 "Ags Auto Off" 323 "Ags Dc I Start" 324 "Ags Dc I Stop" 325 "Ags Ac Power Start" 326 "Ags Ac Power Stop" 400 "Sps Manual Off" 401 "Sps Manual On" 410 "Sps Auto Off" 411 "Sps Auto On" 420 "Sps Auto Off Batt V Low" 421 "Sps Auto On Batt V Low" 422 "Sps Auto Off Batt V High" 423 "Sps Auto On Batt V High" 424 "Sps Auto Off Array V High" 425 "Sps Auto On Array V High" 426 "Sps Auto Off Batt Temp Low" 427 "Sps Auto On Batt Temp Low" 428 "Sps Auto Off Batt Temp High" 429 "Sps Auto On Batt Temp High" 430 "Sps Auto Off Heat Sink Temp High" 431 "Sps Auto On Heat Sink Temp High" 432 "Sps Auto Off Fault" 433 "Sps Auto On Fault" 434 "Aps Check Timeout" 435 "Aps Qualify Timeout" 512 "Resume From Safe" 513 "AC Fault Set" 514 "Invert Fault Set" 515 "Charge Fault Set" 516 "Charger Enable" 517 "Charger Disable" 518 "Inverter Enable" 519 "Inverter Disable" 520 "Charge Suspend On" 521 "Charge Suspend Off" 522 "AC Good" 523 "AC Bad" 524 "Load Sense Enable" 525 "Load Sense Active" 526 "Invert Active" 527 "Bulk Exit" 528 "Absorption Exit" 529 "Float Exit" 530 "Float 3-Stage Set" 531 "Float 2-Stage Set" 532 "Equalize Enable" 533 "Equalize Disable" 534 "Equalize Exit" 535 "Load Sense Disable" 536 "Sell To Grid Enabled" 537 "Sell To Grid Disabled" 538 "Grid Support Enable" 539 "Grid Support Disable" 540 "Gen Support Enable" 541 "Gen Support Disable" 542 "Peak Load Shaving Enable" 543 "Peak Load Shaving Disable" 544 "Peak Load Shaving Tod Start" 545 "Peak Load Shaving Tod Stop" 546 "Unit Off" 547 "System Absorption Exit" 548 "System Inverter Enable" 549 "System AC Good" 550 "Anti Islanding Condition" 551 "Hibernate Timeout" 552 "External Sync Error" 553 "External Suspend Request" 554 "Engaging Charger" 555 "Engaging Gen Support" 556 "Grid Tie Engage Timeout" 557 "Gen Support Engage Timeout" 558 "Charge Engage Timeout" 559 "Inverter Engage Timeout" 560 "Charge Exit Timeout" 561 "Grid Support Entry Amps" 562 "Grid Support Exit Amps" 563 "Gen Support Entry Amps" 564 "Gen Support Exit Amps" 565 "Grid Support Entry Vdc" 566 "Grid Support Exit Vdc" 567 "Low Batt Cut Off Entry Vdc" 568 "Low Batt Recharge Vdc" 569 "Low Batt Cut Off Exit Vdc" 570 "Invert To Bypass Timeout" 571 "Force Charge" 572 "System Engage Bulk Charge" 441 "SPS Auto On External Shutdown Flt" 442 "SPS Auto Off Input Over Volt Flt" 443 "SPS Auto On Input Over Volt Flt" 444 "SPS Auto Off Input Over Volt Err" 445 "SPS Auto On Input Over Volt Err" 446 "SPS Auto Off Input Over Volt Wrn" 447 "SPS Auto On Input Over Volt Wrn" 448 "SPS Auto Off Output Over Volt Err" 449 "SPS Auto On Output Over Volt Err" 450 "SPS Auto Off Output Over Volt Wrn" 451 "SPS Auto On Output Over Volt Wrn" 452 "SPS Auto Off Output Under Volt Err" 453 "SPS Auto On Output Under Volt Err" 454 "SPS Auto Off Output Under Volt Wrn" 455 "SPS Auto On Output Under Volt Wrn" 456 "SPS Auto Off Output Over Curr Err" 457 "SPS Auto On Output Over Curr Err" 458 "SPS Auto Off Batt Over Temp Err" 459 "SPS Auto On Batt Over Temp Err" 460 "SPS Auto Off Batt Over Temp Wrn" 461 "SPS Auto On Batt Over Temp Wrn" 462 "SPS Auto Off Batt Under Temp Wrn" 463 "SPS Auto On Batt Under Temp Wrn" 464 "SPS Auto Off Heatsink Over Temp Err" 465 "SPS Auto On Heatsink Over Temp Err" 466 "SPS Auto Off Heatsink Over Temp Wrn" 467 "SPS Auto On Heatsink Over Temp Wrn" 468 "SPS Auto Off Ambient Over Temp Err" 469 "SPS Auto On Ambient Over Temp Err" 470 "SPS Auto Off Ambient Over Temp Wrn" 471 "SPS Auto On Ambient Over Temp Wrn" 472 "SPS Auto Off Capacitor Over Temp Err" 473 "SPS Auto On Capacitor Over Temp Err" 474 "SPS Auto Off Fan Flt" 475 "SPS Auto On Fan Flt" 476 "SPS Auto Off Fan Err" 477 "SPS Auto On Fan Err" 478 "SPS Auto Off Input Over Curr Err" 479 "SPS Auto On Input Over Curr Err" 480 "SPS Auto Off Output Over Curr Flt" 481 "SPS Auto On Output Over Curr Flt" 482 "SPS Auto Off Network PS Flt" 483 "SPS Auto On Network PS Flt" 484 "SPS Auto Off Setup Flt" 485 "SPS Auto On Setup Flt" 38 "Clear Command User Stats" 573 "AC Good Pending" 574 "Grid Safe" 585 "PLS Time In Float Ready" 575 "Power Conversion Fault" 576 "Low Battery Support Exit" 577 "Grid Support Exit" 578 "GFS Enable" 579 "GFS Disable" 580 "Force Sell" 486 "SPS Auto On Bulk Exit" 487 "SPS Auto Off Bulk Exit" 488 "SPS Auto On Absorption Exit" 489 "SPS Auto Off Absorption Exit" 490 "SPS Auto On State Of Charge Low" 491 "SPS Auto Off State Of Charge Low" 492 "SPS Auto On Time Of Day" 493 "SPS Auto Off Time Of Day" 581 "Sell Time Of Day Start" 582 "Sell Time Of Day Stop" 583 "Aux Port Time Of Day Start" 584 "Aux Port Time Of Day Stop" ;
VAL_ 2147550464 DcSrcId 0 "Invalid" 1 "None" 2 "Anonymous" 3 "HouseBatBank1" 4 "HouseBatBank2" 5 "HouseBatBank3" 6 "HouseBatBank4" 7 "HouseBatBank5" 8 "HouseBatBank6" 9 "StartBatBank1" 10 "StartBatBank2" 11 "StartBatBank3" 12 "StartBatBank4" 13 "StartBatBank5" 14 "StartBatBank6" 21 "SolarArray1" 22 "SolarArray2" 23 "SolarArray3" 24 "SolarArray4" 25 "SolarArray5" 26 "SolarArray6" 27 "SolarArray7" 28 "SolarArray8" 29 "SolarArray9" 30 "SolarArray10" 31 "SolarArray11" 32 "SolarArray12" 33 "SolarArray13" 34 "SolarArray14" 35 "SolarArray15" 36 "SolarArray16" 252 "All" 253 "Reserved" 254 "Out of Range" 255 "Data Not Available Do Not Change" ;
VAL_ 2147550464 CfgType 0 "User" 1 "OEM" 2 "Factory" 3 "Reserved" ;
VAL_ 2147599104 MpptEnDis 0 "Off" 1 "On" 2 "Reserved" 3 "No Change" ;
VAL_ 2147599104 DcSrcId 0 "Invalid" 1 "None" 2 "Anonymous" 3 "HouseBatBank1" 4 "HouseBatBank2" 5 "HouseBatBank3" 6 "HouseBatBank4" 7 "HouseBatBank5" 8 "HouseBatBank6" 9 "StartBatBank1" 10 "StartBatBank2" 11 "StartBatBank3" 12 "StartBatBank4" 13 "StartBatBank5" 14 "StartBatBank6" 21 "SolarArray1" 22 "SolarArray2" 23 "SolarArray3" 24 "SolarArray4" 25 "SolarArray5" 26 "SolarArray6" 27 "SolarArray7" 28 "SolarArray8" 29 "SolarArray9" 30 "SolarArray10" 31 "SolarArray11" 32 "SolarArray12" 33 "SolarArray13" 34 "SolarArray14" 35 "SolarArray15" 36 "SolarArray16" 252 "All" 253 "Reserved" 254 "Out of Range" 255 "Data Not Available Do Not Change" ;
VAL_ 2147599104 CfgType 0 "User" 1 "OEM" 2 "Factory" 3 "Reserved" ;
VAL_ 2147570432 MpptEnDis 0 "Off" 1 "On" 2 "Reserved" 3 "No Change" ;
VAL_ 2147570432 DcSrcId 0 "Invalid" 1 "None" 2 "Anonymous" 3 "HouseBatBank1" 4 "HouseBatBank2" 5 "HouseBatBank3" 6 "HouseBatBank4" 7 "HouseBatBank5" 8 "HouseBatBank6" 9 "StartBatBank1" 10 "StartBatBank2" 11 "StartBatBank3" 12 "StartBatBank4" 13 "StartBatBank5" 14 "StartBatBank6" 21 "SolarArray1" 22 "SolarArray2" 23 "SolarArray3" 24 "SolarArray4" 25 "SolarArray5" 26 "SolarArray6" 27 "SolarArray7" 28 "SolarArray8" 29 "SolarArray9" 30 "SolarArray10" 31 "SolarArray11" 32 "SolarArray12" 33 "SolarArray13" 34 "SolarArray14" 35 "SolarArray15" 36 "SolarArray16" 252 "All" 253 "Reserved" 254 "Out of Range" 255 "Data Not Available Do Not Change" ;
VAL_ 2147570432 CfgType 0 "User" 1 "OEM" 2 "Factory" 3 "Reserved" ;
VAL_ 2147549696 RefEvtId 436 "SPS Auto Off Array V Low" 437 "SPS Auto On Array V Low" 438 "SPS Auto Off Ground Flt" 439 "SPS Auto On Ground Flt" 440 "SPS Auto Off External Shutdown Flt" 0 "None" 10 "Control Command Hibernate" 11 "Control Command Safe" 12 "Control Command Power Save" 13 "Control Command Operating" 14 "Control Command Diagnostic" 15 "Control Command Last Mode" 20 "Reset Command Reboot" 21 "Reset Command Download" 22 "Reset Command Oem" 23 "Reset Command Factory" 24 "Reset Command Reboot Clear Nv" 25 "Powered Up" 30 "Clear Command Active Faults" 31 "Clear Command Fault Log" 32 "Clear Command Active Warns" 33 "Clear Command Warn Log" 34 "Clear Command State Event Log" 35 "Clear Command Comm Stats" 36 "Clear Command Stats" 37 "Clear Command All" 40 "Date Time Configured" 50 "Warn Cleared" 51 "Fault Cleared" 52 "Fault Set" 60 "User Cfg Changed" 61 "Oem Cfg Changed" 70 "Triggered Fault" 250 "Shutdown Threshold" 251 "Shutdown Hysteresis" 252 "Warning Threshold" 253 "Warning Hysteresis" 254 "Transfer Threshold" 255 "Fan 0 Threshold" 256 "Fan 10 Threshold" 257 "Fan 20 Threshold" 258 "Fan 30 Threshold" 259 "Fan 40 Threshold" 260 "Fan 50 Threshold" 261 "Fan 60 Threshold" 262 "Fan 70 Threshold" 263 "Fan 80 Threshold" 264 "Fan 90 Threshold" 265 "Fan 100 Threshold" 266 "Relay Open Threshold" 267 "Relay Close Threshold" 268 "Charger Derating Ac In V" 269 "Charger Derating Ac In I" 270 "Charger Derating Ext Temp" 271 "Charger Derating Int Temp" 272 "Charger Derating Ripple V" 273 "Lost Ac Threshold" 274 "Lost Ac Hysteresis" 275 "Imm Shutdown Threshold" 276 "Imm Shutdown Hysteresis" 277 "Charger Shutdown Threshold" 278 "Charger Shutdown Hysteresis" 279 "Charger Warning Threshold" 280 "Charger Warning Hysteresis" 281 "Inverter Shutdown Threshold" 282 "Inverter Shutdown Hysteresis" 283 "Inverter Warning Threshold" 284 "Inverter Warning Hysteresis" 285 "Charger Derating Temp Start Point" 286 "Charger Derating Temp End Point" 287 "Charger Recharge Threshold" 300 "Ags Exercise Start" 301 "Ags Exercise Stop" 302 "Ags Quiet Time Begin" 303 "Ags Quiet Time End" 304 "Ags Battery Soc Start" 305 "Ags Battery Soc Stop" 306 "Ags Dc V Start" 307 "Ags Dc V Stop" 308 "Ags Ac I Start" 309 "Ags Ac I Stop" 310 "Ags Contact Start" 311 "Ags Contact Stop" 312 "Ags Float Stop" 313 "Ags Absorp Stop" 314 "Ags Manual On" 315 "Ags Manual Off" 316 "Ags Auto" 317 "Ags External On" 318 "Ags External Off" 319 "Gen External On" 320 "Gen External Off" 321 "Ags External Shutdown" 322 "Ags Auto Off" 323 "Ags Dc I Start" 324 "Ags Dc I Stop" 325 "Ags Ac Power Start" 326 "Ags Ac Power Stop" 400 "Sps Manual Off" 401 "Sps Manual On" 410 "Sps Auto Off" 411 "Sps Auto On" 420 "Sps Auto Off Batt V Low" 421 "Sps Auto On Batt V Low" 422 "Sps Auto Off Batt V High" 423 "Sps Auto On Batt V High" 424 "Sps Auto Off Array V High" 425 "Sps Auto On Array V High" 426 "Sps Auto Off Batt Temp Low" 427 "Sps Auto On Batt Temp Low" 428 "Sps Auto Off Batt Temp High" 429 "Sps Auto On Batt Temp High" 430 "Sps Auto Off Heat Sink Temp High" 431 "Sps Auto On Heat Sink Temp High" 432 "Sps Auto Off Fault" 433 "Sps Auto On Fault" 434 "Aps Check Timeout" 435 "Aps Qualify Timeout" 512 "Resume From Safe" 513 "AC Fault Set" 514 "Invert Fault Set" 515 "Charge Fault Set" 516 "Charger Enable" 517 "Charger Disable" 518 "Inverter Enable" 519 "Inverter Disable" 520 "Charge Suspend On" 521 "Charge Suspend Off" 522 "AC Good" 523 "AC Bad" 524 "Load Sense Enable" 525 "Load Sense Active" 526 "Invert Active" 527 "Bulk Exit" 528 "Absorption Exit" 529 "Float Exit" 530 "Float 3-Stage Set" 531 "Float 2-Stage Set" 532 "Equalize Enable" 533 "Equalize Disable" 534 "Equalize Exit" 535 "Load Sense Disable" 536 "Sell To Grid Enabled" 537 "Sell To Grid Disabled" 538 "Grid Support Enable" 539 "Grid Support Disable" 540 "Gen Support Enable" 541 "Gen Support Disable" 542 "Peak Load Shaving Enable" 543 "Peak Load Shaving Disable" 544 "Peak Load Shaving Tod Start" 545 "Peak Load Shaving Tod Stop" 546 "Unit Off" 547 "System Absorption Exit" 548 "System Inverter Enable" 549 "System AC Good" 550 "Anti Islanding Condition" 551 "Hibernate Timeout" 552 "External Sync Error" 553 "External Suspend Request" 554 "Engaging Charger" 555 "Engaging Gen Support" 556 "Grid Tie Engage Timeout" 557 "Gen Support Engage Timeout" 558 "Charge Engage Timeout" 559 "Inverter Engage Timeout" 560 "Charge Exit Timeout" 561 "Grid Support Entry Amps" 562 "Grid Support Exit Amps" 563 "Gen Support Entry Amps" 564 "Gen Support Exit Amps" 565 "Grid Support Entry Vdc" 566 "Grid Support Exit Vdc" 567 "Low Batt Cut Off Entry Vdc" 568 "Low Batt Recharge Vdc" 569 "Low Batt Cut Off Exit Vdc" 570 "Invert To Bypass Timeout" 571 "Force Charge" 572 "System Engage Bulk Charge" 441 "SPS Auto On External Shutdown Flt" 442 "SPS Auto Off Input Over Volt Flt" 443 "SPS Auto On Input Over Volt Flt" 444 "SPS Auto Off Input Over Volt Err" 445 "SPS Auto On Input Over Volt Err" 446 "SPS Auto Off Input Over Volt Wrn" 447 "SPS Auto On Input Over Volt Wrn" 448 "SPS Auto Off Output Over Volt Err" 449 "SPS Auto On Output Over Volt Err" 450 "SPS Auto Off Output Over Volt Wrn" 451 "SPS Auto On Output Over Volt Wrn" 452 "SPS Auto Off Output Under Volt Err" 453 "SPS Auto On Output Under Volt Err" 454 "SPS Auto Off Output Under Volt Wrn" 455 "SPS Auto On Output Under Volt Wrn" 456 "SPS Auto Off Output Over Curr Err" 457 "SPS Auto On Output Over Curr Err" 458 "SPS Auto Off Batt Over Temp Err" 459 "SPS Auto On Batt Over Temp Err" 460 "SPS Auto Off Batt Over Temp Wrn" 461 "SPS Auto On Batt Over Temp Wrn" 462 "SPS Auto Off Batt Under Temp Wrn" 463 "SPS Auto On Batt Under Temp Wrn" 464 "SPS Auto Off Heatsink Over Temp Err" 465 "SPS Auto On Heatsink Over Temp Err" 466 "SPS Auto Off Heatsink Over Temp Wrn" 467 "SPS Auto On Heatsink Over Temp Wrn" 468 "SPS Auto Off Ambient Over Temp Err" 469 "SPS Auto On Ambient Over Temp Err" 470 "SPS Auto Off Ambient Over Temp Wrn" 471 "SPS Auto On Ambient Over Temp Wrn" 472 "SPS Auto Off Capacitor Over Temp Err" 473 "SPS Auto On Capacitor Over Temp Err" 474 "SPS Auto Off Fan Flt" 475 "SPS Auto On Fan Flt" 476 "SPS Auto Off Fan Err" 477 "SPS Auto On Fan Err" 478 "SPS Auto Off Input Over Curr Err" 479 "SPS Auto On Input Over Curr Err" 480 "SPS Auto Off Output Over Curr Flt" 481 "SPS Auto On Output Over Curr Flt" 482 "SPS Auto Off Network PS Flt" 483 "SPS Auto On Network PS Flt" 484 "SPS Auto Off Setup Flt" 485 "SPS Auto On Setup Flt" 38 "Clear Command User Stats" 573 "AC Good Pending" 574 "Grid Safe" 585 "PLS Time In Float Ready" 575 "Power Conversion Fault" 576 "Low Battery Support Exit" 577 "Grid Support Exit" 578 "GFS Enable" 579 "GFS Disable" 580 "Force Sell" 486 "SPS Auto On Bulk Exit" 487 "SPS Auto Off Bulk Exit" 488 "SPS Auto On Absorption Exit" 489 "SPS Auto Off Absorption Exit" 490 "SPS Auto On State Of Charge Low" 491 "SPS Auto Off State Of Charge Low" 492 "SPS Auto On Time Of Day" 493 "SPS Auto Off Time Of Day" 581 "Sell Time Of Day Start" 582 "Sell Time Of Day Stop" 583 "Aux Port Time Of Day Start" 584 "Aux Port Time Of Day Stop" ;
VAL_ 2147549696 EvtId 436 "SPS Auto Off Array V Low" 437 "SPS Auto On Array V Low" 438 "SPS Auto Off Ground Flt" 439 "SPS Auto On Ground Flt" 440 "SPS Auto Off External Shutdown Flt" 0 "None" 10 "Control Command Hibernate" 11 "Control Command Safe" 12 "Control Command Power Save" 13 "Control Command Operating" 14 "Control Command Diagnostic" 15 "Control Command Last Mode" 20 "Reset Command Reboot" 21 "Reset Command Download" 22 "Reset Command Oem" 23 "Reset Command Factory" 24 "Reset Command Reboot Clear Nv" 25 "Powered Up" 30 "Clear Command Active Faults" 31 "Clear Command Fault Log" 32 "Clear Command Active Warns" 33 "Clear Command Warn Log" 34 "Clear Command State Event Log" 35 "Clear Command Comm Stats" 36 "Clear Command Stats" 37 "Clear Command All" 40 "Date Time Configured" 50 "Warn Cleared" 51 "Fault Cleared" 52 "Fault Set" 60 "User Cfg Changed" 61 "Oem Cfg Changed" 70 "Triggered Fault" 250 "Shutdown Threshold" 251 "Shutdown Hysteresis" 252 "Warning Threshold" 253 "Warning Hysteresis" 254 "Transfer Threshold" 255 "Fan 0 Threshold" 256 "Fan 10 Threshold" 257 "Fan 20 Threshold" 258 "Fan 30 Threshold" 259 "Fan 40 Threshold" 260 "Fan 50 Threshold" 261 "Fan 60 Threshold" 262 "Fan 70 Threshold" 263 "Fan 80 Threshold" 264 "Fan 90 Threshold" 265 "Fan 100 Threshold" 266 "Relay Open Threshold" 267 "Relay Close Threshold" 268 "Charger Derating Ac In V" 269 "Charger Derating Ac In I" 270 "Charger Derating Ext Temp" 271 "Charger Derating Int Temp" 272 "Charger Derating Ripple V" 273 "Lost Ac Threshold" 274 "Lost Ac Hysteresis" 275 "Imm Shutdown Threshold" 276 "Imm Shutdown Hysteresis" 277 "Charger Shutdown Threshold" 278 "Charger Shutdown Hysteresis" 279 "Charger Warning Threshold" 280 "Charger Warning Hysteresis" 281 "Inverter Shutdown Threshold" 282 "Inverter Shutdown Hysteresis" 283 "Inverter Warning Threshold" 284 "Inverter Warning Hysteresis" 285 "Charger Derating Temp Start Point" 286 "Charger Derating Temp End Point" 287 "Charger Recharge Threshold" 300 "Ags Exercise Start" 301 "Ags Exercise Stop" 302 "Ags Quiet Time Begin" 303 "Ags Quiet Time End" 304 "Ags Battery Soc Start" 305 "Ags Battery Soc Stop" 306 "Ags Dc V Start" 307 "Ags Dc V Stop" 308 "Ags Ac I Start" 309 "Ags Ac I Stop" 310 "Ags Contact Start" 311 "Ags Contact Stop" 312 "Ags Float Stop" 313 "Ags Absorp Stop" 314 "Ags Manual On" 315 "Ags Manual Off" 316 "Ags Auto" 317 "Ags External On" 318 "Ags External Off" 319 "Gen External On" 320 "Gen External Off" 321 "Ags External Shutdown" 322 "Ags Auto Off" 323 "Ags Dc I Start" 324 "Ags Dc I Stop" 325 "Ags Ac Power Start" 326 "Ags Ac Power Stop" 400 "Sps Manual Off" 401 "Sps Manual On" 410 "Sps Auto Off" 411 "Sps Auto On" 420 "Sps Auto Off Batt V Low" 421 "Sps Auto On Batt V Low" 422 "Sps Auto Off Batt V High" 423 "Sps Auto On Batt V High" 424 "Sps Auto Off Array V High" 425 "Sps Auto On Array V High" 426 "Sps Auto Off Batt Temp Low" 427 "Sps Auto On Batt Temp Low" 428 "Sps Auto Off Batt Temp High" 429 "Sps Auto On Batt Temp High" 430 "Sps Auto Off Heat Sink Temp High" 431 "Sps Auto On Heat Sink Temp High" 432 "Sps Auto Off Fault" 433 "Sps Auto On Fault" 434 "Aps Check Timeout" 435 "Aps Qualify Timeout" 512 "Resume From Safe" 513 "AC Fault Set" 514 "Invert Fault Set" 515 "Charge Fault Set" 516 "Charger Enable" 517 "Charger Disable" 518 "Inverter Enable" 519 "Inverter Disable" 520 "Charge Suspend On" 521 "Charge Suspend Off" 522 "AC Good" 523 "AC Bad" 524 "Load Sense Enable" 525 "Load Sense Active" 526 "Invert Active" 527 "Bulk Exit" 528 "Absorption Exit" 529 "Float Exit" 530 "Float 3-Stage Set" 531 "Float 2-Stage Set" 532 "Equalize Enable" 533 "Equalize Disable" 534 "Equalize Exit" 535 "Load Sense Disable" 536 "Sell To Grid Enabled" 537 "Sell To Grid Disabled" 538 "Grid Support Enable" 539 "Grid Support Disable" 540 "Gen Support Enable" 541 "Gen Support Disable" 542 "Peak Load Shaving Enable" 543 "Peak Load Shaving Disable" 544 "Peak Load Shaving Tod Start" 545 "Peak Load Shaving Tod Stop" 546 "Unit Off" 547 "System Absorption Exit" 548 "System Inverter Enable" 549 "System AC Good" 550 "Anti Islanding Condition" 551 "Hibernate Timeout" 552 "External Sync Error" 553 "External Suspend Request" 554 "Engaging Charger" 555 "Engaging Gen Support" 556 "Grid Tie Engage Timeout" 557 "Gen Support Engage Timeout" 558 "Charge Engage Timeout" 559 "Inverter Engage Timeout" 560 "Charge Exit Timeout" 561 "Grid Support Entry Amps" 562 "Grid Support Exit Amps" 563 "Gen Support Entry Amps" 564 "Gen Support Exit Amps" 565 "Grid Support Entry Vdc" 566 "Grid Support Exit Vdc" 567 "Low Batt Cut Off Entry Vdc" 568 "Low Batt Recharge Vdc" 569 "Low Batt Cut Off Exit Vdc" 570 "Invert To Bypass Timeout" 571 "Force Charge" 572 "System Engage Bulk Charge" 441 "SPS Auto On External Shutdown Flt" 442 "SPS Auto Off Input Over Volt Flt" 443 "SPS Auto On Input Over Volt Flt" 444 "SPS Auto Off Input Over Volt Err" 445 "SPS Auto On Input Over Volt Err" 446 "SPS Auto Off Input Over Volt Wrn" 447 "SPS Auto On Input Over Volt Wrn" 448 "SPS Auto Off Output Over Volt Err" 449 "SPS Auto On Output Over Volt Err" 450 "SPS Auto Off Output Over Volt Wrn" 451 "SPS Auto On Output Over Volt Wrn" 452 "SPS Auto Off Output Under Volt Err" 453 "SPS Auto On Output Under Volt Err" 454 "SPS Auto Off Output Under Volt Wrn" 455 "SPS Auto On Output Under Volt Wrn" 456 "SPS Auto Off Output Over Curr Err" 457 "SPS Auto On Output Over Curr Err" 458 "SPS Auto Off Batt Over Temp Err" 459 "SPS Auto On Batt Over Temp Err" 460 "SPS Auto Off Batt Over Temp Wrn" 461 "SPS Auto On Batt Over Temp Wrn" 462 "SPS Auto Off Batt Under Temp Wrn" 463 "SPS Auto On Batt Under Temp Wrn" 464 "SPS Auto Off Heatsink Over Temp Err" 465 "SPS Auto On Heatsink Over Temp Err" 466 "SPS Auto Off Heatsink Over Temp Wrn" 467 "SPS Auto On Heatsink Over Temp Wrn" 468 "SPS Auto Off Ambient Over Temp Err" 469 "SPS Auto On Ambient Over Temp Err" 470 "SPS Auto Off Ambient Over Temp Wrn" 471 "SPS Auto On Ambient Over Temp Wrn" 472 "SPS Auto Off Capacitor Over Temp Err" 473 "SPS Auto On Capacitor Over Temp Err" 474 "SPS Auto Off Fan Flt" 475 "SPS Auto On Fan Flt" 476 "SPS Auto Off Fan Err" 477 "SPS Auto On Fan Err" 478 "SPS Auto Off Input Over Curr Err" 479 "SPS Auto On Input Over Curr Err" 480 "SPS Auto Off Output Over Curr Flt" 481 "SPS Auto On Output Over Curr Flt" 482 "SPS Auto Off Network PS Flt" 483 "SPS Auto On Network PS Flt" 484 "SPS Auto Off Setup Flt" 485 "SPS Auto On Setup Flt" 38 "Clear Command User Stats" 573 "AC Good Pending" 574 "Grid Safe" 585 "PLS Time In Float Ready" 575 "Power Conversion Fault" 576 "Low Battery Support Exit" 577 "Grid Support Exit" 578 "GFS Enable" 579 "GFS Disable" 580 "Force Sell" 486 "SPS Auto On Bulk Exit" 487 "SPS Auto Off Bulk Exit" 488 "SPS Auto On Absorption Exit" 489 "SPS Auto Off Absorption Exit" 490 "SPS Auto On State Of Charge Low" 491 "SPS Auto Off State Of Charge Low" 492 "SPS Auto On Time Of Day" 493 "SPS Auto Off Time Of Day" 581 "Sell Time Of Day Start" 582 "Sell Time Of Day Stop" 583 "Aux Port Time Of Day Start" 584 "Aux Port Time Of Day Stop" ;
VAL_ 2147549696 DcSrcId 0 "Invalid" 1 "None" 2 "Anonymous" 3 "HouseBatBank1" 4 "HouseBatBank2" 5 "HouseBatBank3" 6 "HouseBatBank4" 7 "HouseBatBank5" 8 "HouseBatBank6" 9 "StartBatBank1" 10 "StartBatBank2" 11 "StartBatBank3" 12 "StartBatBank4" 13 "StartBatBank5" 14 "StartBatBank6" 21 "SolarArray1" 22 "SolarArray2" 23 "SolarArray3" 24 "SolarArray4" 25 "SolarArray5" 26 "SolarArray6" 27 "SolarArray7" 28 "SolarArray8" 29 "SolarArray9" 30 "SolarArray10" 31 "SolarArray11" 32 "SolarArray12" 33 "SolarArray13" 34 "SolarArray14" 35 "SolarArray15" 36 "SolarArray16" 252 "All" 253 "Reserved" 254 "Out of Range" 255 "Data Not Available Do Not Change" ;
VAL_ 2147549696 CfgType 0 "User" 1 "OEM" 2 "Factory" 3 "Reserved" ;
VAL_ 2147550208 RefEvtId 436 "SPS Auto Off Array V Low" 437 "SPS Auto On Array V Low" 438 "SPS Auto Off Ground Flt" 439 "SPS Auto On Ground Flt" 440 "SPS Auto Off External Shutdown Flt" 0 "None" 10 "Control Command Hibernate" 11 "Control Command Safe" 12 "Control Command Power Save" 13 "Control Command Operating" 14 "Control Command Diagnostic" 15 "Control Command Last Mode" 20 "Reset Command Reboot" 21 "Reset Command Download" 22 "Reset Command Oem" 23 "Reset Command Factory" 24 "Reset Command Reboot Clear Nv" 25 "Powered Up" 30 "Clear Command Active Faults" 31 "Clear Command Fault Log" 32 "Clear Command Active Warns" 33 "Clear Command Warn Log" 34 "Clear Command State Event Log" 35 "Clear Command Comm Stats" 36 "Clear Command Stats" 37 "Clear Command All" 40 "Date Time Configured" 50 "Warn Cleared" 51 "Fault Cleared" 52 "Fault Set" 60 "User Cfg Changed" 61 "Oem Cfg Changed" 70 "Triggered Fault" 250 "Shutdown Threshold" 251 "Shutdown Hysteresis" 252 "Warning Threshold" 253 "Warning Hysteresis" 254 "Transfer Threshold" 255 "Fan 0 Threshold" 256 "Fan 10 Threshold" 257 "Fan 20 Threshold" 258 "Fan 30 Threshold" 259 "Fan 40 Threshold" 260 "Fan 50 Threshold" 261 "Fan 60 Threshold" 262 "Fan 70 Threshold" 263 "Fan 80 Threshold" 264 "Fan 90 Threshold" 265 "Fan 100 Threshold" 266 "Relay Open Threshold" 267 "Relay Close Threshold" 268 "Charger Derating Ac In V" 269 "Charger Derating Ac In I" 270 "Charger Derating Ext Temp" 271 "Charger Derating Int Temp" 272 "Charger Derating Ripple V" 273 "Lost Ac Threshold" 274 "Lost Ac Hysteresis" 275 "Imm Shutdown Threshold" 276 "Imm Shutdown Hysteresis" 277 "Charger Shutdown Threshold" 278 "Charger Shutdown Hysteresis" 279 "Charger Warning Threshold" 280 "Charger Warning Hysteresis" 281 "Inverter Shutdown Threshold" 282 "Inverter Shutdown Hysteresis" 283 "Inverter Warning Threshold" 284 "Inverter Warning Hysteresis" 285 "Charger Derating Temp Start Point" 286 "Charger Derating Temp End Point" 287 "Charger Recharge Threshold" 300 "Ags Exercise Start" 301 "Ags Exercise Stop" 302 "Ags Quiet Time Begin" 303 "Ags Quiet Time End" 304 "Ags Battery Soc Start" 305 "Ags Battery Soc Stop" 306 "Ags Dc V Start" 307 "Ags Dc V Stop" 308 "Ags Ac I Start" 309 "Ags Ac I Stop" 310 "Ags Contact Start" 311 "Ags Contact Stop" 312 "Ags Float Stop" 313 "Ags Absorp Stop" 314 "Ags Manual On" 315 "Ags Manual Off" 316 "Ags Auto" 317 "Ags External On" 318 "Ags External Off" 319 "Gen External On" 320 "Gen External Off" 321 "Ags External Shutdown" 322 "Ags Auto Off" 323 "Ags Dc I Start" 324 "Ags Dc I Stop" 325 "Ags Ac Power Start" 326 "Ags Ac Power Stop" 400 "Sps Manual Off" 401 "Sps Manual On" 410 "Sps Auto Off" 411 "Sps Auto On" 420 "Sps Auto Off Batt V Low" 421 "Sps Auto On Batt V Low" 422 "Sps Auto Off Batt V High" 423 "Sps Auto On Batt V High" 424 "Sps Auto Off Array V High" 425 "Sps Auto On Array V High" 426 "Sps Auto Off Batt Temp Low" 427 "Sps Auto On Batt Temp Low" 428 "Sps Auto Off Batt Temp High" 429 "Sps Auto On Batt Temp High" 430 "Sps Auto Off Heat Sink Temp High" 431 "Sps Auto On Heat Sink Temp High" 432 "Sps Auto Off Fault" 433 "Sps Auto On Fault" 434 "Aps Check Timeout" 435 "Aps Qualify Timeout" 512 "Resume From Safe" 513 "AC Fault Set" 514 "Invert Fault Set" 515 "Charge Fault Set" 516 "Charger Enable" 517 "Charger Disable" 518 "Inverter Enable" 519 "Inverter Disable" 520 "Charge Suspend On" 521 "Charge Suspend Off" 522 "AC Good" 523 "AC Bad" 524 "Load Sense Enable" 525 "Load Sense Active" 526 "Invert Active" 527 "Bulk Exit" 528 "Absorption Exit" 529 "Float Exit" 530 "Float 3-Stage Set" 531 "Float 2-Stage Set" 532 "Equalize Enable" 533 "Equalize Disable" 534 "Equalize Exit" 535 "Load Sense Disable" 536 "Sell To Grid Enabled" 537 "Sell To Grid Disabled" 538 "Grid Support Enable" 539 "Grid Support Disable" 540 "Gen Support Enable" 541 "Gen Support Disable" 542 "Peak Load Shaving Enable" 543 "Peak Load Shaving Disable" 544 "Peak Load Shaving Tod Start" 545 "Peak Load Shaving Tod Stop" 546 "Unit Off" 547 "System Absorption Exit" 548 "System Inverter Enable" 549 "System AC Good" 550 "Anti Islanding Condition" 551 "Hibernate Timeout" 552 "External Sync Error" 553 "External Suspend Request" 554 "Engaging Charger" 555 "Engaging Gen Support" 556 "Grid Tie Engage Timeout" 557 "Gen Support Engage Timeout" 558 "Charge Engage Timeout" 559 "Inverter Engage Timeout" 560 "Charge Exit Timeout" 561 "Grid Support Entry Amps" 562 "Grid Support Exit Amps" 563 "Gen Support Entry Amps" 564 "Gen Support Exit Amps" 565 "Grid Support Entry Vdc" 566 "Grid Support Exit Vdc" 567 "Low Batt Cut Off Entry Vdc" 568 "Low Batt Recharge Vdc" 569 "Low Batt Cut Off Exit Vdc" 570 "Invert To Bypass Timeout" 571 "Force Charge" 572 "System Engage Bulk Charge" 441 "SPS Auto On External Shutdown Flt" 442 "SPS Auto Off Input Over Volt Flt" 443 "SPS Auto On Input Over Volt Flt" 444 "SPS Auto Off Input Over Volt Err" 445 "SPS Auto On Input Over Volt Err" 446 "SPS Auto Off Input Over Volt Wrn" 447 "SPS Auto On Input Over Volt Wrn" 448 "SPS Auto Off Output Over Volt Err" 449 "SPS Auto On Output Over Volt Err" 450 "SPS Auto Off Output Over Volt Wrn" 451 "SPS Auto On Output Over Volt Wrn" 452 "SPS Auto Off Output Under Volt Err" 453 "SPS Auto On Output Under Volt Err" 454 "SPS Auto Off Output Under Volt Wrn" 455 "SPS Auto On Output Under Volt Wrn" 456 "SPS Auto Off Output Over Curr Err" 457 "SPS Auto On Output Over Curr Err" 458 "SPS Auto Off Batt Over Temp Err" 459 "SPS Auto On Batt Over Temp Err" 460 "SPS Auto Off Batt Over Temp Wrn" 461 "SPS Auto On Batt Over Temp Wrn" 462 "SPS Auto Off Batt Under Temp Wrn" 463 "SPS Auto On Batt Under Temp Wrn" 464 "SPS Auto Off Heatsink Over Temp Err" 465 "SPS Auto On Heatsink Over Temp Err" 466 "SPS Auto Off Heatsink Over Temp Wrn" 467 "SPS Auto On Heatsink Over Temp Wrn" 468 "SPS Auto Off Ambient Over Temp Err" 469 "SPS Auto On Ambient Over Temp Err" 470 "SPS Auto Off Ambient Over Temp Wrn" 471 "SPS Auto On Ambient Over Temp Wrn" 472 "SPS Auto Off Capacitor Over Temp Err" 473 "SPS Auto On Capacitor Over Temp Err" 474 "SPS Auto Off Fan Flt" 475 "SPS Auto On Fan Flt" 476 "SPS Auto Off Fan Err" 477 "SPS Auto On Fan Err" 478 "SPS Auto Off Input Over Curr Err" 479 "SPS Auto On Input Over Curr Err" 480 "SPS Auto Off Output Over Curr Flt" 481 "SPS Auto On Output Over Curr Flt" 482 "SPS Auto Off Network PS Flt" 483 "SPS Auto On Network PS Flt" 484 "SPS Auto Off Setup Flt" 485 "SPS Auto On Setup Flt" 38 "Clear Command User Stats" 573 "AC Good Pending" 574 "Grid Safe" 585 "PLS Time In Float Ready" 575 "Power Conversion Fault" 576 "Low Battery Support Exit" 577 "Grid Support Exit" 578 "GFS Enable" 579 "GFS Disable" 580 "Force Sell" 486 "SPS Auto On Bulk Exit" 487 "SPS Auto Off Bulk Exit" 488 "SPS Auto On Absorption Exit" 489 "SPS Auto Off Absorption Exit" 490 "SPS Auto On State Of Charge Low" 491 "SPS Auto Off State Of Charge Low" 492 "SPS Auto On Time Of Day" 493 "SPS Auto Off Time Of Day" 581 "Sell Time Of Day Start" 582 "Sell Time Of Day Stop" 583 "Aux Port Time Of Day Start" 584 "Aux Port Time Of Day Stop" ;
VAL_ 2147550208 EvtId 436 "SPS Auto Off Array V Low" 437 "SPS Auto On Array V Low" 438 "SPS Auto Off Ground Flt" 439 "SPS Auto On Ground Flt" 440 "SPS Auto Off External Shutdown Flt" 0 "None" 10 "Control Command Hibernate" 11 "Control Command Safe" 12 "Control Command Power Save" 13 "Control Command Operating" 14 "Control Command Diagnostic" 15 "Control Command Last Mode" 20 "Reset Command Reboot" 21 "Reset Command Download" 22 "Reset Command Oem" 23 "Reset Command Factory" 24 "Reset Command Reboot Clear Nv" 25 "Powered Up" 30 "Clear Command Active Faults" 31 "Clear Command Fault Log" 32 "Clear Command Active Warns" 33 "Clear Command Warn Log" 34 "Clear Command State Event Log" 35 "Clear Command Comm Stats" 36 "Clear Command Stats" 37 "Clear Command All" 40 "Date Time Configured" 50 "Warn Cleared" 51 "Fault Cleared" 52 "Fault Set" 60 "User Cfg Changed" 61 "Oem Cfg Changed" 70 "Triggered Fault" 250 "Shutdown Threshold" 251 "Shutdown Hysteresis" 252 "Warning Threshold" 253 "Warning Hysteresis" 254 "Transfer Threshold" 255 "Fan 0 Threshold" 256 "Fan 10 Threshold" 257 "Fan 20 Threshold" 258 "Fan 30 Threshold" 259 "Fan 40 Threshold" 260 "Fan 50 Threshold" 261 "Fan 60 Threshold" 262 "Fan 70 Threshold" 263 "Fan 80 Threshold" 264 "Fan 90 Threshold" 265 "Fan 100 Threshold" 266 "Relay Open Threshold" 267 "Relay Close Threshold" 268 "Charger Derating Ac In V" 269 "Charger Derating Ac In I" 270 "Charger Derating Ext Temp" 271 "Charger Derating Int Temp" 272 "Charger Derating Ripple V" 273 "Lost Ac Threshold" 274 "Lost Ac Hysteresis" 275 "Imm Shutdown Threshold" 276 "Imm Shutdown Hysteresis" 277 "Charger Shutdown Threshold" 278 "Charger Shutdown Hysteresis" 279 "Charger Warning Threshold" 280 "Charger Warning Hysteresis" 281 "Inverter Shutdown Threshold" 282 "Inverter Shutdown Hysteresis" 283 "Inverter Warning Threshold" 284 "Inverter Warning Hysteresis" 285 "Charger Derating Temp Start Point" 286 "Charger Derating Temp End Point" 287 "Charger Recharge Threshold" 300 "Ags Exercise Start" 301 "Ags Exercise Stop" 302 "Ags Quiet Time Begin" 303 "Ags Quiet Time End" 304 "Ags Battery Soc Start" 305 "Ags Battery Soc Stop" 306 "Ags Dc V Start" 307 "Ags Dc V Stop" 308 "Ags Ac I Start" 309 "Ags Ac I Stop" 310 "Ags Contact Start" 311 "Ags Contact Stop" 312 "Ags Float Stop" 313 "Ags Absorp Stop" 314 "Ags Manual On" 315 "Ags Manual Off" 316 "Ags Auto" 317 "Ags External On" 318 "Ags External Off" 319 "Gen External On" 320 "Gen External Off" 321 "Ags External Shutdown" 322 "Ags Auto Off" 323 "Ags Dc I Start" 324 "Ags Dc I Stop" 325 "Ags Ac Power Start" 326 "Ags Ac Power Stop" 400 "Sps Manual Off" 401 "Sps Manual On" 410 "Sps Auto Off" 411 "Sps Auto On" 420 "Sps Auto Off Batt V Low" 421 "Sps Auto On Batt V Low" 422 "Sps Auto Off Batt V High" 423 "Sps Auto On Batt V High" 424 "Sps Auto Off Array V High" 425 "Sps Auto On Array V High" 426 "Sps Auto Off Batt Temp Low" 427 "Sps Auto On Batt Temp Low" 428 "Sps Auto Off Batt Temp High" 429 "Sps Auto On Batt Temp High" 430 "Sps Auto Off Heat Sink Temp High" 431 "Sps Auto On Heat Sink Temp High" 432 "Sps Auto Off Fault" 433 "Sps Auto On Fault" 434 "Aps Check Timeout" 435 "Aps Qualify Timeout" 512 "Resume From Safe" 513 "AC Fault Set" 514 "Invert Fault Set" 515 "Charge Fault Set" 516 "Charger Enable" 517 "Charger Disable" 518 "Inverter Enable" 519 "Inverter Disable" 520 "Charge Suspend On" 521 "Charge Suspend Off" 522 "AC Good" 523 "AC Bad" 524 "Load Sense Enable" 525 "Load Sense Active" 526 "Invert Active" 527 "Bulk Exit" 528 "Absorption Exit" 529 "Float Exit" 530 "Float 3-Stage Set" 531 "Float 2-Stage Set" 532 "Equalize Enable" 533 "Equalize Disable" 534 "Equalize Exit" 535 "Load Sense Disable" 536 "Sell To Grid Enabled" 537 "Sell To Grid Disabled" 538 "Grid Support Enable" 539 "Grid Support Disable" 540 "Gen Support Enable" 541 "Gen Support Disable" 542 "Peak Load Shaving Enable" 543 "Peak Load Shaving Disable" 544 "Peak Load Shaving Tod Start" 545 "Peak Load Shaving Tod Stop" 546 "Unit Off" 547 "System Absorption Exit" 548 "System Inverter Enable" 549 "System AC Good" 550 "Anti Islanding Condition" 551 "Hibernate Timeout" 552 "External Sync Error" 553 "External Suspend Request" 554 "Engaging Charger" 555 "Engaging Gen Support" 556 "Grid Tie Engage Timeout" 557 "Gen Support Engage Timeout" 558 "Charge Engage Timeout" 559 "Inverter Engage Timeout" 560 "Charge Exit Timeout" 561 "Grid Support Entry Amps" 562 "Grid Support Exit Amps" 563 "Gen Support Entry Amps" 564 "Gen Support Exit Amps" 565 "Grid Support Entry Vdc" 566 "Grid Support Exit Vdc" 567 "Low Batt Cut Off Entry Vdc" 568 "Low Batt Recharge Vdc" 569 "Low Batt Cut Off Exit Vdc" 570 "Invert To Bypass Timeout" 571 "Force Charge" 572 "System Engage Bulk Charge" 441 "SPS Auto On External Shutdown Flt" 442 "SPS Auto Off Input Over Volt Flt" 443 "SPS Auto On Input Over Volt Flt" 444 "SPS Auto Off Input Over Volt Err" 445 "SPS Auto On Input Over Volt Err" 446 "SPS Auto Off Input Over Volt Wrn" 447 "SPS Auto On Input Over Volt Wrn" 448 "SPS Auto Off Output Over Volt Err" 449 "SPS Auto On Output Over Volt Err" 450 "SPS Auto Off Output Over Volt Wrn" 451 "SPS Auto On Output Over Volt Wrn" 452 "SPS Auto Off Output Under Volt Err" 453 "SPS Auto On Output Under Volt Err" 454 "SPS Auto Off Output Under Volt Wrn" 455 "SPS Auto On Output Under Volt Wrn" 456 "SPS Auto Off Output Over Curr Err" 457 "SPS Auto On Output Over Curr Err" 458 "SPS Auto Off Batt Over Temp Err" 459 "SPS Auto On Batt Over Temp Err" 460 "SPS Auto Off Batt Over Temp Wrn" 461 "SPS Auto On Batt Over Temp Wrn" 462 "SPS Auto Off Batt Under Temp Wrn" 463 "SPS Auto On Batt Under Temp Wrn" 464 "SPS Auto Off Heatsink Over Temp Err" 465 "SPS Auto On Heatsink Over Temp Err" 466 "SPS Auto Off Heatsink Over Temp Wrn" 467 "SPS Auto On Heatsink Over Temp Wrn" 468 "SPS Auto Off Ambient Over Temp Err" 469 "SPS Auto On Ambient Over Temp Err" 470 "SPS Auto Off Ambient Over Temp Wrn" 471 "SPS Auto On Ambient Over Temp Wrn" 472 "SPS Auto Off Capacitor Over Temp Err" 473 "SPS Auto On Capacitor Over Temp Err" 474 "SPS Auto Off Fan Flt" 475 "SPS Auto On Fan Flt" 476 "SPS Auto Off Fan Err" 477 "SPS Auto On Fan Err" 478 "SPS Auto Off Input Over Curr Err" 479 "SPS Auto On Input Over Curr Err" 480 "SPS Auto Off Output Over Curr Flt" 481 "SPS Auto On Output Over Curr Flt" 482 "SPS Auto Off Network PS Flt" 483 "SPS Auto On Network PS Flt" 484 "SPS Auto Off Setup Flt" 485 "SPS Auto On Setup Flt" 38 "Clear Command User Stats" 573 "AC Good Pending" 574 "Grid Safe" 585 "PLS Time In Float Ready" 575 "Power Conversion Fault" 576 "Low Battery Support Exit" 577 "Grid Support Exit" 578 "GFS Enable" 579 "GFS Disable" 580 "Force Sell" 486 "SPS Auto On Bulk Exit" 487 "SPS Auto Off Bulk Exit" 488 "SPS Auto On Absorption Exit" 489 "SPS Auto Off Absorption Exit" 490 "SPS Auto On State Of Charge Low" 491 "SPS Auto Off State Of Charge Low" 492 "SPS Auto On Time Of Day" 493 "SPS Auto Off Time Of Day" 581 "Sell Time Of Day Start" 582 "Sell Time Of Day Stop" 583 "Aux Port Time Of Day Start" 584 "Aux Port Time Of Day Stop" ;
VAL_ 2147550208 DcSrcId 0 "Invalid" 1 "None" 2 "Anonymous" 3 "HouseBatBank1" 4 "HouseBatBank2" 5 "HouseBatBank3" 6 "HouseBatBank4" 7 "HouseBatBank5" 8 "HouseBatBank6" 9 "StartBatBank1" 10 "StartBatBank2" 11 "StartBatBank3" 12 "StartBatBank4" 13 "StartBatBank5" 14 "StartBatBank6" 21 "SolarArray1" 22 "SolarArray2" 23 "SolarArray3" 24 "SolarArray4" 25 "SolarArray5" 26 "SolarArray6" 27 "SolarArray7" 28 "SolarArray8" 29 "SolarArray9" 30 "SolarArray10" 31 "SolarArray11" 32 "SolarArray12" 33 "SolarArray13" 34 "SolarArray14" 35 "SolarArray15" 36 "SolarArray16" 252 "All" 253 "Reserved" 254 "Out of Range" 255 "Data Not Available Do Not Change" ;
VAL_ 2147550208 CfgType 0 "User" 1 "OEM" 2 "Factory" 3 "Reserved" ;
VAL_ 2147556608 DcSrcId 0 "Invalid" 1 "None" 2 "Anonymous" 3 "HouseBatBank1" 4 "HouseBatBank2" 5 "HouseBatBank3" 6 "HouseBatBank4" 7 "HouseBatBank5" 8 "HouseBatBank6" 9 "StartBatBank1" 10 "StartBatBank2" 11 "StartBatBank3" 12 "StartBatBank4" 13 "StartBatBank5" 14 "StartBatBank6" 21 "SolarArray1" 22 "SolarArray2" 23 "SolarArray3" 24 "SolarArray4" 25 "SolarArray5" 26 "SolarArray6" 27 "SolarArray7" 28 "SolarArray8" 29 "SolarArray9" 30 "SolarArray10" 31 "SolarArray11" 32 "SolarArray12" 33 "SolarArray13" 34 "SolarArray14" 35 "SolarArray15" 36 "SolarArray16" 252 "All" 253 "Reserved" 254 "Out of Range" 255 "Data Not Available Do Not Change" ;
VAL_ 2147556608 CfgType 0 "User" 1 "OEM" 2 "Factory" 3 "Reserved" ;
VAL_ 2147556608 BattType 0 "Flooded" 1 "Gel" 2 "AGM" 3 "Custom" 4 "Deep Cycle" 5 "Optima" 253 "Reserved" 254 "Out Of Range" 255 "Data Not Available Do Not Change" 6 "Lithium Ion" ;
VAL_ 2147556608 BattChem 0 "Invalid" 1 "Lead Acid" 2 "LiIon" 3 "NiCad" 4 "ZnO" 5 "NiMH" 6 "PbCa" 253 "Reserved" 254 "Out Of Range" 255 "Data Not Available Do Not Change" ;
VAL_ 2147612681 LocalDow 0 "Sunday" 1 "Monday" 2 "Tuesday" 3 "Wednesday" 4 "Thursday" 5 "Friday" 6 "Saturday" 7 "Invalid" ;
VAL_ 2147567616 LocalDow 0 "Sunday" 1 "Monday" 2 "Tuesday" 3 "Wednesday" 4 "Thursday" 5 "Friday" 6 "Saturday" 7 "Invalid" ;
VAL_ 2147567616 CfgType 0 "User" 1 "OEM" 2 "Factory" 3 "Reserved" ;
VAL_ 2147575552 DcSrcId 0 "Invalid" 1 "None" 2 "Anonymous" 3 "HouseBatBank1" 4 "HouseBatBank2" 5 "HouseBatBank3" 6 "HouseBatBank4" 7 "HouseBatBank5" 8 "HouseBatBank6" 9 "StartBatBank1" 10 "StartBatBank2" 11 "StartBatBank3" 12 "StartBatBank4" 13 "StartBatBank5" 14 "StartBatBank6" 21 "SolarArray1" 22 "SolarArray2" 23 "SolarArray3" 24 "SolarArray4" 25 "SolarArray5" 26 "SolarArray6" 27 "SolarArray7" 28 "SolarArray8" 29 "SolarArray9" 30 "SolarArray10" 31 "SolarArray11" 32 "SolarArray12" 33 "SolarArray13" 34 "SolarArray14" 35 "SolarArray15" 36 "SolarArray16" 252 "All" 253 "Reserved" 254 "Out of Range" 255 "Data Not Available Do Not Change" ;
VAL_ 2147565568 DesiredMode 0 "Hibernate" 1 "Power Save" 2 "Safe" 3 "Operating" 4 "Diagnostic" 5 "Remote Power Off" 252 "Last Mode" 253 "Reserved" 254 "Out Of Range" 255 "Data Not Available Do Not Change" ;
VAL_ 2147559424 WarnId 34 "DC Over Voltage Warning 2" 35 "Heatsink Over Temperature Warning 1" 0 "Transistor Over Temperature Warning 1" 1 "Transistor Over Temperature Warning 2" 2 "Capacitor Over Temperature Warning 1" 3 "Transformer Over Temperature Warning 1" 4 "Battery Over Temperature Warning 1" 5 "Ambient Over Temperature Warning 1" 6 "AC Output Overload Warning" 7 "Auto Restart After Fault Enabled Warning" 9 "Battery Sensor Not Present Warning" 10 "Battery Sensor Short Warning" 11 "DC Over Voltage Warning 1" 12 "DC Under Voltage Warning 1" 13 "AC Line 1 Input Over Voltage Warning" 14 "AC Line 1 Input Under Voltage Warning" 15 "AC Line 2 Input Over Voltage Warning" 16 "AC Line 2 Input Under Voltage Warning" 18 "Cannot Equalize" 19 "Equalization Terminated Abnormally" 20 "AC Output Over Voltage Warning 1" 21 "AC Output Under Voltage Warning 1" 22 "AC Output Over Voltage Warning 2" 23 "AC Output Under Voltage Warning 2" 24 "Generator Line 1 Input Over Voltage Warning" 25 "Generator Line 1 Input Under Voltage Warning" 26 "Generator Line 2 Input Over Voltage Warning" 27 "Generator Line 2 Input Under Voltage Warning" 28 "Generator Line 1 Input Over Frequency Warning" 29 "Generator Line 1 Input Under Frequency Warning" 30 "Generator Line 2 Input Over Frequency Warning" 31 "Generator Line 2 Input Under Frequency Warning" 32 "AC Input L1 L2 120 Over Frequency Warning" 33 "AC Input L1 L2 120 Under Frequency Warning" 200 "External Genset Shutdown Warning" 201 "External Genset Startup Warning" 202 "Unable To Start Genset Warning" 203 "Reached Max Run Time Warning" 204 "Max Genset Cycle With No Intervention Warning" 205 "Gen On Not Ags" 206 "Orphaned Auto Start Trigger" 207 "Orphaned Auto Stop Trigger" 208 "No Auto Triggers Defined" 209 "Gen Off Not Ags" 250 "Failed To Set Value Warning" 251 "Confirm Equalization Warning" 252 "Confirm Restore Defaults Warning" 253 "Aborted Equalization" 254 "Failed To Set Value Due To System Mode" 255 "Clock Not Set" 256 "Device Lost" 257 "New Device" 258 "Node Instance Duplicated" 500 "Lost Network Connection" 501 "Defaults Restored On Powerup Warning" 502 "Missing Expected Status" 599 "Associations Invalid" 8189 "Reserved" 8190 "Out Of Range" 8191 "No Change Data NA" ;
VAL_ 2147559424 ListItem 0 "None" 1 "Fault Log" 2 "Active Faults" 4 "Warning Log" 8 "Active Warnings" 16 "State Event Log" 32 "Comm Stats" 64 "Stats" 255 "All" 128 "User Stats" ;
VAL_ 2147559424 FaultId 73 "DC Over Current Shutdown 2" 74 "DC Over Voltage Shutdown 3" 0 "Transistor Over Temperature Shutdown 1" 1 "Transistor Over Temperature Shutdown 2" 2 "Capacitor Over Temperature Shutdown 1" 3 "Transformer Over Temperature Shutdown 1" 4 "Battery Over Temperature Shutdown 1" 5 "Ambient Over Temperature Shutdown 1" 6 "AC Output Overload Shutdown 1" 7 "AC Output Overload Peak Current Shutdown 1" 8 "Neutral Loss Shutdown" 9 "DC Over Voltage Shutdown 1" 10 "DC Under Voltage Immediate Shutdown 1" 11 "DC Under Voltage Shutdown 1" 12 "AC Input Line 1 Over Voltage Shutdown" 13 "AC Input Line 1 Under Voltage Shutdown" 14 "AC Input Line 2 Over Voltage Shutdown" 15 "AC Input Line 2 Under Voltage Shutdown" 16 "AC Input Line 1 Over Frequency Shutdown" 17 "AC Input Line 1 Under Frequency Shutdown" 18 "AC Input Line 2 Over Frequency Shutdown" 19 "AC Input Line 2 Under Frequency Shutdown" 22 "ADC Conversion Timeout" 23 "AC Output Over Voltage Shutdown 1" 24 "AC Output Under Voltage Shutdown 1" 25 "APS Over Voltage" 26 "APS Under Voltage" 27 "OPS Over Voltage" 28 "OPS Under Voltage" 29 "AC Backfeed Shutdown" 30 "Battery Under Temperature" 31 "Echo Charger Short Circuit" 32 "Echo Charger Reverse Polarity" 33 "Echo Charger Input Over Voltage" 34 "Echo Charger Input Under Voltage" 35 "Echo Charger Over Temperature" 36 "Echo Charger Under Temperature" 37 "Echo Charger Not Communicating" 40 "Lost Interprocessor Communications" 41 "Dead Battery Charge Timeout" 42 "AC Output Over Voltage Shutdown 2" 43 "AC Output Under Voltage Shutdown 2" 44 "Generator Line 1 Input Over Voltage Shutdown" 45 "Generator Line 1 Input Under Voltage Shutdown" 46 "Generator Line 2 Input Over Voltage Shutdown" 47 "Generator Line 2 Input Under Voltage Shutdown" 48 "Generator Line 1 Input Over Frequency Shutdown" 49 "Generator Line 1 Input Under Frequency Shutdown" 50 "Generator Line 2 Input Over Frequency Shutdown" 51 "Generator Line 2 Input Under Frequency Shutdown" 52 "AC Input L1 L2 120 Over Frequency Shutdown" 53 "AC Input L1 L2 120 Under Frequency Shutdown" 54 "APS 1 Off" 55 "Heatsink 1 Over Temperature Shutdown" 56 "Ground Fault" 57 "External Shutdown" 58 "AC Output 1 Voltage Shutdown" 59 "AC Output 1 Frequency Shutdown" 60 "AC Output 1 Impedance Shutdown" 61 "Reconnecting 1" 62 "DC-DC 1 Saturated" 63 "User Shutdown" 64 "Neutral Over Current 1" 65 "Over Voltage Antiislanding" 66 "Under Voltage Antiislanding" 67 "Over Frequency Antiislanding" 68 "Under Frequency Antiislanding" 69 "Battery Conflicting Setup" 70 "DC Over Voltage Shutdown 2" 71 "DC Over Current Shutdown" 72 "SPS Overload" 200 "Max Start Retries" 201 "Unable to Stop Generator" 203 "Gen Stop by Ext Shutdown" 250 "Clock Not Set" 251 "Device Lost" 252 "New Device" 500 "Silicon Serial ID Failure" 501 "Non-Volatile Error" 502 "Watchdog Reset" 503 "Real-time Clock Failure" 504 "Lost Network Connection" 505 "Controller Failure" 506 "Wrong Fault Identifier" 507 "Wrong Warning Identifier" 508 "Invalid Interrupt" 599 "Associations Invalid" 8189 "Reserved" 8190 "Out Of Range" 8191 "No Change Data NA" 75 "Fan Problem 1" 76 "Fan Problem 2" 77 "DC Over Current Shutdown 3" 78 "DC Over Current Shutdown 4" 79 "Fan Problem 3" 80 "Fan Problem 4" 81 "Fan Problem 5" 82 "Network Power Supply Failure" 83 "Battery Discharge Over Current" ;
VAL_ 2147610638 OpState 768 "Not Charging" 769 "Bulk" 770 "Absorption" 771 "Overcharge" 772 "Equalize" 773 "Float" 774 "No Float" 775 "Constant VI" 776 "Charger Disabled" 777 "Qualifying AC" 778 "Qualifying APS" 779 "Engaging Charger" 780 "Charge Fault" 781 "Charger Suspend" 782 "AC Good" 783 "APS Good" 784 "AC Fault" 785 "Charge" 786 "Absorption Exit Pending" 787 "Ground Fault" 788 "AC Good Pending" 789 "Load Shaving" 790 "AC Support" 791 "AC Coupled" 792 "AC Coupled Bulk" 793 "AC Coupled Absorption" 794 "AC Coupled Float" 795 "AC Coupled No Float" 796 "External BMS" 797 "Load Sense" ;
VAL_ 2147610638 EqlzPending 0 "Off" 1 "On" 2 "Error" 3 "Unknown" ;
VAL_ 2147610638 DcSrcId 0 "Invalid" 1 "None" 2 "Anonymous" 3 "HouseBatBank1" 4 "HouseBatBank2" 5 "HouseBatBank3" 6 "HouseBatBank4" 7 "HouseBatBank5" 8 "HouseBatBank6" 9 "StartBatBank1" 10 "StartBatBank2" 11 "StartBatBank3" 12 "StartBatBank4" 13 "StartBatBank5" 14 "StartBatBank6" 21 "SolarArray1" 22 "SolarArray2" 23 "SolarArray3" 24 "SolarArray4" 25 "SolarArray5" 26 "SolarArray6" 27 "SolarArray7" 28 "SolarArray8" 29 "SolarArray9" 30 "SolarArray10" 31 "SolarArray11" 32 "SolarArray12" 33 "SolarArray13" 34 "SolarArray14" 35 "SolarArray15" 36 "SolarArray16" 252 "All" 253 "Reserved" 254 "Out of Range" 255 "Data Not Available Do Not Change" ;
VAL_ 2147610638 ChgMode 0 "Standalone" 1 "Primary" 2 "Secondary" 3 "Echo" 253 "Reserved" 254 "Out of Range" 255 "Data Not Available Do Not Change" ;
VAL_ 2147610638 ChgEnDis 0 "Off" 1 "On" 2 "Error" 3 "Unknown" ;
VAL_ 2147610638 ChgAlgorithm 0 "Invalid" 1 "3Stage" 2 "2StageNoFloat" 3 "CVCC" 4 "Trickle" 253 "Reserved" 254 "Out of Range" 255 "Data Not Available Do Not Change" 5 "4Stage" ;
VAL_ 2147610638 BattTempSensorPresent 0 "Off" 1 "On" 2 "Error" 3 "Unknown" ;
VAL_ 2147610658 TempSensId 0 "Transistor 1" 1 "Transistor 2" 2 "Transistor 3" 3 "Transistor 4" 10 "Capacitor 1" 11 "Capacitor 2" 12 "Capacitor 3" 13 "Capacitor 4" 20 "Transformer 1" 21 "Transformer 2" 22 "Transformer 3" 23 "Transformer 4" 30 "Ambient 1" 31 "Ambient 2" 32 "Ambient 3" 33 "Ambient 4" 34 "Shunt 1" 35 "Shunt 2" 36 "Shunt 3" 37 "Shunt 4" 38 "Heatsink 1" 39 "Heatsink 2" 40 "Heatsink 3" 41 "Heatsink 4" 253 "Reserved" 254 "Out of Range" 255 "Data Not Available Do Not Change" ;
VAL_ 2147610659 TempSensId 0 "Battery 1" 1 "Battery 2" 2 "Battery 3" 3 "Battery 4" 4 "Battery 5" 5 "Battery 6" 10 "Ambient 1" 11 "Ambient 2" 12 "Ambient 3" 13 "Ambient 4" 14 "Shunt 1" 15 "Shunt 2" 16 "Shunt 3" 17 "Shunt 4" 253 "Reserved" 254 "Out of Range" 255 "Data Not Available Do Not Change" ;
VAL_ 2147610817 PreviousPeriod 0 "Life" 1 "Year" 2 "Month" 3 "Week" 4 "Day" 5 "Hour" 6 "User" ;
VAL_ 2147610817 DcSrcId 0 "Invalid" 1 "None" 2 "Anonymous" 3 "HouseBatBank1" 4 "HouseBatBank2" 5 "HouseBatBank3" 6 "HouseBatBank4" 7 "HouseBatBank5" 8 "HouseBatBank6" 9 "StartBatBank1" 10 "StartBatBank2" 11 "StartBatBank3" 12 "StartBatBank4" 13 "StartBatBank5" 14 "StartBatBank6" 21 "SolarArray1" 22 "SolarArray2" 23 "SolarArray3" 24 "SolarArray4" 25 "SolarArray5" 26 "SolarArray6" 27 "SolarArray7" 28 "SolarArray8" 29 "SolarArray9" 30 "SolarArray10" 31 "SolarArray11" 32 "SolarArray12" 33 "SolarArray13" 34 "SolarArray14" 35 "SolarArray15" 36 "SolarArray16" 252 "All" 253 "Reserved" 254 "Out of Range" 255 "Data Not Available Do Not Change" ;
VAL_ 2147610657 DcSrcId 0 "Invalid" 1 "None" 2 "Anonymous" 3 "HouseBatBank1" 4 "HouseBatBank2" 5 "HouseBatBank3" 6 "HouseBatBank4" 7 "HouseBatBank5" 8 "HouseBatBank6" 9 "StartBatBank1" 10 "StartBatBank2" 11 "StartBatBank3" 12 "StartBatBank4" 13 "StartBatBank5" 14 "StartBatBank6" 21 "SolarArray1" 22 "SolarArray2" 23 "SolarArray3" 24 "SolarArray4" 25 "SolarArray5" 26 "SolarArray6" 27 "SolarArray7" 28 "SolarArray8" 29 "SolarArray9" 30 "SolarArray10" 31 "SolarArray11" 32 "SolarArray12" 33 "SolarArray13" 34 "SolarArray14" 35 "SolarArray15" 36 "SolarArray16" 252 "All" 253 "Reserved" 254 "Out of Range" 255 "Data Not Available Do Not Change" ;
VAL_ 2147610814 PreviousPeriod 0 "Life" 1 "Year" 2 "Month" 3 "Week" 4 "Day" 5 "Hour" 6 "User" ;
VAL_ 2147610814 DcSrcId 0 "Invalid" 1 "None" 2 "Anonymous" 3 "HouseBatBank1" 4 "HouseBatBank2" 5 "HouseBatBank3" 6 "HouseBatBank4" 7 "HouseBatBank5" 8 "HouseBatBank6" 9 "StartBatBank1" 10 "StartBatBank2" 11 "StartBatBank3" 12 "StartBatBank4" 13 "StartBatBank5" 14 "StartBatBank6" 21 "SolarArray1" 22 "SolarArray2" 23 "SolarArray3" 24 "SolarArray4" 25 "SolarArray5" 26 "SolarArray6" 27 "SolarArray7" 28 "SolarArray8" 29 "SolarArray9" 30 "SolarArray10" 31 "SolarArray11" 32 "SolarArray12" 33 "SolarArray13" 34 "SolarArray14" 35 "SolarArray15" 36 "SolarArray16" 252 "All" 253 "Reserved" 254 "Out of Range" 255 "Data Not Available Do Not Change" ;
VAL_ 2147610816 PreviousPeriod 0 "Life" 1 "Year" 2 "Month" 3 "Week" 4 "Day" 5 "Hour" 6 "User" ;
VAL_ 2147610816 Line 0 "Invalid" 1 "Line 1" 2 "Line 2" 3 "Line 3" 253 "Reserved" 254 "Out Of Range" 255 "Data Not Available Do Not Change" ;
VAL_ 2147610816 AcSrcId 0 "Invalid" 1 "None" 2 "Anonymous" 3 "Shore1" 4 "Shore2" 5 "Shore3" 6 "Shore4" 7 "Shore5" 8 "Shore6" 9 "Shore7" 10 "Shore8" 11 "Shore9" 12 "Shore10" 13 "Shore11" 14 "Shore12" 15 "Shore13" 16 "Shore14" 17 "Shore15" 18 "Shore16" 19 "Gen1" 20 "Gen2" 21 "Gen3" 22 "Gen4" 23 "Gen5" 24 "Gen6" 25 "Gen7" 26 "Gen8" 27 "Gen9" 28 "Gen10" 29 "Gen11" 30 "Gen12" 31 "Gen13" 32 "Gen14" 33 "Gen15" 34 "Gen16" 35 "AC1" 36 "AC2" 37 "AC3" 38 "AC4" 39 "AC5" 40 "AC6" 41 "AC7" 42 "AC8" 43 "AC9" 44 "AC10" 45 "AC11" 46 "AC12" 47 "AC13" 48 "AC14" 49 "AC15" 50 "AC16" 51 "AC Load1" 52 "AC Load2" 53 "AC Load3" 54 "AC Load4" 55 "AC Load5" 56 "AC Load6" 57 "AC Load7" 58 "AC Load8" 59 "AC Load9" 60 "AC Load10" 61 "AC Load11" 62 "AC Load12" 63 "AC Load13" 64 "AC Load14" 65 "AC Load15" 66 "AC Load16" 67 "Grid1" 68 "Grid2" 69 "Grid3" 70 "Grid4" 71 "Grid5" 72 "Grid6" 73 "Grid7" 74 "Grid8" 75 "Grid9" 76 "Grid10" 77 "Grid11" 78 "Grid12" 79 "Grid13" 80 "Grid14" 81 "Grid15" 82 "Grid16" 252 "All" 253 "Reserved" 254 "Out Of Range" 255 "Data Not Available Do Not Change" ;
VAL_ 2147610650 Line 0 "Invalid" 1 "Line 1" 2 "Line 2" 3 "Line 3" 253 "Reserved" 254 "Out Of Range" 255 "Data Not Available Do Not Change" ;
VAL_ 2147610650 AcSrcId 0 "Invalid" 1 "None" 2 "Anonymous" 3 "Shore1" 4 "Shore2" 5 "Shore3" 6 "Shore4" 7 "Shore5" 8 "Shore6" 9 "Shore7" 10 "Shore8" 11 "Shore9" 12 "Shore10" 13 "Shore11" 14 "Shore12" 15 "Shore13" 16 "Shore14" 17 "Shore15" 18 "Shore16" 19 "Gen1" 20 "Gen2" 21 "Gen3" 22 "Gen4" 23 "Gen5" 24 "Gen6" 25 "Gen7" 26 "Gen8" 27 "Gen9" 28 "Gen10" 29 "Gen11" 30 "Gen12" 31 "Gen13" 32 "Gen14" 33 "Gen15" 34 "Gen16" 35 "AC1" 36 "AC2" 37 "AC3" 38 "AC4" 39 "AC5" 40 "AC6" 41 "AC7" 42 "AC8" 43 "AC9" 44 "AC10" 45 "AC11" 46 "AC12" 47 "AC13" 48 "AC14" 49 "AC15" 50 "AC16" 51 "AC Load1" 52 "AC Load2" 53 "AC Load3" 54 "AC Load4" 55 "AC Load5" 56 "AC Load6" 57 "AC Load7" 58 "AC Load8" 59 "AC Load9" 60 "AC Load10" 61 "AC Load11" 62 "AC Load12" 63 "AC Load13" 64 "AC Load14" 65 "AC Load15" 66 "AC Load16" 67 "Grid1" 68 "Grid2" 69 "Grid3" 70 "Grid4" 71 "Grid5" 72 "Grid6" 73 "Grid7" 74 "Grid8" 75 "Grid9" 76 "Grid10" 77 "Grid11" 78 "Grid12" 79 "Grid13" 80 "Grid14" 81 "Grid15" 82 "Grid16" 252 "All" 253 "Reserved" 254 "Out Of Range" 255 "Data Not Available Do Not Change" ;
VAL_ 2147600384 ForceChgState 0 "Do Not Care" 1 "Bulk" 2 "Float" 3 "No Float" 253 "Reserved" 254 "Out Of Range" 255 "Data Not Available Do Not Change" ;
VAL_ 2147600384 DcSrcId 0 "Invalid" 1 "None" 2 "Anonymous" 3 "HouseBatBank1" 4 "HouseBatBank2" 5 "HouseBatBank3" 6 "HouseBatBank4" 7 "HouseBatBank5" 8 "HouseBatBank6" 9 "StartBatBank1" 10 "StartBatBank2" 11 "StartBatBank3" 12 "StartBatBank4" 13 "StartBatBank5" 14 "StartBatBank6" 21 "SolarArray1" 22 "SolarArray2" 23 "SolarArray3" 24 "SolarArray4" 25 "SolarArray5" 26 "SolarArray6" 27 "SolarArray7" 28 "SolarArray8" 29 "SolarArray9" 30 "SolarArray10" 31 "SolarArray11" 32 "SolarArray12" 33 "SolarArray13" 34 "SolarArray14" 35 "SolarArray15" 36 "SolarArray16" 252 "All" 253 "Reserved" 254 "Out of Range" 255 "Data Not Available Do Not Change" ;
VAL_ 2147600384 ChgEnDis 0 "Off" 1 "On" 2 "Reserved" 3 "No Change" ;
VAL_ 2147562752 DcSrcId 0 "Invalid" 1 "None" 2 "Anonymous" 3 "HouseBatBank1" 4 "HouseBatBank2" 5 "HouseBatBank3" 6 "HouseBatBank4" 7 "HouseBatBank5" 8 "HouseBatBank6" 9 "StartBatBank1" 10 "StartBatBank2" 11 "StartBatBank3" 12 "StartBatBank4" 13 "StartBatBank5" 14 "StartBatBank6" 21 "SolarArray1" 22 "SolarArray2" 23 "SolarArray3" 24 "SolarArray4" 25 "SolarArray5" 26 "SolarArray6" 27 "SolarArray7" 28 "SolarArray8" 29 "SolarArray9" 30 "SolarArray10" 31 "SolarArray11" 32 "SolarArray12" 33 "SolarArray13" 34 "SolarArray14" 35 "SolarArray15" 36 "SolarArray16" 252 "All" 253 "Reserved" 254 "Out of Range" 255 "Data Not Available Do Not Change" ;
VAL_ 2147562752 ChgEnDis 0 "Off" 1 "On" 2 "Reserved" 3 "No Change" ;
VAL_ 2147555584 DcSrcId 0 "Invalid" 1 "None" 2 "Anonymous" 3 "HouseBatBank1" 4 "HouseBatBank2" 5 "HouseBatBank3" 6 "HouseBatBank4" 7 "HouseBatBank5" 8 "HouseBatBank6" 9 "StartBatBank1" 10 "StartBatBank2" 11 "StartBatBank3" 12 "StartBatBank4" 13 "StartBatBank5" 14 "StartBatBank6" 21 "SolarArray1" 22 "SolarArray2" 23 "SolarArray3" 24 "SolarArray4" 25 "SolarArray5" 26 "SolarArray6" 27 "SolarArray7" 28 "SolarArray8" 29 "SolarArray9" 30 "SolarArray10" 31 "SolarArray11" 32 "SolarArray12" 33 "SolarArray13" 34 "SolarArray14" 35 "SolarArray15" 36 "SolarArray16" 252 "All" 253 "Reserved" 254 "Out of Range" 255 "Data Not Available Do Not Change" ;
VAL_ 2147555584 CfgType 0 "User" 1 "OEM" 2 "Factory" 3 "Reserved" ;
VAL_ 2147555584 BattType 0 "Flooded" 1 "Gel" 2 "AGM" 3 "Custom" 4 "Deep Cycle" 5 "Optima" 253 "Reserved" 254 "Out Of Range" 255 "Data Not Available Do Not Change" 6 "Lithium Ion" ;
VAL_ 2147559168 CfgType 0 "User" 1 "OEM" 2 "Factory" 3 "Reserved" ;
VAL_ 2147555840 DcSrcId 0 "Invalid" 1 "None" 2 "Anonymous" 3 "HouseBatBank1" 4 "HouseBatBank2" 5 "HouseBatBank3" 6 "HouseBatBank4" 7 "HouseBatBank5" 8 "HouseBatBank6" 9 "StartBatBank1" 10 "StartBatBank2" 11 "StartBatBank3" 12 "StartBatBank4" 13 "StartBatBank5" 14 "StartBatBank6" 21 "SolarArray1" 22 "SolarArray2" 23 "SolarArray3" 24 "SolarArray4" 25 "SolarArray5" 26 "SolarArray6" 27 "SolarArray7" 28 "SolarArray8" 29 "SolarArray9" 30 "SolarArray10" 31 "SolarArray11" 32 "SolarArray12" 33 "SolarArray13" 34 "SolarArray14" 35 "SolarArray15" 36 "SolarArray16" 252 "All" 253 "Reserved" 254 "Out of Range" 255 "Data Not Available Do Not Change" ;
VAL_ 2147555840 CfgType 0 "User" 1 "OEM" 2 "Factory" 3 "Reserved" ;
VAL_ 2147555840 BattType 0 "Flooded" 1 "Gel" 2 "AGM" 3 "Custom" 4 "Deep Cycle" 5 "Optima" 253 "Reserved" 254 "Out Of Range" 255 "Data Not Available Do Not Change" 6 "Lithium Ion" ;
VAL_ 2147556096 EqlzSuppEnDis 0 "Off" 1 "On" 2 "Reserved" 3 "No Change" ;
VAL_ 2147556096 DcSrcId 0 "Invalid" 1 "None" 2 "Anonymous" 3 "HouseBatBank1" 4 "HouseBatBank2" 5 "HouseBatBank3" 6 "HouseBatBank4" 7 "HouseBatBank5" 8 "HouseBatBank6" 9 "StartBatBank1" 10 "StartBatBank2" 11 "StartBatBank3" 12 "StartBatBank4" 13 "StartBatBank5" 14 "StartBatBank6" 21 "SolarArray1" 22 "SolarArray2" 23 "SolarArray3" 24 "SolarArray4" 25 "SolarArray5" 26 "SolarArray6" 27 "SolarArray7" 28 "SolarArray8" 29 "SolarArray9" 30 "SolarArray10" 31 "SolarArray11" 32 "SolarArray12" 33 "SolarArray13" 34 "SolarArray14" 35 "SolarArray15" 36 "SolarArray16" 252 "All" 253 "Reserved" 254 "Out of Range" 255 "Data Not Available Do Not Change" ;
VAL_ 2147556096 CfgType 0 "User" 1 "OEM" 2 "Factory" 3 "Reserved" ;
VAL_ 2147556096 BattType 0 "Flooded" 1 "Gel" 2 "AGM" 3 "Custom" 4 "Deep Cycle" 5 "Optima" 253 "Reserved" 254 "Out Of Range" 255 "Data Not Available Do Not Change" 6 "Lithium Ion" ;
VAL_ 2147556352 DcSrcId 0 "Invalid" 1 "None" 2 "Anonymous" 3 "HouseBatBank1" 4 "HouseBatBank2" 5 "HouseBatBank3" 6 "HouseBatBank4" 7 "HouseBatBank5" 8 "HouseBatBank6" 9 "StartBatBank1" 10 "StartBatBank2" 11 "StartBatBank3" 12 "StartBatBank4" 13 "StartBatBank5" 14 "StartBatBank6" 21 "SolarArray1" 22 "SolarArray2" 23 "SolarArray3" 24 "SolarArray4" 25 "SolarArray5" 26 "SolarArray6" 27 "SolarArray7" 28 "SolarArray8" 29 "SolarArray9" 30 "SolarArray10" 31 "SolarArray11" 32 "SolarArray12" 33 "SolarArray13" 34 "SolarArray14" 35 "SolarArray15" 36 "SolarArray16" 252 "All" 253 "Reserved" 254 "Out of Range" 255 "Data Not Available Do Not Change" ;
VAL_ 2147556352 CfgType 0 "User" 1 "OEM" 2 "Factory" 3 "Reserved" ;
VAL_ 2147556352 BattType 0 "Flooded" 1 "Gel" 2 "AGM" 3 "Custom" 4 "Deep Cycle" 5 "Optima" 253 "Reserved" 254 "Out Of Range" 255 "Data Not Available Do Not Change" 6 "Lithium Ion" ;
VAL_ 2147555072 DcSrcId 0 "Invalid" 1 "None" 2 "Anonymous" 3 "HouseBatBank1" 4 "HouseBatBank2" 5 "HouseBatBank3" 6 "HouseBatBank4" 7 "HouseBatBank5" 8 "HouseBatBank6" 9 "StartBatBank1" 10 "StartBatBank2" 11 "StartBatBank3" 12 "StartBatBank4" 13 "StartBatBank5" 14 "StartBatBank6" 21 "SolarArray1" 22 "SolarArray2" 23 "SolarArray3" 24 "SolarArray4" 25 "SolarArray5" 26 "SolarArray6" 27 "SolarArray7" 28 "SolarArray8" 29 "SolarArray9" 30 "SolarArray10" 31 "SolarArray11" 32 "SolarArray12" 33 "SolarArray13" 34 "SolarArray14" 35 "SolarArray15" 36 "SolarArray16" 252 "All" 253 "Reserved" 254 "Out of Range" 255 "Data Not Available Do Not Change" ;
VAL_ 2147555072 CfgType 0 "User" 1 "OEM" 2 "Factory" 3 "Reserved" ;
VAL_ 2147555072 BattType 0 "Flooded" 1 "Gel" 2 "AGM" 3 "Custom" 4 "Deep Cycle" 5 "Optima" 253 "Reserved" 254 "Out Of Range" 255 "Data Not Available Do Not Change" 6 "Lithium Ion" ;
VAL_ 2147555328 DcSrcId 0 "Invalid" 1 "None" 2 "Anonymous" 3 "HouseBatBank1" 4 "HouseBatBank2" 5 "HouseBatBank3" 6 "HouseBatBank4" 7 "HouseBatBank5" 8 "HouseBatBank6" 9 "StartBatBank1" 10 "StartBatBank2" 11 "StartBatBank3" 12 "StartBatBank4" 13 "StartBatBank5" 14 "StartBatBank6" 21 "SolarArray1" 22 "SolarArray2" 23 "SolarArray3" 24 "SolarArray4" 25 "SolarArray5" 26 "SolarArray6" 27 "SolarArray7" 28 "SolarArray8" 29 "SolarArray9" 30 "SolarArray10" 31 "SolarArray11" 32 "SolarArray12" 33 "SolarArray13" 34 "SolarArray14" 35 "SolarArray15" 36 "SolarArray16" 252 "All" 253 "Reserved" 254 "Out of Range" 255 "Data Not Available Do Not Change" ;
VAL_ 2147555328 CfgType 0 "User" 1 "OEM" 2 "Factory" 3 "Reserved" ;
VAL_ 2147555328 BattType 0 "Flooded" 1 "Gel" 2 "AGM" 3 "Custom" 4 "Deep Cycle" 5 "Optima" 253 "Reserved" 254 "Out Of Range" 255 "Data Not Available Do Not Change" 6 "Lithium Ion" ;
